[part 2 of 3: package /AR_SIGNALER_SWC]
AUTOSAR XML (schema 3.1.1)
package /AR_SIGNALER_SWC
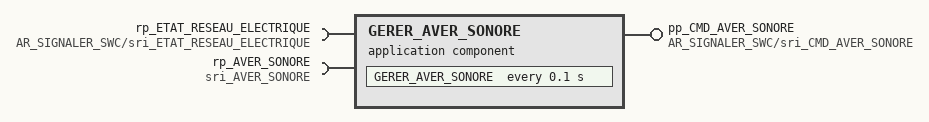
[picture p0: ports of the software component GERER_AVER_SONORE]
  application software component type GERER_AVER_SONORE
    require port rp_ETAT_RESEAU_ELECTRIQUE: unqueued-receiver-com-spec{data-element=sri_ETAT_RESEAU_ELECTRIQUE/ETAT_RESEAU_ELECTRIQUE, handle-invalid=KEEP, init-value=cst_UInt8_init/uint8_init, resync-time=0.0}, required-interface=AR_SIGNALER_SWC/sri_ETAT_RESEAU_ELECTRIQUE
    require port rp_AVER_SONORE: unqueued-receiver-com-spec{data-element=AVER_SONORE, handle-invalid=KEEP, init-value=cst_Boolean_init/boolean_init, resync-time=0.0}, required-interface=sri_AVER_SONORE
    provide port pp_CMD_AVER_SONORE: unqueued-sender-com-spec{data-element=sri_CMD_AVER_SONORE/CMD_AVER_SONORE, init-value=cst_Boolean_init/boolean_init}, provided-interface=AR_SIGNALER_SWC/sri_CMD_AVER_SONORE
  composition type SIGNALER_S1
    require port rp_ETAT_RESEAU_ELECTRIQUE: unqueued-receiver-com-spec{data-element=sri_ETAT_RESEAU_ELECTRIQUE/ETAT_RESEAU_ELECTRIQUE, handle-invalid=KEEP, init-value=cst_UInt8_init/uint8_init, resync-time=0.0}, required-interface=AR_SIGNALER_SWC/sri_ETAT_RESEAU_ELECTRIQUE
    require port rp_AVER_SONORE: unqueued-receiver-com-spec{data-element=AVER_SONORE, handle-invalid=KEEP, init-value=cst_Boolean_init/boolean_init, resync-time=0.0}, required-interface=sri_AVER_SONORE
    provide port pp_CMD_AVER_SONORE: unqueued-sender-com-spec{data-element=sri_CMD_AVER_SONORE/CMD_AVER_SONORE, init-value=cst_Boolean_init/boolean_init}, provided-interface=AR_SIGNALER_SWC/sri_CMD_AVER_SONORE
    6 x require port:
      rp_TYPE_DE_BOITE: unqueued-receiver-com-spec{data-element=TYPE_DE_BOITE, handle-invalid=KEEP, init-value=cst_UInt8_init/uint8_init, resync-time=0.0}, required-interface=sri_TYPE_DE_BOITE
      rp_SECU_FEUX_STOP_PAR_CTC_FREIN2: unqueued-receiver-com-spec{data-element=SECU_FEUX_STOP_PAR_CTC_FREIN2, handle-invalid=KEEP, init-value=cst_Boolean_init/boolean_init, resync-time=0.0}, required-interface=sri_SECU_FEUX_STOP_PAR_CTC_FREIN2
      rp_ETAT_PRINCIP_SEV: unqueued-receiver-com-spec{data-element=sri_ETAT_PRINCIP_SEV/ETAT_PRINCIP_SEV, handle-invalid=KEEP, init-value=cst_UInt8_init/uint8_init, resync-time=0.0}, required-interface=AR_SIGNALER_SWC/sri_ETAT_PRINCIP_SEV
      rp_APPUI_PEDALE_FREIN: unqueued-receiver-com-spec{data-element=APPUI_PEDALE_FREIN, handle-invalid=KEEP, init-value=cst_Boolean_init/boolean_init, resync-time=0.0}, required-interface=sri_APPUI_PEDALE_FREIN
      rp_CONTACT_FREIN2: unqueued-receiver-com-spec{data-element=CONTACT_FREIN2, handle-invalid=KEEP, init-value=cst_Boolean_init/boolean_init, resync-time=0.0}, required-interface=sri_CONTACT_FREIN2
      rp_CDE_APC: unqueued-receiver-com-spec{data-element=sri_CDE_APC/CDE_APC, handle-invalid=KEEP, init-value=cst_Boolean_init/boolean_init, resync-time=0.0}, required-interface=AR_SIGNALER_SWC/sri_CDE_APC
    provide port pp_CMD_FEUX_STOP: unqueued-sender-com-spec{data-element=CMD_FEUX_STOP, init-value=cst_Boolean_init/boolean_init}, provided-interface=sri_CMD_FEUX_STOP
    require port rp_ETAT_MA: unqueued-receiver-com-spec{data-element=ETAT_MA, handle-invalid=KEEP, init-value=cst_Boolean_init/boolean_init, resync-time=0.0}, required-interface=sri_ETAT_MA
    provide port pp_CMD_FEUX_MAR: unqueued-sender-com-spec{data-element=CMD_FEUX_MAR, init-value=cst_Boolean_init/boolean_init}, provided-interface=sri_CMD_FEUX_MAR
    component GERER_AVER_SONORE: type=GERER_AVER_SONORE
    component GERER_FX_STOP: type=GERER_FX_STOP
    component GERER_FX_MA: type=GERER_FX_MA
    delegate GERER_AVER_SONORE.rp_ETAT_RESEAU_ELECTRIQUE <-> outer port SIGNALER_S1/rp_ETAT_RESEAU_ELECTRIQUE
    delegate GERER_AVER_SONORE.rp_AVER_SONORE <-> outer port SIGNALER_S1/rp_AVER_SONORE
    delegate GERER_AVER_SONORE.pp_CMD_AVER_SONORE <-> outer port SIGNALER_S1/pp_CMD_AVER_SONORE
    delegate GERER_FX_STOP.rp_ETAT_PRINCIP_SEV <-> outer port SIGNALER_S1/rp_ETAT_PRINCIP_SEV
    delegate GERER_FX_STOP.rp_ETAT_RESEAU_ELECTRIQUE <-> outer port SIGNALER_S1/rp_ETAT_RESEAU_ELECTRIQUE
    delegate GERER_FX_STOP.rp_APPUI_PEDALE_FREIN <-> outer port SIGNALER_S1/rp_APPUI_PEDALE_FREIN
    delegate GERER_FX_STOP.rp_SECU_FEUX_STOP_PAR_CTC_FREIN2 <-> outer port SIGNALER_S1/rp_SECU_FEUX_STOP_PAR_CTC_FREIN2
    delegate GERER_FX_STOP.rp_CONTACT_FREIN2 <-> outer port SIGNALER_S1/rp_CONTACT_FREIN2
    delegate GERER_FX_STOP.rp_CDE_APC <-> outer port SIGNALER_S1/rp_CDE_APC
    delegate GERER_FX_STOP.pp_CMD_FEUX_STOP <-> outer port SIGNALER_S1/pp_CMD_FEUX_STOP
    delegate GERER_FX_MA.rp_ETAT_PRINCIP_SEV <-> outer port SIGNALER_S1/rp_ETAT_PRINCIP_SEV
    delegate GERER_FX_MA.rp_ETAT_RESEAU_ELECTRIQUE <-> outer port SIGNALER_S1/rp_ETAT_RESEAU_ELECTRIQUE
    delegate GERER_FX_MA.rp_TYPE_DE_BOITE <-> outer port SIGNALER_S1/rp_TYPE_DE_BOITE
    delegate GERER_FX_MA.rp_ETAT_MA <-> outer port SIGNALER_S1/rp_ETAT_MA
    delegate GERER_FX_MA.pp_CMD_FEUX_MAR <-> outer port SIGNALER_S1/pp_CMD_FEUX_MAR
  composition type SIGNALER
    4 x require port:
      rp_ETAT_PRINCIP_SEV: unqueued-receiver-com-spec{data-element=sri_ETAT_PRINCIP_SEV/ETAT_PRINCIP_SEV, handle-invalid=KEEP, init-value=cst_UInt8_init/uint8_init, resync-time=0.0}, required-interface=AR_SIGNALER_SWC/sri_ETAT_PRINCIP_SEV
      rp_ETAT_RESEAU_ELECTRIQUE: unqueued-receiver-com-spec{data-element=sri_ETAT_RESEAU_ELECTRIQUE/ETAT_RESEAU_ELECTRIQUE, handle-invalid=KEEP, init-value=cst_UInt8_init/uint8_init, resync-time=0.0}, required-interface=AR_SIGNALER_SWC/sri_ETAT_RESEAU_ELECTRIQUE
      rp_CDE_APC: unqueued-receiver-com-spec{data-element=sri_CDE_APC/CDE_APC, handle-invalid=KEEP, init-value=cst_Boolean_init/boolean_init, resync-time=0.0}, required-interface=AR_SIGNALER_SWC/sri_CDE_APC
      rp_AVER_SONORE: unqueued-receiver-com-spec{data-element=AVER_SONORE, handle-invalid=KEEP, init-value=cst_Boolean_init/boolean_init, resync-time=0.0}, required-interface=sri_AVER_SONORE
    provide port pp_CMD_AVER_SONORE: unqueued-sender-com-spec{data-element=sri_CMD_AVER_SONORE/CMD_AVER_SONORE, init-value=cst_Boolean_init/boolean_init}, provided-interface=AR_SIGNALER_SWC/sri_CMD_AVER_SONORE
    4 x require port:
      rp_DMD_LOCAL_TELECMD: unqueued-receiver-com-spec{data-element=sri_DMD_LOCAL_TELECMD/DMD_LOCAL_TELECMD, handle-invalid=KEEP, init-value=cst_Boolean_init/boolean_init, resync-time=0.0}, required-interface=AR_SIGNALER_SWC/sri_DMD_LOCAL_TELECMD
      rp_ETAT_CPO_COND: unqueued-receiver-com-spec{data-element=sri_ETAT_CPO_COND/ETAT_CPO_COND, handle-invalid=KEEP, init-value=cst_Boolean_init/boolean_init, resync-time=0.0}, required-interface=AR_SIGNALER_SWC/sri_ETAT_CPO_COND
      rp_ETAT_CONDA: unqueued-receiver-com-spec{data-element=sri_ETAT_CONDA/ETAT_CONDA, handle-invalid=KEEP, init-value=cst_UInt8_init/uint8_init, resync-time=0.0}, required-interface=AR_SIGNALER_SWC/sri_ETAT_CONDA
      rp_TYPE_CONDA: unqueued-receiver-com-spec{data-element=sri_TYPE_CONDA/TYPE_CONDA, handle-invalid=KEEP, init-value=cst_UInt8_init/uint8_init, resync-time=0.0}, required-interface=AR_SIGNALER_SWC/sri_TYPE_CONDA
    provide port pp_ETAT_FEUX_DETRESSE: unqueued-sender-com-spec{data-element=sri_ETAT_FEUX_DETRESSE/ETAT_FEUX_DETRESSE, init-value=cst_Boolean_init/boolean_init}, provided-interface=AR_SIGNALER_SWC/sri_ETAT_FEUX_DETRESSE
    provide port pp_ETAT_FEUX_DIURNES: unqueued-sender-com-spec{data-element=sri_ETAT_FEUX_DIURNES/ETAT_FEUX_DIURNES, init-value=cst_Boolean_init/boolean_init}, provided-interface=AR_SIGNALER_SWC/sri_ETAT_FEUX_DIURNES
    provide port pp_ETAT_FEUX_POSITION: unqueued-sender-com-spec{data-element=sri_ETAT_FEUX_POSITION/ETAT_FEUX_POSITION, init-value=cst_Boolean_init/boolean_init}, provided-interface=AR_SIGNALER_SWC/sri_ETAT_FEUX_POSITION
    6 x require port:
      rp_APPUI_PEDALE_FREIN: unqueued-receiver-com-spec{data-element=APPUI_PEDALE_FREIN, handle-invalid=KEEP, init-value=cst_Boolean_init/boolean_init, resync-time=0.0}, required-interface=sri_APPUI_PEDALE_FREIN
      rp_DMD_FEUX_DETRESSE: unqueued-receiver-com-spec{data-element=DMD_FEUX_DETRESSE, handle-invalid=KEEP, init-value=cst_Boolean_init/boolean_init, resync-time=0.0}, required-interface=sri_DMD_FEUX_DETRESSE
      rp_DIAG_CLIGNO_AVD: unqueued-receiver-com-spec{data-element=DIAG_CLIGNO_AVD, handle-invalid=KEEP, init-value=cst_UInt8_init/uint8_init, resync-time=0.0}, required-interface=sri_DIAG_CLIGNO_AVD
      rp_DIAG_CLIGNO_ARD: unqueued-receiver-com-spec{data-element=DIAG_CLIGNO_ARD, handle-invalid=KEEP, init-value=cst_UInt8_init/uint8_init, resync-time=0.0}, required-interface=sri_DIAG_CLIGNO_ARD
      rp_DIAG_CLIGNO_AVG: unqueued-receiver-com-spec{data-element=DIAG_CLIGNO_AVG, handle-invalid=KEEP, init-value=cst_UInt8_init/uint8_init, resync-time=0.0}, required-interface=sri_DIAG_CLIGNO_AVG
      rp_DIAG_CLIGNO_ARG: unqueued-receiver-com-spec{data-element=DIAG_CLIGNO_ARG, handle-invalid=KEEP, init-value=cst_UInt8_init/uint8_init, resync-time=0.0}, required-interface=sri_DIAG_CLIGNO_ARG
    16 x provide port:
      pp_PILOTAGE_CLIGNO_AVG: unqueued-sender-com-spec{data-element=PILOTAGE_CLIGNO_AVG, init-value=cst_Boolean_init/boolean_init}, provided-interface=sri_PILOTAGE_CLIGNO_AVG
      pp_PILOTAGE_CLIGNO_AVD: unqueued-sender-com-spec{data-element=PILOTAGE_CLIGNO_AVD, init-value=cst_Boolean_init/boolean_init}, provided-interface=sri_PILOTAGE_CLIGNO_AVD
      pp_P_LED_SIGN_PUSH_FEU_DET: unqueued-sender-com-spec{data-element=P_LED_SIGN_PUSH_FEU_DET, init-value=cst_Boolean_init/boolean_init}, provided-interface=sri_P_LED_SIGN_PUSH_FEU_DET
      pp_CMD_CLIGNO_ARG: unqueued-sender-com-spec{data-element=CMD_CLIGNO_ARG, init-value=cst_Boolean_init/boolean_init}, provided-interface=sri_CMD_CLIGNO_ARG
      pp_CMD_CLIGNO_ARD: unqueued-sender-com-spec{data-element=CMD_CLIGNO_ARD, init-value=cst_Boolean_init/boolean_init}, provided-interface=sri_CMD_CLIGNO_ARD
      pp_ETAT_CLIGNOTANT_G: unqueued-sender-com-spec{data-element=sri_ETAT_CLIGNOTANT_G/ETAT_CLIGNOTANT_G, init-value=cst_Boolean_init/boolean_init}, provided-interface=AR_SIGNALER_SWC/sri_ETAT_CLIGNOTANT_G
      pp_ETAT_CLIGNOTANT_D: unqueued-sender-com-spec{data-element=sri_ETAT_CLIGNOTANT_D/ETAT_CLIGNOTANT_D, init-value=cst_Boolean_init/boolean_init}, provided-interface=AR_SIGNALER_SWC/sri_ETAT_CLIGNOTANT_D
      pp_P_SON_SIGN_FX_CLIGNO_CLIC: unqueued-sender-com-spec{data-element=sri_P_SON_SIGN_FX_CLIGNO_CLIC/P_SON_SIGN_FX_CLIGNO_CLIC, init-value=cst_Boolean_init/boolean_init}, provided-interface=AR_SIGNALER_SWC/sri_P_SON_SIGN_FX_CLIGNO_CLIC
      pp_P_SON_SIGN_FX_CLIGNO_CLAC: unqueued-sender-com-spec{data-element=sri_P_SON_SIGN_FX_CLIGNO_CLAC/P_SON_SIGN_FX_CLIGNO_CLAC, init-value=cst_Boolean_init/boolean_init}, provided-interface=AR_SIGNALER_SWC/sri_P_SON_SIGN_FX_CLIGNO_CLAC
      pp_P_SON_SIGN_FX_CLIGNO_CLIC_R: unqueued-sender-com-spec{data-element=sri_P_SON_SIGN_FX_CLIGNO_CLIC_R/P_SON_SIGN_FX_CLIGNO_CLIC_R, init-value=cst_Boolean_init/boolean_init}, provided-interface=AR_SIGNALER_SWC/sri_P_SON_SIGN_FX_CLIGNO_CLIC_R
      pp_P_SON_SIGN_FX_CLIGNO_CLAC_R: unqueued-sender-com-spec{data-element=sri_P_SON_SIGN_FX_CLIGNO_CLAC_R/P_SON_SIGN_FX_CLIGNO_CLAC_R, init-value=cst_Boolean_init/boolean_init}, provided-interface=AR_SIGNALER_SWC/sri_P_SON_SIGN_FX_CLIGNO_CLAC_R
      pp_P_SON_SIGN_FX_CLIGNO_CLIC_REL: unqueued-sender-com-spec{data-element=sri_P_SON_SIGN_FX_CLIGNO_CLIC_REL/P_SON_SIGN_FX_CLIGNO_CLIC_REL, init-value=cst_Boolean_init/boolean_init}, provided-interface=AR_SIGNALER_SWC/sri_P_SON_SIGN_FX_CLIGNO_CLIC_REL
      pp_P_SON_SIGN_FX_CLIGNO_CLAC_REL: unqueued-sender-com-spec{data-element=sri_P_SON_SIGN_FX_CLIGNO_CLAC_REL/P_SON_SIGN_FX_CLIGNO_CLAC_REL, init-value=cst_Boolean_init/boolean_init}, provided-interface=AR_SIGNALER_SWC/sri_P_SON_SIGN_FX_CLIGNO_CLAC_REL
      pp_P_SON_SIGN_FX_CLIGNO_CLIC_R_REL: unqueued-sender-com-spec{data-element=sri_P_SON_SIGN_FX_CLIGNO_CLIC_R_REL/P_SON_SIGN_FX_CLIGNO_CLIC_R_REL, init-value=cst_Boolean_init/boolean_init}, provided-interface=AR_SIGNALER_SWC/sri_P_SON_SIGN_FX_CLIGNO_CLIC_R_REL
      pp_P_SON_SIGN_FX_CLIGNO_CLAC_R_REL: unqueued-sender-com-spec{data-element=sri_P_SON_SIGN_FX_CLIGNO_CLAC_R_REL/P_SON_SIGN_FX_CLIGNO_CLAC_R_REL, init-value=cst_Boolean_init/boolean_init}, provided-interface=AR_SIGNALER_SWC/sri_P_SON_SIGN_FX_CLIGNO_CLAC_R_REL
      pp_P_SON_SIGN_OUBLI_FEUX: unqueued-sender-com-spec{data-element=sri_P_SON_SIGN_OUBLI_FEUX/P_SON_SIGN_OUBLI_FEUX, init-value=cst_Boolean_init/boolean_init}, provided-interface=AR_SIGNALER_SWC/sri_P_SON_SIGN_OUBLI_FEUX
    require port rp_DMD_ALLUMAGE_FEUX_POSITION: unqueued-receiver-com-spec{data-element=DMD_ALLUMAGE_FEUX_POSITION, handle-invalid=KEEP, init-value=cst_Boolean_init/boolean_init, resync-time=0.0}, required-interface=sri_DMD_ALLUMAGE_FEUX_POSITION
    provide port pp_PILOTAGE_FEU_DIURNE_DEDIE_D: unqueued-sender-com-spec{data-element=PILOTAGE_FEU_DIURNE_DEDIE_D, init-value=cst_Boolean_init/boolean_init}, provided-interface=sri_PILOTAGE_FEU_DIURNE_DEDIE_D
    provide port pp_PILOTAGE_FEU_DIURNE_DEDIE_G: unqueued-sender-com-spec{data-element=PILOTAGE_FEU_DIURNE_DEDIE_G, init-value=cst_Boolean_init/boolean_init}, provided-interface=sri_PILOTAGE_FEU_DIURNE_DEDIE_G
    provide port pp_P_TEM_SIGN_FX_DIURNES: unqueued-sender-com-spec{data-element=P_TEM_SIGN_FX_DIURNES, init-value=cst_Boolean_init/boolean_init}, provided-interface=sri_P_TEM_SIGN_FX_DIURNES
    4 x require port:
      rp_VITESSE_LONGITUDINALE: unqueued-receiver-com-spec{data-element=sri_VITESSE_LONGITUDINALE/VITESSE_LONGITUDINALE, handle-invalid=KEEP, init-value=cst_UInt16_init/uint16_init, resync-time=0.0}, required-interface=AR_SIGNALER_SWC/sri_VITESSE_LONGITUDINALE
      rp_ETAT_ANTIBR_AV: unqueued-receiver-com-spec{data-element=ETAT_ANTIBR_AV, handle-invalid=KEEP, init-value=cst_Boolean_init/boolean_init, resync-time=0.0}, required-interface=sri_ETAT_ANTIBR_AV
      rp_DMD_FEUX_CROISEMENT_AAF: unqueued-receiver-com-spec{data-element=DMD_FEUX_CROISEMENT_AAF, handle-invalid=KEEP, init-value=cst_Boolean_init/boolean_init, resync-time=0.0}, required-interface=sri_DMD_FEUX_CROISEMENT_AAF
      rp_TYPE_REVEIL_BAGUE_ECLAIRAGE: unqueued-receiver-com-spec{data-element=TYPE_REVEIL_BAGUE_ECLAIRAGE, handle-invalid=KEEP, init-value=cst_Boolean_init/boolean_init, resync-time=0.0}, required-interface=sri_TYPE_REVEIL_BAGUE_ECLAIRAGE
    7 x provide port:
      pp_PILOTAGE_FEUX_POSITION_AVD: unqueued-sender-com-spec{data-element=PILOTAGE_FEUX_POSITION_AVD, init-value=cst_Boolean_init/boolean_init}, provided-interface=sri_PILOTAGE_FEUX_POSITION_AVD
      pp_PILOTAGE_FEUX_POSITION_AVG: unqueued-sender-com-spec{data-element=PILOTAGE_FEUX_POSITION_AVG, init-value=cst_Boolean_init/boolean_init}, provided-interface=sri_PILOTAGE_FEUX_POSITION_AVG
      pp_CMD_FEUX_POSITION_AR: unqueued-sender-com-spec{data-element=CMD_FEUX_POSITION_AR, init-value=cst_UInt8_init/uint8_init}, provided-interface=sri_CMD_FEUX_POSITION_AR
      pp_P_TEM_SIGN_FX_POS: unqueued-sender-com-spec{data-element=P_TEM_SIGN_FX_POS, init-value=cst_Boolean_init/boolean_init}, provided-interface=sri_P_TEM_SIGN_FX_POS
      pp_DMD_ALLUMAGE_FEUX_CROISEMENT: unqueued-sender-com-spec{data-element=DMD_ALLUMAGE_FEUX_CROISEMENT, init-value=cst_Boolean_init/boolean_init}, provided-interface=sri_DMD_ALLUMAGE_FEUX_CROISEMENT
      pp_P_TEM_SIGN_FX_CLIGNO_G: unqueued-sender-com-spec{data-element=P_TEM_SIGN_FX_CLIGNO_G, init-value=cst_Boolean_init/boolean_init}, provided-interface=sri_P_TEM_SIGN_FX_CLIGNO_G
      pp_P_TEM_SIGN_FX_CLIGNO_D: unqueued-sender-com-spec{data-element=P_TEM_SIGN_FX_CLIGNO_D, init-value=cst_Boolean_init/boolean_init}, provided-interface=sri_P_TEM_SIGN_FX_CLIGNO_D
    require port rp_ETAT_COMMODO_ECLAIRAGE_4POS: unqueued-receiver-com-spec{data-element=ETAT_COMMODO_ECLAIRAGE_4POS, handle-invalid=KEEP, init-value=cst_UInt8_init/uint8_init, resync-time=0.0}, required-interface=sri_ETAT_COMMODO_ECLAIRAGE_4POS
    provide port pp_ETAT_CMD_ECLAIRAGE: unqueued-sender-com-spec{data-element=ETAT_CMD_ECLAIRAGE, init-value=cst_UInt8_init/uint8_init}, provided-interface=sri_ETAT_CMD_ECLAIRAGE
    provide port pp_ETAT_FEUX_DIRECTION: unqueued-sender-com-spec{data-element=ETAT_FEUX_DIRECTION, init-value=cst_UInt8_init/uint8_init}, provided-interface=sri_ETAT_FEUX_DIRECTION
    require port rp_CONTACT_FREIN2: unqueued-receiver-com-spec{data-element=CONTACT_FREIN2, handle-invalid=KEEP, init-value=cst_Boolean_init/boolean_init, resync-time=0.0}, required-interface=sri_CONTACT_FREIN2
    provide port pp_CMD_FEUX_STOP: unqueued-sender-com-spec{data-element=CMD_FEUX_STOP, init-value=cst_Boolean_init/boolean_init}, provided-interface=sri_CMD_FEUX_STOP
    require port rp_ETAT_DMD_ANTIBROUILLARD: unqueued-receiver-com-spec{data-element=ETAT_DMD_ANTIBROUILLARD, handle-invalid=KEEP, init-value=cst_UInt8_init/uint8_init, resync-time=0.0}, required-interface=sri_ETAT_DMD_ANTIBROUILLARD
    provide port pp_DMD_ANTIBROUILLARD: unqueued-sender-com-spec{data-element=DMD_ANTIBROUILLARD, init-value=cst_UInt8_init/uint8_init}, provided-interface=sri_DMD_ANTIBROUILLARD
    require port rp_ETAT_MA: unqueued-receiver-com-spec{data-element=ETAT_MA, handle-invalid=KEEP, init-value=cst_Boolean_init/boolean_init, resync-time=0.0}, required-interface=sri_ETAT_MA
    provide port pp_CMD_FEUX_MAR: unqueued-sender-com-spec{data-element=CMD_FEUX_MAR, init-value=cst_Boolean_init/boolean_init}, provided-interface=sri_CMD_FEUX_MAR
    provide port pp_ETAT_JOUR_NUIT: unqueued-sender-com-spec{data-element=ETAT_JOUR_NUIT, init-value=cst_Boolean_init/boolean_init}, provided-interface=sri_ETAT_JOUR_NUIT
    9 x require port:
      rp_ETAT_CONDA_OUV_AR: unqueued-receiver-com-spec{data-element=ETAT_CONDA_OUV_AR, handle-invalid=KEEP, init-value=cst_Boolean_init/boolean_init, resync-time=0.0}, required-interface=sri_ETAT_CONDA_OUV_AR
      rp_CHOC_FEUX_DET: unqueued-receiver-com-spec{data-element=CHOC_FEUX_DET, handle-invalid=KEEP, init-value=cst_Boolean_init/boolean_init, resync-time=0.0}, required-interface=sri_CHOC_FEUX_DET
      rp_INFO_CHOC_PIETON: unqueued-receiver-com-spec{data-element=INFO_CHOC_PIETON, handle-invalid=KEEP, init-value=cst_Boolean_init/boolean_init, resync-time=0.0}, required-interface=sri_INFO_CHOC_PIETON
      rp_VOLONTE_CONDUCTEUR: unqueued-receiver-com-spec{data-element=VOLONTE_CONDUCTEUR, handle-invalid=KEEP, init-value=cst_UInt8_init/uint8_init, resync-time=0.0}, required-interface=sri_VOLONTE_CONDUCTEUR
      rp_DMD_WARNING_FORTE_DECEL: unqueued-receiver-com-spec{data-element=DMD_WARNING_FORTE_DECEL, handle-invalid=KEEP, init-value=cst_Boolean_init/boolean_init, resync-time=0.0}, required-interface=sri_DMD_WARNING_FORTE_DECEL
      rp_ETAT_COMMODO_CLIGNO: unqueued-receiver-com-spec{data-element=ETAT_COMMODO_CLIGNO, handle-invalid=KEEP, init-value=cst_UInt8_init/uint8_init, resync-time=0.0}, required-interface=sri_ETAT_COMMODO_CLIGNO
      rp_FNCT_SFU_UC_FREIN: unqueued-receiver-com-spec{data-element=sri_FNCT_SFU_UC_FREIN/FNCT_SFU_UC_FREIN, handle-invalid=KEEP, init-value=cst_Boolean_init/boolean_init, resync-time=0.0}, required-interface=sri_FNCT_SFU_UC_FREIN
      rp_ETAT_FEUX_CROISEMENT: unqueued-receiver-com-spec{data-element=ETAT_FEUX_CROISEMENT, handle-invalid=KEEP, init-value=cst_Boolean_init/boolean_init, resync-time=0.0}, required-interface=sri_ETAT_FEUX_CROISEMENT
      rp_ETAT_FEUX_ROUTE: unqueued-receiver-com-spec{data-element=ETAT_FEUX_ROUTE, handle-invalid=KEEP, init-value=cst_Boolean_init/boolean_init, resync-time=0.0}, required-interface=sri_ETAT_FEUX_ROUTE
    provide port pp_CMD_ANTIBR_AR: unqueued-sender-com-spec{data-element=CMD_ANTIBR_AR, init-value=cst_Boolean_init/boolean_init}, provided-interface=sri_CMD_ANTIBR_AR
    provide port pp_ETAT_ANTIBR_AR: unqueued-sender-com-spec{data-element=ETAT_ANTIBR_AR, init-value=cst_Boolean_init/boolean_init}, provided-interface=sri_ETAT_ANTIBR_AR
    provide port pp_P_TEM_SIGN_FX_ABAR: unqueued-sender-com-spec{data-element=P_TEM_SIGN_FX_ABAR, init-value=cst_Boolean_init/boolean_init}, provided-interface=sri_P_TEM_SIGN_FX_ABAR
    component MDL_SIGNALER: type=MDL_SIGNALER
    delegate MDL_SIGNALER.rp_ETAT_RESEAU_ELECTRIQUE <-> outer port SIGNALER/rp_ETAT_RESEAU_ELECTRIQUE
    delegate MDL_SIGNALER.rp_AVER_SONORE <-> outer port SIGNALER/rp_AVER_SONORE
    delegate MDL_SIGNALER.pp_CMD_AVER_SONORE <-> outer port SIGNALER/pp_CMD_AVER_SONORE
    delegate MDL_SIGNALER.rp_ETAT_PRINCIP_SEV <-> outer port SIGNALER/rp_ETAT_PRINCIP_SEV
    delegate MDL_SIGNALER.rp_DMD_ALLUMAGE_FEUX_POSITION <-> outer port SIGNALER/rp_DMD_ALLUMAGE_FEUX_POSITION
    delegate MDL_SIGNALER.pp_PILOTAGE_FEU_DIURNE_DEDIE_D <-> outer port SIGNALER/pp_PILOTAGE_FEU_DIURNE_DEDIE_D
    delegate MDL_SIGNALER.pp_PILOTAGE_FEU_DIURNE_DEDIE_G <-> outer port SIGNALER/pp_PILOTAGE_FEU_DIURNE_DEDIE_G
    delegate MDL_SIGNALER.pp_ETAT_FEUX_DIURNES <-> outer port SIGNALER/pp_ETAT_FEUX_DIURNES
    delegate MDL_SIGNALER.pp_P_TEM_SIGN_FX_DIURNES <-> outer port SIGNALER/pp_P_TEM_SIGN_FX_DIURNES
    delegate MDL_SIGNALER.rp_VITESSE_LONGITUDINALE <-> outer port SIGNALER/rp_VITESSE_LONGITUDINALE
    delegate MDL_SIGNALER.rp_ETAT_ANTIBR_AV <-> outer port SIGNALER/rp_ETAT_ANTIBR_AV
    delegate MDL_SIGNALER.rp_DMD_FEUX_CROISEMENT_AAF <-> outer port SIGNALER/rp_DMD_FEUX_CROISEMENT_AAF
    delegate MDL_SIGNALER.rp_ETAT_CPO_COND <-> outer port SIGNALER/rp_ETAT_CPO_COND
    delegate MDL_SIGNALER.rp_TYPE_REVEIL_BAGUE_ECLAIRAGE <-> outer port SIGNALER/rp_TYPE_REVEIL_BAGUE_ECLAIRAGE
    delegate MDL_SIGNALER.pp_PILOTAGE_FEUX_POSITION_AVD <-> outer port SIGNALER/pp_PILOTAGE_FEUX_POSITION_AVD
    delegate MDL_SIGNALER.pp_PILOTAGE_FEUX_POSITION_AVG <-> outer port SIGNALER/pp_PILOTAGE_FEUX_POSITION_AVG
    delegate MDL_SIGNALER.pp_CMD_FEUX_POSITION_AR <-> outer port SIGNALER/pp_CMD_FEUX_POSITION_AR
    delegate MDL_SIGNALER.pp_ETAT_FEUX_POSITION <-> outer port SIGNALER/pp_ETAT_FEUX_POSITION
    delegate MDL_SIGNALER.pp_P_TEM_SIGN_FX_POS <-> outer port SIGNALER/pp_P_TEM_SIGN_FX_POS
    delegate MDL_SIGNALER.pp_DMD_ALLUMAGE_FEUX_CROISEMENT <-> outer port SIGNALER/pp_DMD_ALLUMAGE_FEUX_CROISEMENT
    delegate MDL_SIGNALER.pp_P_SON_SIGN_OUBLI_FEUX <-> outer port SIGNALER/pp_P_SON_SIGN_OUBLI_FEUX
    delegate MDL_SIGNALER.pp_P_TEM_SIGN_FX_CLIGNO_G <-> outer port SIGNALER/pp_P_TEM_SIGN_FX_CLIGNO_G
    delegate MDL_SIGNALER.pp_P_TEM_SIGN_FX_CLIGNO_D <-> outer port SIGNALER/pp_P_TEM_SIGN_FX_CLIGNO_D
    delegate MDL_SIGNALER.pp_P_SON_SIGN_FX_CLIGNO_CLIC <-> outer port SIGNALER/pp_P_SON_SIGN_FX_CLIGNO_CLIC
    delegate MDL_SIGNALER.pp_P_SON_SIGN_FX_CLIGNO_CLAC <-> outer port SIGNALER/pp_P_SON_SIGN_FX_CLIGNO_CLAC
    delegate MDL_SIGNALER.pp_P_SON_SIGN_FX_CLIGNO_CLIC_R <-> outer port SIGNALER/pp_P_SON_SIGN_FX_CLIGNO_CLIC_R
    delegate MDL_SIGNALER.pp_P_SON_SIGN_FX_CLIGNO_CLAC_R <-> outer port SIGNALER/pp_P_SON_SIGN_FX_CLIGNO_CLAC_R
    delegate MDL_SIGNALER.pp_PILOTAGE_CLIGNO_AVG <-> outer port SIGNALER/pp_PILOTAGE_CLIGNO_AVG
    delegate MDL_SIGNALER.pp_PILOTAGE_CLIGNO_AVD <-> outer port SIGNALER/pp_PILOTAGE_CLIGNO_AVD
    delegate MDL_SIGNALER.pp_P_SON_SIGN_FX_CLIGNO_CLIC_REL <-> outer port SIGNALER/pp_P_SON_SIGN_FX_CLIGNO_CLIC_REL
    delegate MDL_SIGNALER.pp_P_SON_SIGN_FX_CLIGNO_CLAC_REL <-> outer port SIGNALER/pp_P_SON_SIGN_FX_CLIGNO_CLAC_REL
    delegate MDL_SIGNALER.pp_P_SON_SIGN_FX_CLIGNO_CLIC_R_REL <-> outer port SIGNALER/pp_P_SON_SIGN_FX_CLIGNO_CLIC_R_REL
    delegate MDL_SIGNALER.pp_P_SON_SIGN_FX_CLIGNO_CLAC_R_REL <-> outer port SIGNALER/pp_P_SON_SIGN_FX_CLIGNO_CLAC_R_REL
    delegate MDL_SIGNALER.pp_CMD_CLIGNO_ARG <-> outer port SIGNALER/pp_CMD_CLIGNO_ARG
    delegate MDL_SIGNALER.pp_CMD_CLIGNO_ARD <-> outer port SIGNALER/pp_CMD_CLIGNO_ARD
    delegate MDL_SIGNALER.rp_DIAG_CLIGNO_AVD <-> outer port SIGNALER/rp_DIAG_CLIGNO_AVD
    delegate MDL_SIGNALER.rp_DIAG_CLIGNO_ARD <-> outer port SIGNALER/rp_DIAG_CLIGNO_ARD
    delegate MDL_SIGNALER.rp_DIAG_CLIGNO_AVG <-> outer port SIGNALER/rp_DIAG_CLIGNO_AVG
    delegate MDL_SIGNALER.rp_DIAG_CLIGNO_ARG <-> outer port SIGNALER/rp_DIAG_CLIGNO_ARG
    delegate MDL_SIGNALER.rp_ETAT_COMMODO_ECLAIRAGE_4POS <-> outer port SIGNALER/rp_ETAT_COMMODO_ECLAIRAGE_4POS
    delegate MDL_SIGNALER.pp_ETAT_CMD_ECLAIRAGE <-> outer port SIGNALER/pp_ETAT_CMD_ECLAIRAGE
    delegate MDL_SIGNALER.pp_ETAT_FEUX_DIRECTION <-> outer port SIGNALER/pp_ETAT_FEUX_DIRECTION
    delegate MDL_SIGNALER.pp_ETAT_FEUX_DETRESSE <-> outer port SIGNALER/pp_ETAT_FEUX_DETRESSE
    delegate MDL_SIGNALER.pp_ETAT_CLIGNOTANT_G <-> outer port SIGNALER/pp_ETAT_CLIGNOTANT_G
    delegate MDL_SIGNALER.pp_ETAT_CLIGNOTANT_D <-> outer port SIGNALER/pp_ETAT_CLIGNOTANT_D
    delegate MDL_SIGNALER.pp_P_LED_SIGN_PUSH_FEU_DET <-> outer port SIGNALER/pp_P_LED_SIGN_PUSH_FEU_DET
    delegate MDL_SIGNALER.rp_APPUI_PEDALE_FREIN <-> outer port SIGNALER/rp_APPUI_PEDALE_FREIN
    delegate MDL_SIGNALER.rp_CONTACT_FREIN2 <-> outer port SIGNALER/rp_CONTACT_FREIN2
    delegate MDL_SIGNALER.rp_CDE_APC <-> outer port SIGNALER/rp_CDE_APC
    delegate MDL_SIGNALER.pp_CMD_FEUX_STOP <-> outer port SIGNALER/pp_CMD_FEUX_STOP
    delegate MDL_SIGNALER.rp_ETAT_DMD_ANTIBROUILLARD <-> outer port SIGNALER/rp_ETAT_DMD_ANTIBROUILLARD
    delegate MDL_SIGNALER.pp_DMD_ANTIBROUILLARD <-> outer port SIGNALER/pp_DMD_ANTIBROUILLARD
    delegate MDL_SIGNALER.rp_ETAT_MA <-> outer port SIGNALER/rp_ETAT_MA
    delegate MDL_SIGNALER.pp_CMD_FEUX_MAR <-> outer port SIGNALER/pp_CMD_FEUX_MAR
    delegate MDL_SIGNALER.pp_ETAT_JOUR_NUIT <-> outer port SIGNALER/pp_ETAT_JOUR_NUIT
    delegate MDL_SIGNALER.rp_DMD_FEUX_DETRESSE <-> outer port SIGNALER/rp_DMD_FEUX_DETRESSE
    delegate MDL_SIGNALER.rp_ETAT_CONDA_OUV_AR <-> outer port SIGNALER/rp_ETAT_CONDA_OUV_AR
    delegate MDL_SIGNALER.rp_CHOC_FEUX_DET <-> outer port SIGNALER/rp_CHOC_FEUX_DET
    delegate MDL_SIGNALER.rp_INFO_CHOC_PIETON <-> outer port SIGNALER/rp_INFO_CHOC_PIETON
    delegate MDL_SIGNALER.rp_VOLONTE_CONDUCTEUR <-> outer port SIGNALER/rp_VOLONTE_CONDUCTEUR
    delegate MDL_SIGNALER.rp_DMD_WARNING_FORTE_DECEL <-> outer port SIGNALER/rp_DMD_WARNING_FORTE_DECEL
    delegate MDL_SIGNALER.rp_DMD_LOCAL_TELECMD <-> outer port SIGNALER/rp_DMD_LOCAL_TELECMD
    delegate MDL_SIGNALER.rp_ETAT_COMMODO_CLIGNO <-> outer port SIGNALER/rp_ETAT_COMMODO_CLIGNO
    delegate MDL_SIGNALER.rp_ETAT_CONDA <-> outer port SIGNALER/rp_ETAT_CONDA
    delegate MDL_SIGNALER.rp_TYPE_CONDA <-> outer port SIGNALER/rp_TYPE_CONDA
    delegate MDL_SIGNALER.rp_FNCT_SFU_UC_FREIN <-> outer port SIGNALER/rp_FNCT_SFU_UC_FREIN
    delegate MDL_SIGNALER.rp_ETAT_FEUX_CROISEMENT <-> outer port SIGNALER/rp_ETAT_FEUX_CROISEMENT
    delegate MDL_SIGNALER.rp_ETAT_FEUX_ROUTE <-> outer port SIGNALER/rp_ETAT_FEUX_ROUTE
    delegate MDL_SIGNALER.pp_CMD_ANTIBR_AR <-> outer port SIGNALER/pp_CMD_ANTIBR_AR
    delegate MDL_SIGNALER.pp_ETAT_ANTIBR_AR <-> outer port SIGNALER/pp_ETAT_ANTIBR_AR
    delegate MDL_SIGNALER.pp_P_TEM_SIGN_FX_ABAR <-> outer port SIGNALER/pp_P_TEM_SIGN_FX_ABAR
  composition type MDL_SIGNALER
    require port rp_ETAT_RESEAU_ELECTRIQUE: unqueued-receiver-com-spec{data-element=sri_ETAT_RESEAU_ELECTRIQUE/ETAT_RESEAU_ELECTRIQUE, handle-invalid=KEEP, init-value=cst_UInt8_init/uint8_init, resync-time=0.0}, required-interface=AR_SIGNALER_SWC/sri_ETAT_RESEAU_ELECTRIQUE
    require port rp_AVER_SONORE: unqueued-receiver-com-spec{data-element=AVER_SONORE, handle-invalid=KEEP, init-value=cst_Boolean_init/boolean_init, resync-time=0.0}, required-interface=sri_AVER_SONORE
    provide port pp_CMD_AVER_SONORE: unqueued-sender-com-spec{data-element=sri_CMD_AVER_SONORE/CMD_AVER_SONORE, init-value=cst_Boolean_init/boolean_init}, provided-interface=AR_SIGNALER_SWC/sri_CMD_AVER_SONORE
    require port rp_ETAT_PRINCIP_SEV: unqueued-receiver-com-spec{data-element=sri_ETAT_PRINCIP_SEV/ETAT_PRINCIP_SEV, handle-invalid=KEEP, init-value=cst_UInt8_init/uint8_init, resync-time=0.0}, required-interface=AR_SIGNALER_SWC/sri_ETAT_PRINCIP_SEV
    require port rp_DMD_ALLUMAGE_FEUX_POSITION: unqueued-receiver-com-spec{data-element=DMD_ALLUMAGE_FEUX_POSITION, handle-invalid=KEEP, init-value=cst_Boolean_init/boolean_init, resync-time=0.0}, required-interface=sri_DMD_ALLUMAGE_FEUX_POSITION
    4 x provide port:
      pp_PILOTAGE_FEU_DIURNE_DEDIE_D: unqueued-sender-com-spec{data-element=PILOTAGE_FEU_DIURNE_DEDIE_D, init-value=cst_Boolean_init/boolean_init}, provided-interface=sri_PILOTAGE_FEU_DIURNE_DEDIE_D
      pp_PILOTAGE_FEU_DIURNE_DEDIE_G: unqueued-sender-com-spec{data-element=PILOTAGE_FEU_DIURNE_DEDIE_G, init-value=cst_Boolean_init/boolean_init}, provided-interface=sri_PILOTAGE_FEU_DIURNE_DEDIE_G
      pp_ETAT_FEUX_DIURNES: unqueued-sender-com-spec{data-element=sri_ETAT_FEUX_DIURNES/ETAT_FEUX_DIURNES, init-value=cst_Boolean_init/boolean_init}, provided-interface=AR_SIGNALER_SWC/sri_ETAT_FEUX_DIURNES
      pp_P_TEM_SIGN_FX_DIURNES: unqueued-sender-com-spec{data-element=P_TEM_SIGN_FX_DIURNES, init-value=cst_Boolean_init/boolean_init}, provided-interface=sri_P_TEM_SIGN_FX_DIURNES
    5 x require port:
      rp_VITESSE_LONGITUDINALE: unqueued-receiver-com-spec{data-element=sri_VITESSE_LONGITUDINALE/VITESSE_LONGITUDINALE, handle-invalid=KEEP, init-value=cst_UInt16_init/uint16_init, resync-time=0.0}, required-interface=AR_SIGNALER_SWC/sri_VITESSE_LONGITUDINALE
      rp_ETAT_ANTIBR_AV: unqueued-receiver-com-spec{data-element=ETAT_ANTIBR_AV, handle-invalid=KEEP, init-value=cst_Boolean_init/boolean_init, resync-time=0.0}, required-interface=sri_ETAT_ANTIBR_AV
      rp_DMD_FEUX_CROISEMENT_AAF: unqueued-receiver-com-spec{data-element=DMD_FEUX_CROISEMENT_AAF, handle-invalid=KEEP, init-value=cst_Boolean_init/boolean_init, resync-time=0.0}, required-interface=sri_DMD_FEUX_CROISEMENT_AAF
      rp_ETAT_CPO_COND: unqueued-receiver-com-spec{data-element=sri_ETAT_CPO_COND/ETAT_CPO_COND, handle-invalid=KEEP, init-value=cst_Boolean_init/boolean_init, resync-time=0.0}, required-interface=AR_SIGNALER_SWC/sri_ETAT_CPO_COND
      rp_TYPE_REVEIL_BAGUE_ECLAIRAGE: unqueued-receiver-com-spec{data-element=TYPE_REVEIL_BAGUE_ECLAIRAGE, handle-invalid=KEEP, init-value=cst_Boolean_init/boolean_init, resync-time=0.0}, required-interface=sri_TYPE_REVEIL_BAGUE_ECLAIRAGE
    21 x provide port:
      pp_PILOTAGE_FEUX_POSITION_AVD: unqueued-sender-com-spec{data-element=PILOTAGE_FEUX_POSITION_AVD, init-value=cst_Boolean_init/boolean_init}, provided-interface=sri_PILOTAGE_FEUX_POSITION_AVD
      pp_PILOTAGE_FEUX_POSITION_AVG: unqueued-sender-com-spec{data-element=PILOTAGE_FEUX_POSITION_AVG, init-value=cst_Boolean_init/boolean_init}, provided-interface=sri_PILOTAGE_FEUX_POSITION_AVG
      pp_CMD_FEUX_POSITION_AR: unqueued-sender-com-spec{data-element=CMD_FEUX_POSITION_AR, init-value=cst_UInt8_init/uint8_init}, provided-interface=sri_CMD_FEUX_POSITION_AR
      pp_ETAT_FEUX_POSITION: unqueued-sender-com-spec{data-element=sri_ETAT_FEUX_POSITION/ETAT_FEUX_POSITION, init-value=cst_Boolean_init/boolean_init}, provided-interface=AR_SIGNALER_SWC/sri_ETAT_FEUX_POSITION
      pp_P_TEM_SIGN_FX_POS: unqueued-sender-com-spec{data-element=P_TEM_SIGN_FX_POS, init-value=cst_Boolean_init/boolean_init}, provided-interface=sri_P_TEM_SIGN_FX_POS
      pp_DMD_ALLUMAGE_FEUX_CROISEMENT: unqueued-sender-com-spec{data-element=DMD_ALLUMAGE_FEUX_CROISEMENT, init-value=cst_Boolean_init/boolean_init}, provided-interface=sri_DMD_ALLUMAGE_FEUX_CROISEMENT
      pp_P_SON_SIGN_OUBLI_FEUX: unqueued-sender-com-spec{data-element=sri_P_SON_SIGN_OUBLI_FEUX/P_SON_SIGN_OUBLI_FEUX, init-value=cst_Boolean_init/boolean_init}, provided-interface=AR_SIGNALER_SWC/sri_P_SON_SIGN_OUBLI_FEUX
      pp_P_TEM_SIGN_FX_CLIGNO_G: unqueued-sender-com-spec{data-element=P_TEM_SIGN_FX_CLIGNO_G, init-value=cst_Boolean_init/boolean_init}, provided-interface=sri_P_TEM_SIGN_FX_CLIGNO_G
      pp_P_TEM_SIGN_FX_CLIGNO_D: unqueued-sender-com-spec{data-element=P_TEM_SIGN_FX_CLIGNO_D, init-value=cst_Boolean_init/boolean_init}, provided-interface=sri_P_TEM_SIGN_FX_CLIGNO_D
      pp_P_SON_SIGN_FX_CLIGNO_CLIC: unqueued-sender-com-spec{data-element=sri_P_SON_SIGN_FX_CLIGNO_CLIC/P_SON_SIGN_FX_CLIGNO_CLIC, init-value=cst_Boolean_init/boolean_init}, provided-interface=AR_SIGNALER_SWC/sri_P_SON_SIGN_FX_CLIGNO_CLIC
      pp_P_SON_SIGN_FX_CLIGNO_CLAC: unqueued-sender-com-spec{data-element=sri_P_SON_SIGN_FX_CLIGNO_CLAC/P_SON_SIGN_FX_CLIGNO_CLAC, init-value=cst_Boolean_init/boolean_init}, provided-interface=AR_SIGNALER_SWC/sri_P_SON_SIGN_FX_CLIGNO_CLAC
      pp_P_SON_SIGN_FX_CLIGNO_CLIC_R: unqueued-sender-com-spec{data-element=sri_P_SON_SIGN_FX_CLIGNO_CLIC_R/P_SON_SIGN_FX_CLIGNO_CLIC_R, init-value=cst_Boolean_init/boolean_init}, provided-interface=AR_SIGNALER_SWC/sri_P_SON_SIGN_FX_CLIGNO_CLIC_R
      pp_P_SON_SIGN_FX_CLIGNO_CLAC_R: unqueued-sender-com-spec{data-element=sri_P_SON_SIGN_FX_CLIGNO_CLAC_R/P_SON_SIGN_FX_CLIGNO_CLAC_R, init-value=cst_Boolean_init/boolean_init}, provided-interface=AR_SIGNALER_SWC/sri_P_SON_SIGN_FX_CLIGNO_CLAC_R
      pp_PILOTAGE_CLIGNO_AVG: unqueued-sender-com-spec{data-element=PILOTAGE_CLIGNO_AVG, init-value=cst_Boolean_init/boolean_init}, provided-interface=sri_PILOTAGE_CLIGNO_AVG
      pp_PILOTAGE_CLIGNO_AVD: unqueued-sender-com-spec{data-element=PILOTAGE_CLIGNO_AVD, init-value=cst_Boolean_init/boolean_init}, provided-interface=sri_PILOTAGE_CLIGNO_AVD
      pp_P_SON_SIGN_FX_CLIGNO_CLIC_REL: unqueued-sender-com-spec{data-element=sri_P_SON_SIGN_FX_CLIGNO_CLIC_REL/P_SON_SIGN_FX_CLIGNO_CLIC_REL, init-value=cst_Boolean_init/boolean_init}, provided-interface=AR_SIGNALER_SWC/sri_P_SON_SIGN_FX_CLIGNO_CLIC_REL
      pp_P_SON_SIGN_FX_CLIGNO_CLAC_REL: unqueued-sender-com-spec{data-element=sri_P_SON_SIGN_FX_CLIGNO_CLAC_REL/P_SON_SIGN_FX_CLIGNO_CLAC_REL, init-value=cst_Boolean_init/boolean_init}, provided-interface=AR_SIGNALER_SWC/sri_P_SON_SIGN_FX_CLIGNO_CLAC_REL
      pp_P_SON_SIGN_FX_CLIGNO_CLIC_R_REL: unqueued-sender-com-spec{data-element=sri_P_SON_SIGN_FX_CLIGNO_CLIC_R_REL/P_SON_SIGN_FX_CLIGNO_CLIC_R_REL, init-value=cst_Boolean_init/boolean_init}, provided-interface=AR_SIGNALER_SWC/sri_P_SON_SIGN_FX_CLIGNO_CLIC_R_REL
      pp_P_SON_SIGN_FX_CLIGNO_CLAC_R_REL: unqueued-sender-com-spec{data-element=sri_P_SON_SIGN_FX_CLIGNO_CLAC_R_REL/P_SON_SIGN_FX_CLIGNO_CLAC_R_REL, init-value=cst_Boolean_init/boolean_init}, provided-interface=AR_SIGNALER_SWC/sri_P_SON_SIGN_FX_CLIGNO_CLAC_R_REL
      pp_CMD_CLIGNO_ARG: unqueued-sender-com-spec{data-element=CMD_CLIGNO_ARG, init-value=cst_Boolean_init/boolean_init}, provided-interface=sri_CMD_CLIGNO_ARG
      pp_CMD_CLIGNO_ARD: unqueued-sender-com-spec{data-element=CMD_CLIGNO_ARD, init-value=cst_Boolean_init/boolean_init}, provided-interface=sri_CMD_CLIGNO_ARD
    5 x require port:
      rp_DIAG_CLIGNO_AVD: unqueued-receiver-com-spec{data-element=DIAG_CLIGNO_AVD, handle-invalid=KEEP, init-value=cst_UInt8_init/uint8_init, resync-time=0.0}, required-interface=sri_DIAG_CLIGNO_AVD
      rp_DIAG_CLIGNO_ARD: unqueued-receiver-com-spec{data-element=DIAG_CLIGNO_ARD, handle-invalid=KEEP, init-value=cst_UInt8_init/uint8_init, resync-time=0.0}, required-interface=sri_DIAG_CLIGNO_ARD
      rp_DIAG_CLIGNO_AVG: unqueued-receiver-com-spec{data-element=DIAG_CLIGNO_AVG, handle-invalid=KEEP, init-value=cst_UInt8_init/uint8_init, resync-time=0.0}, required-interface=sri_DIAG_CLIGNO_AVG
      rp_DIAG_CLIGNO_ARG: unqueued-receiver-com-spec{data-element=DIAG_CLIGNO_ARG, handle-invalid=KEEP, init-value=cst_UInt8_init/uint8_init, resync-time=0.0}, required-interface=sri_DIAG_CLIGNO_ARG
      rp_ETAT_COMMODO_ECLAIRAGE_4POS: unqueued-receiver-com-spec{data-element=ETAT_COMMODO_ECLAIRAGE_4POS, handle-invalid=KEEP, init-value=cst_UInt8_init/uint8_init, resync-time=0.0}, required-interface=sri_ETAT_COMMODO_ECLAIRAGE_4POS
    6 x provide port:
      pp_ETAT_CMD_ECLAIRAGE: unqueued-sender-com-spec{data-element=ETAT_CMD_ECLAIRAGE, init-value=cst_UInt8_init/uint8_init}, provided-interface=sri_ETAT_CMD_ECLAIRAGE
      pp_ETAT_FEUX_DIRECTION: unqueued-sender-com-spec{data-element=ETAT_FEUX_DIRECTION, init-value=cst_UInt8_init/uint8_init}, provided-interface=sri_ETAT_FEUX_DIRECTION
      pp_ETAT_FEUX_DETRESSE: unqueued-sender-com-spec{data-element=sri_ETAT_FEUX_DETRESSE/ETAT_FEUX_DETRESSE, init-value=cst_Boolean_init/boolean_init}, provided-interface=AR_SIGNALER_SWC/sri_ETAT_FEUX_DETRESSE
      pp_ETAT_CLIGNOTANT_G: unqueued-sender-com-spec{data-element=sri_ETAT_CLIGNOTANT_G/ETAT_CLIGNOTANT_G, init-value=cst_Boolean_init/boolean_init}, provided-interface=AR_SIGNALER_SWC/sri_ETAT_CLIGNOTANT_G
      pp_ETAT_CLIGNOTANT_D: unqueued-sender-com-spec{data-element=sri_ETAT_CLIGNOTANT_D/ETAT_CLIGNOTANT_D, init-value=cst_Boolean_init/boolean_init}, provided-interface=AR_SIGNALER_SWC/sri_ETAT_CLIGNOTANT_D
      pp_P_LED_SIGN_PUSH_FEU_DET: unqueued-sender-com-spec{data-element=P_LED_SIGN_PUSH_FEU_DET, init-value=cst_Boolean_init/boolean_init}, provided-interface=sri_P_LED_SIGN_PUSH_FEU_DET
    require port rp_APPUI_PEDALE_FREIN: unqueued-receiver-com-spec{data-element=APPUI_PEDALE_FREIN, handle-invalid=KEEP, init-value=cst_Boolean_init/boolean_init, resync-time=0.0}, required-interface=sri_APPUI_PEDALE_FREIN
    require port rp_CONTACT_FREIN2: unqueued-receiver-com-spec{data-element=CONTACT_FREIN2, handle-invalid=KEEP, init-value=cst_Boolean_init/boolean_init, resync-time=0.0}, required-interface=sri_CONTACT_FREIN2
    require port rp_CDE_APC: unqueued-receiver-com-spec{data-element=sri_CDE_APC/CDE_APC, handle-invalid=KEEP, init-value=cst_Boolean_init/boolean_init, resync-time=0.0}, required-interface=AR_SIGNALER_SWC/sri_CDE_APC
    provide port pp_CMD_FEUX_STOP: unqueued-sender-com-spec{data-element=CMD_FEUX_STOP, init-value=cst_Boolean_init/boolean_init}, provided-interface=sri_CMD_FEUX_STOP
    require port rp_ETAT_DMD_ANTIBROUILLARD: unqueued-receiver-com-spec{data-element=ETAT_DMD_ANTIBROUILLARD, handle-invalid=KEEP, init-value=cst_UInt8_init/uint8_init, resync-time=0.0}, required-interface=sri_ETAT_DMD_ANTIBROUILLARD
    provide port pp_DMD_ANTIBROUILLARD: unqueued-sender-com-spec{data-element=DMD_ANTIBROUILLARD, init-value=cst_UInt8_init/uint8_init}, provided-interface=sri_DMD_ANTIBROUILLARD
    require port rp_ETAT_MA: unqueued-receiver-com-spec{data-element=ETAT_MA, handle-invalid=KEEP, init-value=cst_Boolean_init/boolean_init, resync-time=0.0}, required-interface=sri_ETAT_MA
    provide port pp_CMD_FEUX_MAR: unqueued-sender-com-spec{data-element=CMD_FEUX_MAR, init-value=cst_Boolean_init/boolean_init}, provided-interface=sri_CMD_FEUX_MAR
    provide port pp_ETAT_JOUR_NUIT: unqueued-sender-com-spec{data-element=ETAT_JOUR_NUIT, init-value=cst_Boolean_init/boolean_init}, provided-interface=sri_ETAT_JOUR_NUIT
    13 x require port:
      rp_DMD_FEUX_DETRESSE: unqueued-receiver-com-spec{data-element=DMD_FEUX_DETRESSE, handle-invalid=KEEP, init-value=cst_Boolean_init/boolean_init, resync-time=0.0}, required-interface=sri_DMD_FEUX_DETRESSE
      rp_ETAT_CONDA_OUV_AR: unqueued-receiver-com-spec{data-element=ETAT_CONDA_OUV_AR, handle-invalid=KEEP, init-value=cst_Boolean_init/boolean_init, resync-time=0.0}, required-interface=sri_ETAT_CONDA_OUV_AR
      rp_CHOC_FEUX_DET: unqueued-receiver-com-spec{data-element=CHOC_FEUX_DET, handle-invalid=KEEP, init-value=cst_Boolean_init/boolean_init, resync-time=0.0}, required-interface=sri_CHOC_FEUX_DET
      rp_INFO_CHOC_PIETON: unqueued-receiver-com-spec{data-element=INFO_CHOC_PIETON, handle-invalid=KEEP, init-value=cst_Boolean_init/boolean_init, resync-time=0.0}, required-interface=sri_INFO_CHOC_PIETON
      rp_VOLONTE_CONDUCTEUR: unqueued-receiver-com-spec{data-element=VOLONTE_CONDUCTEUR, handle-invalid=KEEP, init-value=cst_UInt8_init/uint8_init, resync-time=0.0}, required-interface=sri_VOLONTE_CONDUCTEUR
      rp_DMD_WARNING_FORTE_DECEL: unqueued-receiver-com-spec{data-element=DMD_WARNING_FORTE_DECEL, handle-invalid=KEEP, init-value=cst_Boolean_init/boolean_init, resync-time=0.0}, required-interface=sri_DMD_WARNING_FORTE_DECEL
      rp_DMD_LOCAL_TELECMD: unqueued-receiver-com-spec{data-element=sri_DMD_LOCAL_TELECMD/DMD_LOCAL_TELECMD, handle-invalid=KEEP, init-value=cst_Boolean_init/boolean_init, resync-time=0.0}, required-interface=AR_SIGNALER_SWC/sri_DMD_LOCAL_TELECMD
      rp_ETAT_COMMODO_CLIGNO: unqueued-receiver-com-spec{data-element=ETAT_COMMODO_CLIGNO, handle-invalid=KEEP, init-value=cst_UInt8_init/uint8_init, resync-time=0.0}, required-interface=sri_ETAT_COMMODO_CLIGNO
      rp_ETAT_CONDA: unqueued-receiver-com-spec{data-element=sri_ETAT_CONDA/ETAT_CONDA, handle-invalid=KEEP, init-value=cst_UInt8_init/uint8_init, resync-time=0.0}, required-interface=AR_SIGNALER_SWC/sri_ETAT_CONDA
      rp_TYPE_CONDA: unqueued-receiver-com-spec{data-element=sri_TYPE_CONDA/TYPE_CONDA, handle-invalid=KEEP, init-value=cst_UInt8_init/uint8_init, resync-time=0.0}, required-interface=AR_SIGNALER_SWC/sri_TYPE_CONDA
      rp_FNCT_SFU_UC_FREIN: unqueued-receiver-com-spec{data-element=sri_FNCT_SFU_UC_FREIN/FNCT_SFU_UC_FREIN, handle-invalid=KEEP, init-value=cst_Boolean_init/boolean_init, resync-time=0.0}, required-interface=sri_FNCT_SFU_UC_FREIN
      rp_ETAT_FEUX_CROISEMENT: unqueued-receiver-com-spec{data-element=ETAT_FEUX_CROISEMENT, handle-invalid=KEEP, init-value=cst_Boolean_init/boolean_init, resync-time=0.0}, required-interface=sri_ETAT_FEUX_CROISEMENT
      rp_ETAT_FEUX_ROUTE: unqueued-receiver-com-spec{data-element=ETAT_FEUX_ROUTE, handle-invalid=KEEP, init-value=cst_Boolean_init/boolean_init, resync-time=0.0}, required-interface=sri_ETAT_FEUX_ROUTE
    provide port pp_CMD_ANTIBR_AR: unqueued-sender-com-spec{data-element=CMD_ANTIBR_AR, init-value=cst_Boolean_init/boolean_init}, provided-interface=sri_CMD_ANTIBR_AR
    provide port pp_ETAT_ANTIBR_AR: unqueued-sender-com-spec{data-element=ETAT_ANTIBR_AR, init-value=cst_Boolean_init/boolean_init}, provided-interface=sri_ETAT_ANTIBR_AR
    provide port pp_P_TEM_SIGN_FX_ABAR: unqueued-sender-com-spec{data-element=P_TEM_SIGN_FX_ABAR, init-value=cst_Boolean_init/boolean_init}, provided-interface=sri_P_TEM_SIGN_FX_ABAR
    6 x component:
      SIGNALER_S1: type=SIGNALER_S1
      SIGNALER_S0: type=SIGNALER_S0
      SIGNALER_S2: type=SIGNALER_S2
      SIGNALER_PARAM: type=SIGNALER_PARAM
      ECL_EXT_S0: type=ECL_EXT_S0
      ECL_EXT_S1: type=ECL_EXT_S1
    delegate SIGNALER_S1.rp_ETAT_RESEAU_ELECTRIQUE <-> outer port MDL_SIGNALER/rp_ETAT_RESEAU_ELECTRIQUE
    delegate SIGNALER_S1.rp_AVER_SONORE <-> outer port MDL_SIGNALER/rp_AVER_SONORE
    delegate SIGNALER_S1.pp_CMD_AVER_SONORE <-> outer port MDL_SIGNALER/pp_CMD_AVER_SONORE
    connect SIGNALER_PARAM.pp_TYPE_DE_BOITE -> SIGNALER_S1.rp_TYPE_DE_BOITE
    connect SIGNALER_PARAM.pp_SECU_FEUX_STOP_PAR_CTC_FREIN2 -> SIGNALER_S1.rp_SECU_FEUX_STOP_PAR_CTC_FREIN2
    delegate SIGNALER_S0.rp_ETAT_PRINCIP_SEV <-> outer port MDL_SIGNALER/rp_ETAT_PRINCIP_SEV
    delegate SIGNALER_S0.rp_ETAT_RESEAU_ELECTRIQUE <-> outer port MDL_SIGNALER/rp_ETAT_RESEAU_ELECTRIQUE
    delegate SIGNALER_S0.rp_DMD_ALLUMAGE_FEUX_POSITION <-> outer port MDL_SIGNALER/rp_DMD_ALLUMAGE_FEUX_POSITION
    delegate SIGNALER_S0.pp_PILOTAGE_FEU_DIURNE_DEDIE_D <-> outer port MDL_SIGNALER/pp_PILOTAGE_FEU_DIURNE_DEDIE_D
    delegate SIGNALER_S0.pp_PILOTAGE_FEU_DIURNE_DEDIE_G <-> outer port MDL_SIGNALER/pp_PILOTAGE_FEU_DIURNE_DEDIE_G
    delegate SIGNALER_S0.pp_ETAT_FEUX_DIURNES <-> outer port MDL_SIGNALER/pp_ETAT_FEUX_DIURNES
    delegate SIGNALER_S0.pp_P_TEM_SIGN_FX_DIURNES <-> outer port MDL_SIGNALER/pp_P_TEM_SIGN_FX_DIURNES
    delegate SIGNALER_S0.rp_VITESSE_LONGITUDINALE <-> outer port MDL_SIGNALER/rp_VITESSE_LONGITUDINALE
    delegate SIGNALER_S0.rp_ETAT_ANTIBR_AV <-> outer port MDL_SIGNALER/rp_ETAT_ANTIBR_AV
    delegate SIGNALER_S0.rp_DMD_FEUX_CROISEMENT_AAF <-> outer port MDL_SIGNALER/rp_DMD_FEUX_CROISEMENT_AAF
    delegate SIGNALER_S0.rp_ETAT_CPO_COND <-> outer port MDL_SIGNALER/rp_ETAT_CPO_COND
    delegate SIGNALER_S0.rp_TYPE_REVEIL_BAGUE_ECLAIRAGE <-> outer port MDL_SIGNALER/rp_TYPE_REVEIL_BAGUE_ECLAIRAGE
    delegate SIGNALER_S0.pp_PILOTAGE_FEUX_POSITION_AVD <-> outer port MDL_SIGNALER/pp_PILOTAGE_FEUX_POSITION_AVD
    delegate SIGNALER_S0.pp_PILOTAGE_FEUX_POSITION_AVG <-> outer port MDL_SIGNALER/pp_PILOTAGE_FEUX_POSITION_AVG
    delegate SIGNALER_S0.pp_CMD_FEUX_POSITION_AR <-> outer port MDL_SIGNALER/pp_CMD_FEUX_POSITION_AR
    delegate SIGNALER_S0.pp_ETAT_FEUX_POSITION <-> outer port MDL_SIGNALER/pp_ETAT_FEUX_POSITION
    delegate SIGNALER_S0.pp_P_TEM_SIGN_FX_POS <-> outer port MDL_SIGNALER/pp_P_TEM_SIGN_FX_POS
    delegate SIGNALER_S0.pp_DMD_ALLUMAGE_FEUX_CROISEMENT <-> outer port MDL_SIGNALER/pp_DMD_ALLUMAGE_FEUX_CROISEMENT
    delegate SIGNALER_S0.pp_P_SON_SIGN_OUBLI_FEUX <-> outer port MDL_SIGNALER/pp_P_SON_SIGN_OUBLI_FEUX
    delegate SIGNALER_S2.pp_P_TEM_SIGN_FX_CLIGNO_G <-> outer port MDL_SIGNALER/pp_P_TEM_SIGN_FX_CLIGNO_G
    delegate SIGNALER_S2.pp_P_TEM_SIGN_FX_CLIGNO_D <-> outer port MDL_SIGNALER/pp_P_TEM_SIGN_FX_CLIGNO_D
    delegate SIGNALER_S2.pp_P_SON_SIGN_FX_CLIGNO_CLIC <-> outer port MDL_SIGNALER/pp_P_SON_SIGN_FX_CLIGNO_CLIC
    delegate SIGNALER_S2.pp_P_SON_SIGN_FX_CLIGNO_CLAC <-> outer port MDL_SIGNALER/pp_P_SON_SIGN_FX_CLIGNO_CLAC
    delegate SIGNALER_S2.pp_P_SON_SIGN_FX_CLIGNO_CLIC_R <-> outer port MDL_SIGNALER/pp_P_SON_SIGN_FX_CLIGNO_CLIC_R
    delegate SIGNALER_S2.pp_P_SON_SIGN_FX_CLIGNO_CLAC_R <-> outer port MDL_SIGNALER/pp_P_SON_SIGN_FX_CLIGNO_CLAC_R
    delegate SIGNALER_S2.pp_PILOTAGE_CLIGNO_AVG <-> outer port MDL_SIGNALER/pp_PILOTAGE_CLIGNO_AVG
    delegate SIGNALER_S2.pp_PILOTAGE_CLIGNO_AVD <-> outer port MDL_SIGNALER/pp_PILOTAGE_CLIGNO_AVD
    delegate SIGNALER_S2.pp_P_SON_SIGN_FX_CLIGNO_CLIC_REL <-> outer port MDL_SIGNALER/pp_P_SON_SIGN_FX_CLIGNO_CLIC_REL
    delegate SIGNALER_S2.pp_P_SON_SIGN_FX_CLIGNO_CLAC_REL <-> outer port MDL_SIGNALER/pp_P_SON_SIGN_FX_CLIGNO_CLAC_REL
    delegate SIGNALER_S2.pp_P_SON_SIGN_FX_CLIGNO_CLIC_R_REL <-> outer port MDL_SIGNALER/pp_P_SON_SIGN_FX_CLIGNO_CLIC_R_REL
    delegate SIGNALER_S2.pp_P_SON_SIGN_FX_CLIGNO_CLAC_R_REL <-> outer port MDL_SIGNALER/pp_P_SON_SIGN_FX_CLIGNO_CLAC_R_REL
    delegate SIGNALER_S2.pp_CMD_CLIGNO_ARG <-> outer port MDL_SIGNALER/pp_CMD_CLIGNO_ARG
    delegate SIGNALER_S2.pp_CMD_CLIGNO_ARD <-> outer port MDL_SIGNALER/pp_CMD_CLIGNO_ARD
    delegate SIGNALER_S2.rp_DIAG_CLIGNO_AVD <-> outer port MDL_SIGNALER/rp_DIAG_CLIGNO_AVD
    delegate SIGNALER_S2.rp_DIAG_CLIGNO_ARD <-> outer port MDL_SIGNALER/rp_DIAG_CLIGNO_ARD
    delegate SIGNALER_S2.rp_DIAG_CLIGNO_AVG <-> outer port MDL_SIGNALER/rp_DIAG_CLIGNO_AVG
    delegate SIGNALER_S2.rp_DIAG_CLIGNO_ARG <-> outer port MDL_SIGNALER/rp_DIAG_CLIGNO_ARG
    delegate ECL_EXT_S0.rp_ETAT_PRINCIP_SEV <-> outer port MDL_SIGNALER/rp_ETAT_PRINCIP_SEV
    delegate ECL_EXT_S0.rp_ETAT_RESEAU_ELECTRIQUE <-> outer port MDL_SIGNALER/rp_ETAT_RESEAU_ELECTRIQUE
    delegate ECL_EXT_S0.rp_ETAT_COMMODO_ECLAIRAGE_4POS <-> outer port MDL_SIGNALER/rp_ETAT_COMMODO_ECLAIRAGE_4POS
    delegate ECL_EXT_S0.pp_ETAT_CMD_ECLAIRAGE <-> outer port MDL_SIGNALER/pp_ETAT_CMD_ECLAIRAGE
    delegate SIGNALER_S2.rp_ETAT_PRINCIP_SEV <-> outer port MDL_SIGNALER/rp_ETAT_PRINCIP_SEV
    delegate SIGNALER_S2.rp_ETAT_RESEAU_ELECTRIQUE <-> outer port MDL_SIGNALER/rp_ETAT_RESEAU_ELECTRIQUE
    delegate SIGNALER_S2.pp_ETAT_FEUX_DIRECTION <-> outer port MDL_SIGNALER/pp_ETAT_FEUX_DIRECTION
    delegate SIGNALER_S2.pp_ETAT_FEUX_DETRESSE <-> outer port MDL_SIGNALER/pp_ETAT_FEUX_DETRESSE
    delegate SIGNALER_S2.pp_ETAT_CLIGNOTANT_G <-> outer port MDL_SIGNALER/pp_ETAT_CLIGNOTANT_G
    delegate SIGNALER_S2.pp_ETAT_CLIGNOTANT_D <-> outer port MDL_SIGNALER/pp_ETAT_CLIGNOTANT_D
    delegate SIGNALER_S2.pp_P_LED_SIGN_PUSH_FEU_DET <-> outer port MDL_SIGNALER/pp_P_LED_SIGN_PUSH_FEU_DET
    delegate SIGNALER_S1.rp_ETAT_PRINCIP_SEV <-> outer port MDL_SIGNALER/rp_ETAT_PRINCIP_SEV
    delegate SIGNALER_S1.rp_APPUI_PEDALE_FREIN <-> outer port MDL_SIGNALER/rp_APPUI_PEDALE_FREIN
    delegate SIGNALER_S1.rp_CONTACT_FREIN2 <-> outer port MDL_SIGNALER/rp_CONTACT_FREIN2
    delegate SIGNALER_S1.rp_CDE_APC <-> outer port MDL_SIGNALER/rp_CDE_APC
    delegate SIGNALER_S1.pp_CMD_FEUX_STOP <-> outer port MDL_SIGNALER/pp_CMD_FEUX_STOP
    delegate ECL_EXT_S1.rp_ETAT_DMD_ANTIBROUILLARD <-> outer port MDL_SIGNALER/rp_ETAT_DMD_ANTIBROUILLARD
    delegate ECL_EXT_S1.pp_DMD_ANTIBROUILLARD <-> outer port MDL_SIGNALER/pp_DMD_ANTIBROUILLARD
    delegate SIGNALER_S1.rp_ETAT_MA <-> outer port MDL_SIGNALER/rp_ETAT_MA
    delegate SIGNALER_S1.pp_CMD_FEUX_MAR <-> outer port MDL_SIGNALER/pp_CMD_FEUX_MAR
    delegate SIGNALER_S0.pp_ETAT_JOUR_NUIT <-> outer port MDL_SIGNALER/pp_ETAT_JOUR_NUIT
    delegate SIGNALER_S2.rp_DMD_FEUX_DETRESSE <-> outer port MDL_SIGNALER/rp_DMD_FEUX_DETRESSE
    delegate SIGNALER_S2.rp_ETAT_CONDA_OUV_AR <-> outer port MDL_SIGNALER/rp_ETAT_CONDA_OUV_AR
    delegate SIGNALER_S2.rp_CHOC_FEUX_DET <-> outer port MDL_SIGNALER/rp_CHOC_FEUX_DET
    delegate SIGNALER_S2.rp_INFO_CHOC_PIETON <-> outer port MDL_SIGNALER/rp_INFO_CHOC_PIETON
    delegate SIGNALER_S2.rp_VOLONTE_CONDUCTEUR <-> outer port MDL_SIGNALER/rp_VOLONTE_CONDUCTEUR
    delegate SIGNALER_S2.rp_DMD_WARNING_FORTE_DECEL <-> outer port MDL_SIGNALER/rp_DMD_WARNING_FORTE_DECEL
    delegate SIGNALER_S2.rp_VITESSE_LONGITUDINALE <-> outer port MDL_SIGNALER/rp_VITESSE_LONGITUDINALE
    delegate SIGNALER_S2.rp_DMD_LOCAL_TELECMD <-> outer port MDL_SIGNALER/rp_DMD_LOCAL_TELECMD
    delegate SIGNALER_S2.rp_ETAT_COMMODO_CLIGNO <-> outer port MDL_SIGNALER/rp_ETAT_COMMODO_CLIGNO
    delegate SIGNALER_S2.rp_ETAT_CONDA <-> outer port MDL_SIGNALER/rp_ETAT_CONDA
    delegate SIGNALER_S2.rp_TYPE_CONDA <-> outer port MDL_SIGNALER/rp_TYPE_CONDA
    delegate SIGNALER_S2.rp_FONCTION_SFU_DANS_UCFREIN <-> outer port MDL_SIGNALER/rp_FNCT_SFU_UC_FREIN
    delegate SIGNALER_S0.rp_ETAT_FEUX_CROISEMENT <-> outer port MDL_SIGNALER/rp_ETAT_FEUX_CROISEMENT
    delegate SIGNALER_S0.rp_ETAT_FEUX_ROUTE <-> outer port MDL_SIGNALER/rp_ETAT_FEUX_ROUTE
    delegate SIGNALER_S0.pp_CMD_ANTIBR_AR <-> outer port MDL_SIGNALER/pp_CMD_ANTIBR_AR
    delegate SIGNALER_S0.pp_ETAT_ANTIBR_AR <-> outer port MDL_SIGNALER/pp_ETAT_ANTIBR_AR
    delegate SIGNALER_S0.pp_P_TEM_SIGN_FX_ABAR <-> outer port MDL_SIGNALER/pp_P_TEM_SIGN_FX_ABAR
    connect SIGNALER_PARAM.pp_DMDM_SIGN_ECL_FEUX_DIURNES -> SIGNALER_S0.rp_DMDM_SIGN_ECL_FEUX_DIURNES
    connect SIGNALER_PARAM.pp_DMD_ACT_FX_POS -> SIGNALER_S0.rp_DMD_ACT_FX_POS
    connect SIGNALER_PARAM.pp_OPTION_ALL_FEUX_POS_AVEC_DIURNE -> SIGNALER_S0.rp_OPTION_ALL_FEUX_POS_AVEC_DIURNE
    connect SIGNALER_PARAM.pp_ETAT_ACTIVATION_FMH -> SIGNALER_S0.rp_ETAT_ACTIVATION_FMH
    connect SIGNALER_PARAM.pp_ETAT_ACTIVATION_PLUIE -> SIGNALER_S0.rp_ETAT_ACTIVATION_PLUIE
    connect SIGNALER_PARAM.pp_ETAT_ACTIVATION_ALL_LOCAL -> SIGNALER_S0.rp_ETAT_ACTIVATION_ALL_LOCAL
    connect SIGNALER_PARAM.pp_ETAT_ACTIVATION_ALL_DECONDA -> SIGNALER_S0.rp_ETAT_ACTIVATION_ALL_DECONDA
    connect SIGNALER_PARAM.pp_PRESENCE_ANTIBR_AR -> SIGNALER_S0.rp_PRESENCE_ANTIBR_AR
    connect ECL_EXT_S0.pp_ETAT_CMD_ECLAIRAGE -> SIGNALER_S0.rp_ETAT_CMD_ECLAIRAGE
    connect ECL_EXT_S1.pp_DMD_ANTIBROUILLARD -> SIGNALER_S0.rp_DMD_ANTIBROUILLARD
    connect SIGNALER_PARAM.pp_OPTION_CLIGNO_IMPULS -> SIGNALER_S2.rp_OPTION_CLIGNO_IMPULS
    connect SIGNALER_PARAM.pp_OPTION_POLICE -> SIGNALER_S2.rp_OPTION_POLICE
    connect SIGNALER_PARAM.pp_OPTION_ALL_WARNING_CHOC -> SIGNALER_S2.rp_OPTION_ALL_WARNING_CHOC
    connect SIGNALER_PARAM.pp_OPTION_ALL_WARNING_FORTE_DECEL -> SIGNALER_S2.rp_OPTION_ALL_WARNING_FORTE_DECEL
    connect SIGNALER_PARAM.pp_MODE_CONFIG_VHL -> SIGNALER_S2.rp_MODE_CONFIG_VHL
  internal behavior ib_GERER_AVER_SONORE: component=GERER_AVER_SONORE
    timing event evt_GERER_AVER_SONORE: start-on-event=GERER_AVER_SONORE, period=0.1
    runnable GERER_AVER_SONORE
      data read access dra_ETAT_RESEAU_ELECTRIQUE: data-element=rp_ETAT_RESEAU_ELECTRIQUE.ETAT_RESEAU_ELECTRIQUE
      data read access dra_AVER_SONORE: data-element=rp_AVER_SONORE.AVER_SONORE
      data write access dwa_CMD_AVER_SONORE: data-element=pp_CMD_AVER_SONORE.CMD_AVER_SONORE
  sender receiver interface sri_ETAT_RESEAU_ELECTRIQUE
    data ETAT_RESEAU_ELECTRIQUE: type=AR_SIGNALER_SWC/UInt8
  constant specification cst_UInt8_init
    value:
      integer literal uint8_init: type=AR_SIGNALER_SWC/UInt8, value=0
  sender receiver interface sri_AVER_SONORE
    data AVER_SONORE: type=AR_SIGNALER_SWC/Boolean
  constant specification cst_Boolean_init
    value:
      boolean literal boolean_init: type=AR_SIGNALER_SWC/Boolean, value=false
  sender receiver interface sri_CMD_AVER_SONORE
    data CMD_AVER_SONORE: type=AR_SIGNALER_SWC/Boolean
  swc implementation implem_GERER_AVER_SONORE: programming-language=C, behavior=ib_GERER_AVER_SONORE
    code-descriptors:
      code implem_GERER_AVER_SONORE: type=SRC
        xfile GERER_AVER_SONORE.c: url=Src_C/GERER_AVER_SONORE.c
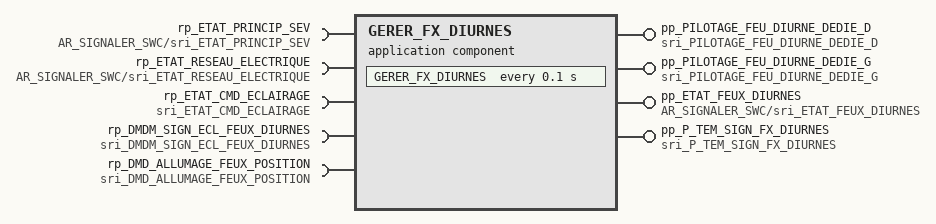
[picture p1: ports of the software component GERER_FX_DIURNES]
  application software component type GERER_FX_DIURNES
    5 x require port:
      rp_ETAT_PRINCIP_SEV: unqueued-receiver-com-spec{data-element=sri_ETAT_PRINCIP_SEV/ETAT_PRINCIP_SEV, handle-invalid=KEEP, init-value=cst_UInt8_init/uint8_init, resync-time=0.0}, required-interface=AR_SIGNALER_SWC/sri_ETAT_PRINCIP_SEV
      rp_ETAT_RESEAU_ELECTRIQUE: unqueued-receiver-com-spec{data-element=sri_ETAT_RESEAU_ELECTRIQUE/ETAT_RESEAU_ELECTRIQUE, handle-invalid=KEEP, init-value=cst_UInt8_init/uint8_init, resync-time=0.0}, required-interface=AR_SIGNALER_SWC/sri_ETAT_RESEAU_ELECTRIQUE
      rp_ETAT_CMD_ECLAIRAGE: unqueued-receiver-com-spec{data-element=ETAT_CMD_ECLAIRAGE, handle-invalid=KEEP, init-value=cst_UInt8_init/uint8_init, resync-time=0.0}, required-interface=sri_ETAT_CMD_ECLAIRAGE
      rp_DMDM_SIGN_ECL_FEUX_DIURNES: unqueued-receiver-com-spec{data-element=DMDM_SIGN_ECL_FEUX_DIURNES, handle-invalid=KEEP, init-value=cst_Boolean_init/boolean_init, resync-time=0.0}, required-interface=sri_DMDM_SIGN_ECL_FEUX_DIURNES
      rp_DMD_ALLUMAGE_FEUX_POSITION: unqueued-receiver-com-spec{data-element=DMD_ALLUMAGE_FEUX_POSITION, handle-invalid=KEEP, init-value=cst_Boolean_init/boolean_init, resync-time=0.0}, required-interface=sri_DMD_ALLUMAGE_FEUX_POSITION
    4 x provide port:
      pp_PILOTAGE_FEU_DIURNE_DEDIE_D: unqueued-sender-com-spec{data-element=PILOTAGE_FEU_DIURNE_DEDIE_D, init-value=cst_Boolean_init/boolean_init}, provided-interface=sri_PILOTAGE_FEU_DIURNE_DEDIE_D
      pp_PILOTAGE_FEU_DIURNE_DEDIE_G: unqueued-sender-com-spec{data-element=PILOTAGE_FEU_DIURNE_DEDIE_G, init-value=cst_Boolean_init/boolean_init}, provided-interface=sri_PILOTAGE_FEU_DIURNE_DEDIE_G
      pp_ETAT_FEUX_DIURNES: unqueued-sender-com-spec{data-element=sri_ETAT_FEUX_DIURNES/ETAT_FEUX_DIURNES, init-value=cst_Boolean_init/boolean_init}, provided-interface=AR_SIGNALER_SWC/sri_ETAT_FEUX_DIURNES
      pp_P_TEM_SIGN_FX_DIURNES: unqueued-sender-com-spec{data-element=P_TEM_SIGN_FX_DIURNES, init-value=cst_Boolean_init/boolean_init}, provided-interface=sri_P_TEM_SIGN_FX_DIURNES
  composition type SIGNALER_S0
    5 x require port:
      rp_ETAT_PRINCIP_SEV: unqueued-receiver-com-spec{data-element=sri_ETAT_PRINCIP_SEV/ETAT_PRINCIP_SEV, handle-invalid=KEEP, init-value=cst_UInt8_init/uint8_init, resync-time=0.0}, required-interface=AR_SIGNALER_SWC/sri_ETAT_PRINCIP_SEV
      rp_ETAT_RESEAU_ELECTRIQUE: unqueued-receiver-com-spec{data-element=sri_ETAT_RESEAU_ELECTRIQUE/ETAT_RESEAU_ELECTRIQUE, handle-invalid=KEEP, init-value=cst_UInt8_init/uint8_init, resync-time=0.0}, required-interface=AR_SIGNALER_SWC/sri_ETAT_RESEAU_ELECTRIQUE
      rp_ETAT_CMD_ECLAIRAGE: unqueued-receiver-com-spec{data-element=ETAT_CMD_ECLAIRAGE, handle-invalid=KEEP, init-value=cst_UInt8_init/uint8_init, resync-time=0.0}, required-interface=sri_ETAT_CMD_ECLAIRAGE
      rp_DMDM_SIGN_ECL_FEUX_DIURNES: unqueued-receiver-com-spec{data-element=DMDM_SIGN_ECL_FEUX_DIURNES, handle-invalid=KEEP, init-value=cst_Boolean_init/boolean_init, resync-time=0.0}, required-interface=sri_DMDM_SIGN_ECL_FEUX_DIURNES
      rp_DMD_ALLUMAGE_FEUX_POSITION: unqueued-receiver-com-spec{data-element=DMD_ALLUMAGE_FEUX_POSITION, handle-invalid=KEEP, init-value=cst_Boolean_init/boolean_init, resync-time=0.0}, required-interface=sri_DMD_ALLUMAGE_FEUX_POSITION
    4 x provide port:
      pp_PILOTAGE_FEU_DIURNE_DEDIE_D: unqueued-sender-com-spec{data-element=PILOTAGE_FEU_DIURNE_DEDIE_D, init-value=cst_Boolean_init/boolean_init}, provided-interface=sri_PILOTAGE_FEU_DIURNE_DEDIE_D
      pp_PILOTAGE_FEU_DIURNE_DEDIE_G: unqueued-sender-com-spec{data-element=PILOTAGE_FEU_DIURNE_DEDIE_G, init-value=cst_Boolean_init/boolean_init}, provided-interface=sri_PILOTAGE_FEU_DIURNE_DEDIE_G
      pp_ETAT_FEUX_DIURNES: unqueued-sender-com-spec{data-element=sri_ETAT_FEUX_DIURNES/ETAT_FEUX_DIURNES, init-value=cst_Boolean_init/boolean_init}, provided-interface=AR_SIGNALER_SWC/sri_ETAT_FEUX_DIURNES
      pp_P_TEM_SIGN_FX_DIURNES: unqueued-sender-com-spec{data-element=P_TEM_SIGN_FX_DIURNES, init-value=cst_Boolean_init/boolean_init}, provided-interface=sri_P_TEM_SIGN_FX_DIURNES
    7 x require port:
      rp_ETAT_ANTIBR_AV: unqueued-receiver-com-spec{data-element=ETAT_ANTIBR_AV, handle-invalid=KEEP, init-value=cst_Boolean_init/boolean_init, resync-time=0.0}, required-interface=sri_ETAT_ANTIBR_AV
      rp_DMD_FEUX_CROISEMENT_AAF: unqueued-receiver-com-spec{data-element=DMD_FEUX_CROISEMENT_AAF, handle-invalid=KEEP, init-value=cst_Boolean_init/boolean_init, resync-time=0.0}, required-interface=sri_DMD_FEUX_CROISEMENT_AAF
      rp_DMD_ACT_FX_POS: unqueued-receiver-com-spec{data-element=DMD_ACT_FX_POS, handle-invalid=KEEP, init-value=cst_Boolean_init/boolean_init, resync-time=0.0}, required-interface=sri_DMD_ACT_FX_POS
      rp_OPTION_ALL_FEUX_POS_AVEC_DIURNE: unqueued-receiver-com-spec{data-element=OPTION_ALL_FEUX_POS_AVEC_DIURNE, handle-invalid=KEEP, init-value=cst_Boolean_init/boolean_init, resync-time=0.0}, required-interface=sri_OPTION_ALL_FEUX_POS_AVEC_DIURNE
      rp_VITESSE_LONGITUDINALE: unqueued-receiver-com-spec{data-element=sri_VITESSE_LONGITUDINALE/VITESSE_LONGITUDINALE, handle-invalid=KEEP, init-value=cst_UInt16_init/uint16_init, resync-time=0.0}, required-interface=AR_SIGNALER_SWC/sri_VITESSE_LONGITUDINALE
      rp_TYPE_REVEIL_BAGUE_ECLAIRAGE: unqueued-receiver-com-spec{data-element=TYPE_REVEIL_BAGUE_ECLAIRAGE, handle-invalid=KEEP, init-value=cst_Boolean_init/boolean_init, resync-time=0.0}, required-interface=sri_TYPE_REVEIL_BAGUE_ECLAIRAGE
      rp_ETAT_CPO_COND: unqueued-receiver-com-spec{data-element=sri_ETAT_CPO_COND/ETAT_CPO_COND, handle-invalid=KEEP, init-value=cst_Boolean_init/boolean_init, resync-time=0.0}, required-interface=AR_SIGNALER_SWC/sri_ETAT_CPO_COND
    7 x provide port:
      pp_PILOTAGE_FEUX_POSITION_AVD: unqueued-sender-com-spec{data-element=PILOTAGE_FEUX_POSITION_AVD, init-value=cst_Boolean_init/boolean_init}, provided-interface=sri_PILOTAGE_FEUX_POSITION_AVD
      pp_PILOTAGE_FEUX_POSITION_AVG: unqueued-sender-com-spec{data-element=PILOTAGE_FEUX_POSITION_AVG, init-value=cst_Boolean_init/boolean_init}, provided-interface=sri_PILOTAGE_FEUX_POSITION_AVG
      pp_CMD_FEUX_POSITION_AR: unqueued-sender-com-spec{data-element=CMD_FEUX_POSITION_AR, init-value=cst_UInt8_init/uint8_init}, provided-interface=sri_CMD_FEUX_POSITION_AR
      pp_ETAT_FEUX_POSITION: unqueued-sender-com-spec{data-element=sri_ETAT_FEUX_POSITION/ETAT_FEUX_POSITION, init-value=cst_Boolean_init/boolean_init}, provided-interface=AR_SIGNALER_SWC/sri_ETAT_FEUX_POSITION
      pp_P_TEM_SIGN_FX_POS: unqueued-sender-com-spec{data-element=P_TEM_SIGN_FX_POS, init-value=cst_Boolean_init/boolean_init}, provided-interface=sri_P_TEM_SIGN_FX_POS
      pp_DMD_ALLUMAGE_FEUX_CROISEMENT: unqueued-sender-com-spec{data-element=DMD_ALLUMAGE_FEUX_CROISEMENT, init-value=cst_Boolean_init/boolean_init}, provided-interface=sri_DMD_ALLUMAGE_FEUX_CROISEMENT
      pp_P_SON_SIGN_OUBLI_FEUX: unqueued-sender-com-spec{data-element=sri_P_SON_SIGN_OUBLI_FEUX/P_SON_SIGN_OUBLI_FEUX, init-value=cst_Boolean_init/boolean_init}, provided-interface=AR_SIGNALER_SWC/sri_P_SON_SIGN_OUBLI_FEUX
    4 x require port:
      rp_ETAT_ACTIVATION_FMH: unqueued-receiver-com-spec{data-element=ETAT_ACTIVATION_FMH, handle-invalid=KEEP, init-value=cst_Boolean_init/boolean_init, resync-time=0.0}, required-interface=sri_ETAT_ACTIVATION_FMH
      rp_ETAT_ACTIVATION_PLUIE: unqueued-receiver-com-spec{data-element=ETAT_ACTIVATION_PLUIE, handle-invalid=KEEP, init-value=cst_Boolean_init/boolean_init, resync-time=0.0}, required-interface=sri_ETAT_ACTIVATION_PLUIE
      rp_ETAT_ACTIVATION_ALL_LOCAL: unqueued-receiver-com-spec{data-element=ETAT_ACTIVATION_ALL_LOCAL, handle-invalid=KEEP, init-value=cst_Boolean_init/boolean_init, resync-time=0.0}, required-interface=sri_ETAT_ACTIVATION_ALL_LOCAL
      rp_ETAT_ACTIVATION_ALL_DECONDA: unqueued-receiver-com-spec{data-element=ETAT_ACTIVATION_ALL_DECONDA, handle-invalid=KEEP, init-value=cst_Boolean_init/boolean_init, resync-time=0.0}, required-interface=sri_ETAT_ACTIVATION_ALL_DECONDA
    provide port pp_ETAT_JOUR_NUIT: unqueued-sender-com-spec{data-element=ETAT_JOUR_NUIT, init-value=cst_Boolean_init/boolean_init}, provided-interface=sri_ETAT_JOUR_NUIT
    4 x require port:
      rp_DMD_ANTIBROUILLARD: unqueued-receiver-com-spec{data-element=DMD_ANTIBROUILLARD, handle-invalid=KEEP, init-value=cst_UInt8_init/uint8_init, resync-time=0.0}, required-interface=sri_DMD_ANTIBROUILLARD
      rp_ETAT_FEUX_CROISEMENT: unqueued-receiver-com-spec{data-element=ETAT_FEUX_CROISEMENT, handle-invalid=KEEP, init-value=cst_Boolean_init/boolean_init, resync-time=0.0}, required-interface=sri_ETAT_FEUX_CROISEMENT
      rp_ETAT_FEUX_ROUTE: unqueued-receiver-com-spec{data-element=ETAT_FEUX_ROUTE, handle-invalid=KEEP, init-value=cst_Boolean_init/boolean_init, resync-time=0.0}, required-interface=sri_ETAT_FEUX_ROUTE
      rp_PRESENCE_ANTIBR_AR: unqueued-receiver-com-spec{data-element=PRESENCE_ANTIBR_AR, handle-invalid=KEEP, init-value=cst_Boolean_init/boolean_init, resync-time=0.0}, required-interface=sri_PRESENCE_ANTIBR_AR
    provide port pp_CMD_ANTIBR_AR: unqueued-sender-com-spec{data-element=CMD_ANTIBR_AR, init-value=cst_Boolean_init/boolean_init}, provided-interface=sri_CMD_ANTIBR_AR
    provide port pp_ETAT_ANTIBR_AR: unqueued-sender-com-spec{data-element=ETAT_ANTIBR_AR, init-value=cst_Boolean_init/boolean_init}, provided-interface=sri_ETAT_ANTIBR_AR
    provide port pp_P_TEM_SIGN_FX_ABAR: unqueued-sender-com-spec{data-element=P_TEM_SIGN_FX_ABAR, init-value=cst_Boolean_init/boolean_init}, provided-interface=sri_P_TEM_SIGN_FX_ABAR
    4 x component:
      GERER_FX_DIURNES: type=GERER_FX_DIURNES
      GERER_FX_POS: type=GERER_FX_POS
      GERER_ETAT_JOUR_NUIT: type=GERER_ETAT_JOUR_NUIT
      GERER_FX_ABAR: type=GERER_FX_ABAR
    connect GERER_FX_DIURNES.pp_ETAT_FEUX_DIURNES -> GERER_FX_POS.rp_ETAT_FEUX_DIURNES
    connect GERER_FX_DIURNES.pp_ETAT_FEUX_DIURNES -> GERER_ETAT_JOUR_NUIT.rp_ETAT_FEUX_DIURNES
    connect GERER_FX_DIURNES.pp_ETAT_FEUX_DIURNES -> GERER_FX_ABAR.rp_ETAT_FEUX_DIURNES
    connect GERER_FX_POS.pp_ETAT_FEUX_POSITION -> GERER_ETAT_JOUR_NUIT.rp_ETAT_FEUX_POSITION
    connect GERER_FX_POS.pp_ETAT_FEUX_POSITION -> GERER_FX_ABAR.rp_ETAT_FEUX_POSITION
    connect GERER_FX_ABAR.pp_ETAT_ANTIBR_AR -> GERER_FX_POS.rp_ETAT_ANTIBR_AR_PREC
    delegate GERER_FX_DIURNES.rp_ETAT_PRINCIP_SEV <-> outer port SIGNALER_S0/rp_ETAT_PRINCIP_SEV
    delegate GERER_FX_DIURNES.rp_ETAT_RESEAU_ELECTRIQUE <-> outer port SIGNALER_S0/rp_ETAT_RESEAU_ELECTRIQUE
    delegate GERER_FX_DIURNES.rp_ETAT_CMD_ECLAIRAGE <-> outer port SIGNALER_S0/rp_ETAT_CMD_ECLAIRAGE
    delegate GERER_FX_DIURNES.rp_DMDM_SIGN_ECL_FEUX_DIURNES <-> outer port SIGNALER_S0/rp_DMDM_SIGN_ECL_FEUX_DIURNES
    delegate GERER_FX_DIURNES.rp_DMD_ALLUMAGE_FEUX_POSITION <-> outer port SIGNALER_S0/rp_DMD_ALLUMAGE_FEUX_POSITION
    delegate GERER_FX_DIURNES.pp_PILOTAGE_FEU_DIURNE_DEDIE_D <-> outer port SIGNALER_S0/pp_PILOTAGE_FEU_DIURNE_DEDIE_D
    delegate GERER_FX_DIURNES.pp_PILOTAGE_FEU_DIURNE_DEDIE_G <-> outer port SIGNALER_S0/pp_PILOTAGE_FEU_DIURNE_DEDIE_G
    delegate GERER_FX_DIURNES.pp_ETAT_FEUX_DIURNES <-> outer port SIGNALER_S0/pp_ETAT_FEUX_DIURNES
    delegate GERER_FX_DIURNES.pp_P_TEM_SIGN_FX_DIURNES <-> outer port SIGNALER_S0/pp_P_TEM_SIGN_FX_DIURNES
    delegate GERER_FX_POS.rp_ETAT_PRINCIP_SEV <-> outer port SIGNALER_S0/rp_ETAT_PRINCIP_SEV
    delegate GERER_FX_POS.rp_ETAT_RESEAU_ELECTRIQUE <-> outer port SIGNALER_S0/rp_ETAT_RESEAU_ELECTRIQUE
    delegate GERER_FX_POS.rp_ETAT_CMD_ECLAIRAGE <-> outer port SIGNALER_S0/rp_ETAT_CMD_ECLAIRAGE
    delegate GERER_FX_POS.rp_DMD_ALLUMAGE_FEUX_POSITION <-> outer port SIGNALER_S0/rp_DMD_ALLUMAGE_FEUX_POSITION
    delegate GERER_FX_POS.rp_ETAT_ANTIBR_AV <-> outer port SIGNALER_S0/rp_ETAT_ANTIBR_AV
    delegate GERER_FX_POS.rp_DMD_FEUX_CROISEMENT_AAF <-> outer port SIGNALER_S0/rp_DMD_FEUX_CROISEMENT_AAF
    delegate GERER_FX_POS.rp_DMD_ACT_FX_POS <-> outer port SIGNALER_S0/rp_DMD_ACT_FX_POS
    delegate GERER_FX_POS.rp_OPTION_ALL_FEUX_POS_AVEC_DIURNE <-> outer port SIGNALER_S0/rp_OPTION_ALL_FEUX_POS_AVEC_DIURNE
    delegate GERER_FX_POS.rp_VITESSE_LONGITUDINALE <-> outer port SIGNALER_S0/rp_VITESSE_LONGITUDINALE
    delegate GERER_FX_POS.rp_TYPE_REVEIL_BAGUE_ECLAIRAGE <-> outer port SIGNALER_S0/rp_TYPE_REVEIL_BAGUE_ECLAIRAGE
    delegate GERER_FX_POS.rp_ETAT_CPO_COND <-> outer port SIGNALER_S0/rp_ETAT_CPO_COND
    delegate GERER_FX_POS.pp_PILOTAGE_FEUX_POSITION_AVD <-> outer port SIGNALER_S0/pp_PILOTAGE_FEUX_POSITION_AVD
    delegate GERER_FX_POS.pp_PILOTAGE_FEUX_POSITION_AVG <-> outer port SIGNALER_S0/pp_PILOTAGE_FEUX_POSITION_AVG
    delegate GERER_FX_POS.pp_CMD_FEUX_POSITION_AR <-> outer port SIGNALER_S0/pp_CMD_FEUX_POSITION_AR
    delegate GERER_FX_POS.pp_ETAT_FEUX_POSITION <-> outer port SIGNALER_S0/pp_ETAT_FEUX_POSITION
    delegate GERER_FX_POS.pp_P_TEM_SIGN_FX_POS <-> outer port SIGNALER_S0/pp_P_TEM_SIGN_FX_POS
    delegate GERER_FX_POS.pp_DMD_ALLUMAGE_FEUX_CROISEMENT <-> outer port SIGNALER_S0/pp_DMD_ALLUMAGE_FEUX_CROISEMENT
    delegate GERER_FX_POS.pp_P_SON_SIGN_OUBLI_FEUX <-> outer port SIGNALER_S0/pp_P_SON_SIGN_OUBLI_FEUX
    delegate GERER_ETAT_JOUR_NUIT.rp_ETAT_ACTIVATION_FMH <-> outer port SIGNALER_S0/rp_ETAT_ACTIVATION_FMH
    delegate GERER_ETAT_JOUR_NUIT.rp_ETAT_ACTIVATION_PLUIE <-> outer port SIGNALER_S0/rp_ETAT_ACTIVATION_PLUIE
    delegate GERER_ETAT_JOUR_NUIT.rp_ETAT_ACTIVATION_ALL_LOCAL <-> outer port SIGNALER_S0/rp_ETAT_ACTIVATION_ALL_LOCAL
    delegate GERER_ETAT_JOUR_NUIT.rp_ETAT_ACTIVATION_ALL_DECONDA <-> outer port SIGNALER_S0/rp_ETAT_ACTIVATION_ALL_DECONDA
    delegate GERER_ETAT_JOUR_NUIT.pp_ETAT_JOUR_NUIT <-> outer port SIGNALER_S0/pp_ETAT_JOUR_NUIT
    delegate GERER_FX_ABAR.rp_ETAT_PRINCIP_SEV <-> outer port SIGNALER_S0/rp_ETAT_PRINCIP_SEV
    delegate GERER_FX_ABAR.rp_ETAT_RESEAU_ELECTRIQUE <-> outer port SIGNALER_S0/rp_ETAT_RESEAU_ELECTRIQUE
    delegate GERER_FX_ABAR.rp_DMD_ANTIBROUILLARD <-> outer port SIGNALER_S0/rp_DMD_ANTIBROUILLARD
    delegate GERER_FX_ABAR.rp_ETAT_ANTIBR_AV <-> outer port SIGNALER_S0/rp_ETAT_ANTIBR_AV
    delegate GERER_FX_ABAR.rp_ETAT_FEUX_CROISEMENT <-> outer port SIGNALER_S0/rp_ETAT_FEUX_CROISEMENT
    delegate GERER_FX_ABAR.rp_ETAT_FEUX_ROUTE <-> outer port SIGNALER_S0/rp_ETAT_FEUX_ROUTE
    delegate GERER_FX_ABAR.rp_PRESENCE_ANTIBR_AR <-> outer port SIGNALER_S0/rp_PRESENCE_ANTIBR_AR
    delegate GERER_FX_ABAR.pp_CMD_ANTIBR_AR <-> outer port SIGNALER_S0/pp_CMD_ANTIBR_AR
    delegate GERER_FX_ABAR.pp_ETAT_ANTIBR_AR <-> outer port SIGNALER_S0/pp_ETAT_ANTIBR_AR
    delegate GERER_FX_ABAR.pp_P_TEM_SIGN_FX_ABAR <-> outer port SIGNALER_S0/pp_P_TEM_SIGN_FX_ABAR
  internal behavior ib_GERER_FX_DIURNES: component=GERER_FX_DIURNES
    timing event evt_GERER_FX_DIURNES: start-on-event=GERER_FX_DIURNES, period=0.1
    runnable GERER_FX_DIURNES
      5 x data read access:
        dra_ETAT_PRINCIP_SEV: data-element=rp_ETAT_PRINCIP_SEV.ETAT_PRINCIP_SEV
        dra_ETAT_RESEAU_ELECTRIQUE: data-element=rp_ETAT_RESEAU_ELECTRIQUE.ETAT_RESEAU_ELECTRIQUE
        dra_ETAT_CMD_ECLAIRAGE: data-element=rp_ETAT_CMD_ECLAIRAGE.ETAT_CMD_ECLAIRAGE
        dra_DMDM_SIGN_ECL_FEUX_DIURNES: data-element=rp_DMDM_SIGN_ECL_FEUX_DIURNES.DMDM_SIGN_ECL_FEUX_DIURNES
        dra_DMD_ALLUMAGE_FEUX_POSITION: data-element=rp_DMD_ALLUMAGE_FEUX_POSITION.DMD_ALLUMAGE_FEUX_POSITION
      4 x data write access:
        dwa_PILOTAGE_FEU_DIURNE_DEDIE_D: data-element=pp_PILOTAGE_FEU_DIURNE_DEDIE_D.PILOTAGE_FEU_DIURNE_DEDIE_D
        dwa_PILOTAGE_FEU_DIURNE_DEDIE_G: data-element=pp_PILOTAGE_FEU_DIURNE_DEDIE_G.PILOTAGE_FEU_DIURNE_DEDIE_G
        dwa_ETAT_FEUX_DIURNES: data-element=pp_ETAT_FEUX_DIURNES.ETAT_FEUX_DIURNES
        dwa_P_TEM_SIGN_FX_DIURNES: data-element=pp_P_TEM_SIGN_FX_DIURNES.P_TEM_SIGN_FX_DIURNES
  8 x sender receiver interface:
    sri_ETAT_PRINCIP_SEV
      data ETAT_PRINCIP_SEV: type=AR_SIGNALER_SWC/UInt8
    sri_ETAT_CMD_ECLAIRAGE
      data ETAT_CMD_ECLAIRAGE: type=AR_SIGNALER_SWC/UInt8
    sri_DMDM_SIGN_ECL_FEUX_DIURNES
      data DMDM_SIGN_ECL_FEUX_DIURNES: type=AR_SIGNALER_SWC/Boolean
    sri_DMD_ALLUMAGE_FEUX_POSITION
      data DMD_ALLUMAGE_FEUX_POSITION: type=AR_SIGNALER_SWC/Boolean
    sri_PILOTAGE_FEU_DIURNE_DEDIE_D
      data PILOTAGE_FEU_DIURNE_DEDIE_D: type=AR_SIGNALER_SWC/Boolean
    sri_PILOTAGE_FEU_DIURNE_DEDIE_G
      data PILOTAGE_FEU_DIURNE_DEDIE_G: type=AR_SIGNALER_SWC/Boolean
    sri_ETAT_FEUX_DIURNES
      data ETAT_FEUX_DIURNES: type=AR_SIGNALER_SWC/Boolean
    sri_P_TEM_SIGN_FX_DIURNES
      data P_TEM_SIGN_FX_DIURNES: type=AR_SIGNALER_SWC/Boolean
  swc implementation implem_GERER_FX_DIURNES: programming-language=C, behavior=ib_GERER_FX_DIURNES
    code-descriptors:
      code implem_GERER_FX_DIURNES: type=SRC
        xfile GERER_FX_DIURNES.c: url=Src_C/GERER_FX_DIURNES.c
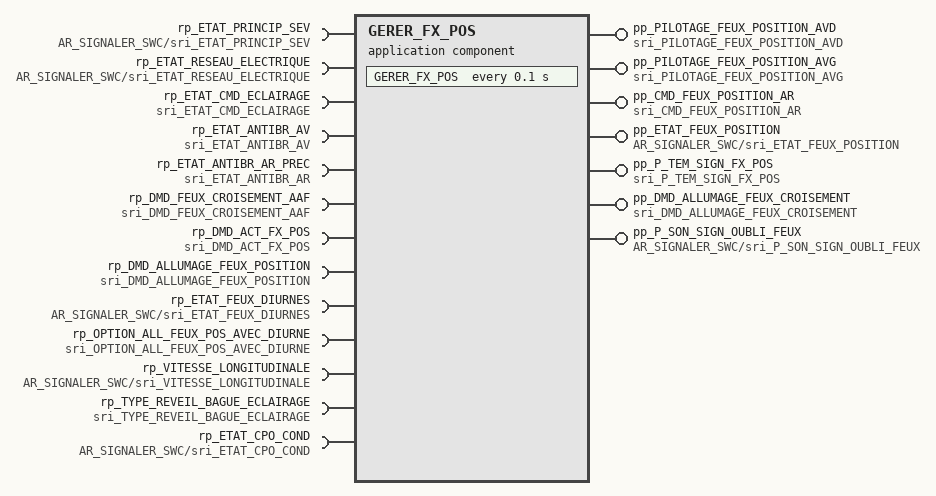
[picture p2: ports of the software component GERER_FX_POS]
  application software component type GERER_FX_POS
    13 x require port:
      rp_ETAT_PRINCIP_SEV: unqueued-receiver-com-spec{data-element=sri_ETAT_PRINCIP_SEV/ETAT_PRINCIP_SEV, handle-invalid=KEEP, init-value=cst_UInt8_init/uint8_init, resync-time=0.0}, required-interface=AR_SIGNALER_SWC/sri_ETAT_PRINCIP_SEV
      rp_ETAT_RESEAU_ELECTRIQUE: unqueued-receiver-com-spec{data-element=sri_ETAT_RESEAU_ELECTRIQUE/ETAT_RESEAU_ELECTRIQUE, handle-invalid=KEEP, init-value=cst_UInt8_init/uint8_init, resync-time=0.0}, required-interface=AR_SIGNALER_SWC/sri_ETAT_RESEAU_ELECTRIQUE
      rp_ETAT_CMD_ECLAIRAGE: unqueued-receiver-com-spec{data-element=ETAT_CMD_ECLAIRAGE, handle-invalid=KEEP, init-value=cst_UInt8_init/uint8_init, resync-time=0.0}, required-interface=sri_ETAT_CMD_ECLAIRAGE
      rp_ETAT_ANTIBR_AV: unqueued-receiver-com-spec{data-element=ETAT_ANTIBR_AV, handle-invalid=KEEP, init-value=cst_Boolean_init/boolean_init, resync-time=0.0}, required-interface=sri_ETAT_ANTIBR_AV
      rp_ETAT_ANTIBR_AR_PREC: unqueued-receiver-com-spec{data-element=ETAT_ANTIBR_AR, handle-invalid=KEEP, init-value=cst_Boolean_init/boolean_init, resync-time=0.0}, required-interface=sri_ETAT_ANTIBR_AR
      rp_DMD_FEUX_CROISEMENT_AAF: unqueued-receiver-com-spec{data-element=DMD_FEUX_CROISEMENT_AAF, handle-invalid=KEEP, init-value=cst_Boolean_init/boolean_init, resync-time=0.0}, required-interface=sri_DMD_FEUX_CROISEMENT_AAF
      rp_DMD_ACT_FX_POS: unqueued-receiver-com-spec{data-element=DMD_ACT_FX_POS, handle-invalid=KEEP, init-value=cst_Boolean_init/boolean_init, resync-time=0.0}, required-interface=sri_DMD_ACT_FX_POS
      rp_DMD_ALLUMAGE_FEUX_POSITION: unqueued-receiver-com-spec{data-element=DMD_ALLUMAGE_FEUX_POSITION, handle-invalid=KEEP, init-value=cst_Boolean_init/boolean_init, resync-time=0.0}, required-interface=sri_DMD_ALLUMAGE_FEUX_POSITION
      rp_ETAT_FEUX_DIURNES: unqueued-receiver-com-spec{data-element=sri_ETAT_FEUX_DIURNES/ETAT_FEUX_DIURNES, handle-invalid=KEEP, init-value=cst_Boolean_init/boolean_init, resync-time=0.0}, required-interface=AR_SIGNALER_SWC/sri_ETAT_FEUX_DIURNES
      rp_OPTION_ALL_FEUX_POS_AVEC_DIURNE: unqueued-receiver-com-spec{data-element=OPTION_ALL_FEUX_POS_AVEC_DIURNE, handle-invalid=KEEP, init-value=cst_Boolean_init/boolean_init, resync-time=0.0}, required-interface=sri_OPTION_ALL_FEUX_POS_AVEC_DIURNE
      rp_VITESSE_LONGITUDINALE: unqueued-receiver-com-spec{data-element=sri_VITESSE_LONGITUDINALE/VITESSE_LONGITUDINALE, handle-invalid=KEEP, init-value=cst_UInt16_init/uint16_init, resync-time=0.0}, required-interface=AR_SIGNALER_SWC/sri_VITESSE_LONGITUDINALE
      rp_TYPE_REVEIL_BAGUE_ECLAIRAGE: unqueued-receiver-com-spec{data-element=TYPE_REVEIL_BAGUE_ECLAIRAGE, handle-invalid=KEEP, init-value=cst_Boolean_init/boolean_init, resync-time=0.0}, required-interface=sri_TYPE_REVEIL_BAGUE_ECLAIRAGE
      rp_ETAT_CPO_COND: unqueued-receiver-com-spec{data-element=sri_ETAT_CPO_COND/ETAT_CPO_COND, handle-invalid=KEEP, init-value=cst_Boolean_init/boolean_init, resync-time=0.0}, required-interface=AR_SIGNALER_SWC/sri_ETAT_CPO_COND
    7 x provide port:
      pp_PILOTAGE_FEUX_POSITION_AVD: unqueued-sender-com-spec{data-element=PILOTAGE_FEUX_POSITION_AVD, init-value=cst_Boolean_init/boolean_init}, provided-interface=sri_PILOTAGE_FEUX_POSITION_AVD
      pp_PILOTAGE_FEUX_POSITION_AVG: unqueued-sender-com-spec{data-element=PILOTAGE_FEUX_POSITION_AVG, init-value=cst_Boolean_init/boolean_init}, provided-interface=sri_PILOTAGE_FEUX_POSITION_AVG
      pp_CMD_FEUX_POSITION_AR: unqueued-sender-com-spec{data-element=CMD_FEUX_POSITION_AR, init-value=cst_UInt8_init/uint8_init}, provided-interface=sri_CMD_FEUX_POSITION_AR
      pp_ETAT_FEUX_POSITION: unqueued-sender-com-spec{data-element=sri_ETAT_FEUX_POSITION/ETAT_FEUX_POSITION, init-value=cst_Boolean_init/boolean_init}, provided-interface=AR_SIGNALER_SWC/sri_ETAT_FEUX_POSITION
      pp_P_TEM_SIGN_FX_POS: unqueued-sender-com-spec{data-element=P_TEM_SIGN_FX_POS, init-value=cst_Boolean_init/boolean_init}, provided-interface=sri_P_TEM_SIGN_FX_POS
      pp_DMD_ALLUMAGE_FEUX_CROISEMENT: unqueued-sender-com-spec{data-element=DMD_ALLUMAGE_FEUX_CROISEMENT, init-value=cst_Boolean_init/boolean_init}, provided-interface=sri_DMD_ALLUMAGE_FEUX_CROISEMENT
      pp_P_SON_SIGN_OUBLI_FEUX: unqueued-sender-com-spec{data-element=sri_P_SON_SIGN_OUBLI_FEUX/P_SON_SIGN_OUBLI_FEUX, init-value=cst_Boolean_init/boolean_init}, provided-interface=AR_SIGNALER_SWC/sri_P_SON_SIGN_OUBLI_FEUX
  internal behavior ib_GERER_FX_POS: component=GERER_FX_POS
    timing event evt_GERER_FX_POS: start-on-event=GERER_FX_POS, period=0.1
    runnable GERER_FX_POS
      13 x data read access:
        dra_ETAT_PRINCIP_SEV: data-element=rp_ETAT_PRINCIP_SEV.ETAT_PRINCIP_SEV
        dra_ETAT_RESEAU_ELECTRIQUE: data-element=rp_ETAT_RESEAU_ELECTRIQUE.ETAT_RESEAU_ELECTRIQUE
        dra_ETAT_CMD_ECLAIRAGE: data-element=rp_ETAT_CMD_ECLAIRAGE.ETAT_CMD_ECLAIRAGE
        dra_ETAT_ANTIBR_AV: data-element=rp_ETAT_ANTIBR_AV.ETAT_ANTIBR_AV
        dra_ETAT_ANTIBR_AR: data-element=rp_ETAT_ANTIBR_AR_PREC.ETAT_ANTIBR_AR
        dra_DMD_FEUX_CROISEMENT_AAF: data-element=rp_DMD_FEUX_CROISEMENT_AAF.DMD_FEUX_CROISEMENT_AAF
        dra_DMD_ACT_FX_POS: data-element=rp_DMD_ACT_FX_POS.DMD_ACT_FX_POS
        dra_DMD_ALLUMAGE_FEUX_POSITION: data-element=rp_DMD_ALLUMAGE_FEUX_POSITION.DMD_ALLUMAGE_FEUX_POSITION
        dra_ETAT_FEUX_DIURNES: data-element=rp_ETAT_FEUX_DIURNES.ETAT_FEUX_DIURNES
        dra_OPTION_ALL_FEUX_POS_AVEC_DI: data-element=rp_OPTION_ALL_FEUX_POS_AVEC_DIURNE.OPTION_ALL_FEUX_POS_AVEC_DIURNE
        dra_VITESSE_LONGITUDINALE: data-element=rp_VITESSE_LONGITUDINALE.VITESSE_LONGITUDINALE
        dra_TYPE_REVEIL_BAGUE_ECLAIRAGE: data-element=rp_TYPE_REVEIL_BAGUE_ECLAIRAGE.TYPE_REVEIL_BAGUE_ECLAIRAGE
        dra_ETAT_CPO_COND: data-element=rp_ETAT_CPO_COND.ETAT_CPO_COND
      7 x data write access:
        dwa_PILOTAGE_FEUX_POSITION_AVD: data-element=pp_PILOTAGE_FEUX_POSITION_AVD.PILOTAGE_FEUX_POSITION_AVD
        dwa_PILOTAGE_FEUX_POSITION_AVG: data-element=pp_PILOTAGE_FEUX_POSITION_AVG.PILOTAGE_FEUX_POSITION_AVG
        dwa_CMD_FEUX_POSITION_AR: data-element=pp_CMD_FEUX_POSITION_AR.CMD_FEUX_POSITION_AR
        dwa_ETAT_FEUX_POSITION: data-element=pp_ETAT_FEUX_POSITION.ETAT_FEUX_POSITION
        dwa_P_TEM_SIGN_FX_POS: data-element=pp_P_TEM_SIGN_FX_POS.P_TEM_SIGN_FX_POS
        dwa_Q: data-element=pp_DMD_ALLUMAGE_FEUX_CROISEMENT.DMD_ALLUMAGE_FEUX_CROISEMENT
        dwa_P_SON_SIGN_OUBLI_FEUX: data-element=pp_P_SON_SIGN_OUBLI_FEUX.P_SON_SIGN_OUBLI_FEUX
  6 x sender receiver interface:
    sri_ETAT_ANTIBR_AV
      data ETAT_ANTIBR_AV: type=AR_SIGNALER_SWC/Boolean
    sri_ETAT_ANTIBR_AR
      data ETAT_ANTIBR_AR: type=AR_SIGNALER_SWC/Boolean
    sri_DMD_FEUX_CROISEMENT_AAF
      data DMD_FEUX_CROISEMENT_AAF: type=AR_SIGNALER_SWC/Boolean
    sri_DMD_ACT_FX_POS
      data DMD_ACT_FX_POS: type=AR_SIGNALER_SWC/Boolean
    sri_OPTION_ALL_FEUX_POS_AVEC_DIURNE
      data OPTION_ALL_FEUX_POS_AVEC_DIURNE: type=AR_SIGNALER_SWC/Boolean
    sri_VITESSE_LONGITUDINALE
      data VITESSE_LONGITUDINALE: type=AR_SIGNALER_SWC/UInt16
  constant specification cst_UInt16_init
    value:
      integer literal uint16_init: type=AR_SIGNALER_SWC/UInt16, value=0
  9 x sender receiver interface:
    sri_TYPE_REVEIL_BAGUE_ECLAIRAGE
      data TYPE_REVEIL_BAGUE_ECLAIRAGE: type=AR_SIGNALER_SWC/Boolean
    sri_ETAT_CPO_COND
      data ETAT_CPO_COND: type=AR_SIGNALER_SWC/Boolean
    sri_PILOTAGE_FEUX_POSITION_AVD
      data PILOTAGE_FEUX_POSITION_AVD: type=AR_SIGNALER_SWC/Boolean
    sri_PILOTAGE_FEUX_POSITION_AVG
      data PILOTAGE_FEUX_POSITION_AVG: type=AR_SIGNALER_SWC/Boolean
    sri_CMD_FEUX_POSITION_AR
      data CMD_FEUX_POSITION_AR: type=AR_SIGNALER_SWC/UInt8
    sri_ETAT_FEUX_POSITION
      data ETAT_FEUX_POSITION: type=AR_SIGNALER_SWC/Boolean
    sri_P_TEM_SIGN_FX_POS
      data P_TEM_SIGN_FX_POS: type=AR_SIGNALER_SWC/Boolean
    sri_DMD_ALLUMAGE_FEUX_CROISEMENT
      data DMD_ALLUMAGE_FEUX_CROISEMENT: type=AR_SIGNALER_SWC/Boolean
    sri_P_SON_SIGN_OUBLI_FEUX
      data P_SON_SIGN_OUBLI_FEUX: type=AR_SIGNALER_SWC/Boolean
  swc implementation implem_GERER_FX_POS: programming-language=C, behavior=ib_GERER_FX_POS
    code-descriptors:
      code implem_GERER_FX_POS: type=SRC
        xfile GERER_FX_POS.c: url=Src_C/GERER_FX_POS.c
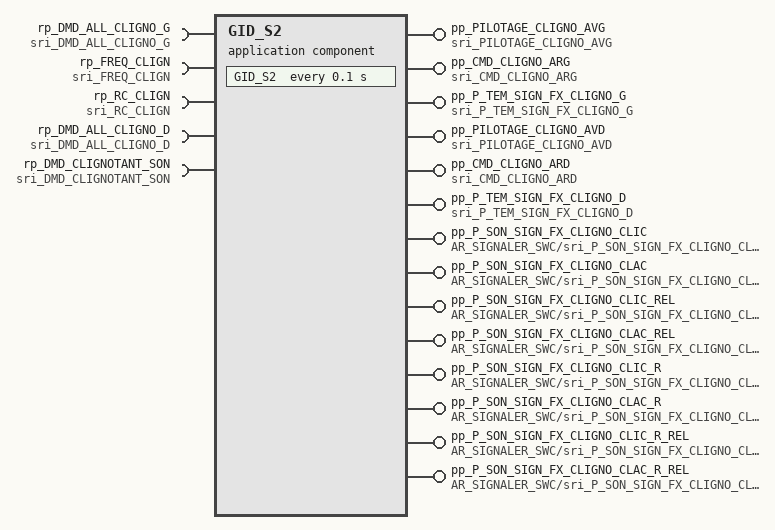
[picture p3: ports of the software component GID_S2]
  application software component type GID_S2
    5 x require port:
      rp_DMD_ALL_CLIGNO_G: unqueued-receiver-com-spec{data-element=DMD_ALL_CLIGNO_G, handle-invalid=KEEP, init-value=cst_Boolean_init/boolean_init, resync-time=0.0}, required-interface=sri_DMD_ALL_CLIGNO_G
      rp_FREQ_CLIGN: unqueued-receiver-com-spec{data-element=FREQ_CLIGN, handle-invalid=KEEP, init-value=cst_UInt16_init/uint16_init, resync-time=0.0}, required-interface=sri_FREQ_CLIGN
      rp_RC_CLIGN: unqueued-receiver-com-spec{data-element=RC_CLIGN, handle-invalid=KEEP, init-value=cst_UInt16_init/uint16_init, resync-time=0.0}, required-interface=sri_RC_CLIGN
      rp_DMD_ALL_CLIGNO_D: unqueued-receiver-com-spec{data-element=DMD_ALL_CLIGNO_D, handle-invalid=KEEP, init-value=cst_Boolean_init/boolean_init, resync-time=0.0}, required-interface=sri_DMD_ALL_CLIGNO_D
      rp_DMD_CLIGNOTANT_SON: unqueued-receiver-com-spec{data-element=DMD_CLIGNOTANT_SON, handle-invalid=KEEP, init-value=cst_Boolean_init/boolean_init, resync-time=0.0}, required-interface=sri_DMD_CLIGNOTANT_SON
    14 x provide port:
      pp_PILOTAGE_CLIGNO_AVG: unqueued-sender-com-spec{data-element=PILOTAGE_CLIGNO_AVG, init-value=cst_Boolean_init/boolean_init}, provided-interface=sri_PILOTAGE_CLIGNO_AVG
      pp_CMD_CLIGNO_ARG: unqueued-sender-com-spec{data-element=CMD_CLIGNO_ARG, init-value=cst_Boolean_init/boolean_init}, provided-interface=sri_CMD_CLIGNO_ARG
      pp_P_TEM_SIGN_FX_CLIGNO_G: unqueued-sender-com-spec{data-element=P_TEM_SIGN_FX_CLIGNO_G, init-value=cst_Boolean_init/boolean_init}, provided-interface=sri_P_TEM_SIGN_FX_CLIGNO_G
      pp_PILOTAGE_CLIGNO_AVD: unqueued-sender-com-spec{data-element=PILOTAGE_CLIGNO_AVD, init-value=cst_Boolean_init/boolean_init}, provided-interface=sri_PILOTAGE_CLIGNO_AVD
      pp_CMD_CLIGNO_ARD: unqueued-sender-com-spec{data-element=CMD_CLIGNO_ARD, init-value=cst_Boolean_init/boolean_init}, provided-interface=sri_CMD_CLIGNO_ARD
      pp_P_TEM_SIGN_FX_CLIGNO_D: unqueued-sender-com-spec{data-element=P_TEM_SIGN_FX_CLIGNO_D, init-value=cst_Boolean_init/boolean_init}, provided-interface=sri_P_TEM_SIGN_FX_CLIGNO_D
      pp_P_SON_SIGN_FX_CLIGNO_CLIC: unqueued-sender-com-spec{data-element=sri_P_SON_SIGN_FX_CLIGNO_CLIC/P_SON_SIGN_FX_CLIGNO_CLIC, init-value=cst_Boolean_init/boolean_init}, provided-interface=AR_SIGNALER_SWC/sri_P_SON_SIGN_FX_CLIGNO_CLIC
      pp_P_SON_SIGN_FX_CLIGNO_CLAC: unqueued-sender-com-spec{data-element=sri_P_SON_SIGN_FX_CLIGNO_CLAC/P_SON_SIGN_FX_CLIGNO_CLAC, init-value=cst_Boolean_init/boolean_init}, provided-interface=AR_SIGNALER_SWC/sri_P_SON_SIGN_FX_CLIGNO_CLAC
      pp_P_SON_SIGN_FX_CLIGNO_CLIC_REL: unqueued-sender-com-spec{data-element=sri_P_SON_SIGN_FX_CLIGNO_CLIC_REL/P_SON_SIGN_FX_CLIGNO_CLIC_REL, init-value=cst_Boolean_init/boolean_init}, provided-interface=AR_SIGNALER_SWC/sri_P_SON_SIGN_FX_CLIGNO_CLIC_REL
      pp_P_SON_SIGN_FX_CLIGNO_CLAC_REL: unqueued-sender-com-spec{data-element=sri_P_SON_SIGN_FX_CLIGNO_CLAC_REL/P_SON_SIGN_FX_CLIGNO_CLAC_REL, init-value=cst_Boolean_init/boolean_init}, provided-interface=AR_SIGNALER_SWC/sri_P_SON_SIGN_FX_CLIGNO_CLAC_REL
      pp_P_SON_SIGN_FX_CLIGNO_CLIC_R: unqueued-sender-com-spec{data-element=sri_P_SON_SIGN_FX_CLIGNO_CLIC_R/P_SON_SIGN_FX_CLIGNO_CLIC_R, init-value=cst_Boolean_init/boolean_init}, provided-interface=AR_SIGNALER_SWC/sri_P_SON_SIGN_FX_CLIGNO_CLIC_R
      pp_P_SON_SIGN_FX_CLIGNO_CLAC_R: unqueued-sender-com-spec{data-element=sri_P_SON_SIGN_FX_CLIGNO_CLAC_R/P_SON_SIGN_FX_CLIGNO_CLAC_R, init-value=cst_Boolean_init/boolean_init}, provided-interface=AR_SIGNALER_SWC/sri_P_SON_SIGN_FX_CLIGNO_CLAC_R
      pp_P_SON_SIGN_FX_CLIGNO_CLIC_R_REL: unqueued-sender-com-spec{data-element=sri_P_SON_SIGN_FX_CLIGNO_CLIC_R_REL/P_SON_SIGN_FX_CLIGNO_CLIC_R_REL, init-value=cst_Boolean_init/boolean_init}, provided-interface=AR_SIGNALER_SWC/sri_P_SON_SIGN_FX_CLIGNO_CLIC_R_REL
      pp_P_SON_SIGN_FX_CLIGNO_CLAC_R_REL: unqueued-sender-com-spec{data-element=sri_P_SON_SIGN_FX_CLIGNO_CLAC_R_REL/P_SON_SIGN_FX_CLIGNO_CLAC_R_REL, init-value=cst_Boolean_init/boolean_init}, provided-interface=AR_SIGNALER_SWC/sri_P_SON_SIGN_FX_CLIGNO_CLAC_R_REL
  composition type GID
    14 x provide port:
      pp_P_TEM_SIGN_FX_CLIGNO_G: unqueued-sender-com-spec{data-element=P_TEM_SIGN_FX_CLIGNO_G, init-value=cst_Boolean_init/boolean_init}, provided-interface=sri_P_TEM_SIGN_FX_CLIGNO_G
      pp_P_TEM_SIGN_FX_CLIGNO_D: unqueued-sender-com-spec{data-element=P_TEM_SIGN_FX_CLIGNO_D, init-value=cst_Boolean_init/boolean_init}, provided-interface=sri_P_TEM_SIGN_FX_CLIGNO_D
      pp_P_SON_SIGN_FX_CLIGNO_CLIC: unqueued-sender-com-spec{data-element=sri_P_SON_SIGN_FX_CLIGNO_CLIC/P_SON_SIGN_FX_CLIGNO_CLIC, init-value=cst_Boolean_init/boolean_init}, provided-interface=AR_SIGNALER_SWC/sri_P_SON_SIGN_FX_CLIGNO_CLIC
      pp_P_SON_SIGN_FX_CLIGNO_CLAC: unqueued-sender-com-spec{data-element=sri_P_SON_SIGN_FX_CLIGNO_CLAC/P_SON_SIGN_FX_CLIGNO_CLAC, init-value=cst_Boolean_init/boolean_init}, provided-interface=AR_SIGNALER_SWC/sri_P_SON_SIGN_FX_CLIGNO_CLAC
      pp_P_SON_SIGN_FX_CLIGNO_CLIC_R: unqueued-sender-com-spec{data-element=sri_P_SON_SIGN_FX_CLIGNO_CLIC_R/P_SON_SIGN_FX_CLIGNO_CLIC_R, init-value=cst_Boolean_init/boolean_init}, provided-interface=AR_SIGNALER_SWC/sri_P_SON_SIGN_FX_CLIGNO_CLIC_R
      pp_P_SON_SIGN_FX_CLIGNO_CLAC_R: unqueued-sender-com-spec{data-element=sri_P_SON_SIGN_FX_CLIGNO_CLAC_R/P_SON_SIGN_FX_CLIGNO_CLAC_R, init-value=cst_Boolean_init/boolean_init}, provided-interface=AR_SIGNALER_SWC/sri_P_SON_SIGN_FX_CLIGNO_CLAC_R
      pp_PILOTAGE_CLIGNO_AVG: unqueued-sender-com-spec{data-element=PILOTAGE_CLIGNO_AVG, init-value=cst_Boolean_init/boolean_init}, provided-interface=sri_PILOTAGE_CLIGNO_AVG
      pp_PILOTAGE_CLIGNO_AVD: unqueued-sender-com-spec{data-element=PILOTAGE_CLIGNO_AVD, init-value=cst_Boolean_init/boolean_init}, provided-interface=sri_PILOTAGE_CLIGNO_AVD
      pp_P_SON_SIGN_FX_CLIGNO_CLIC_REL: unqueued-sender-com-spec{data-element=sri_P_SON_SIGN_FX_CLIGNO_CLIC_REL/P_SON_SIGN_FX_CLIGNO_CLIC_REL, init-value=cst_Boolean_init/boolean_init}, provided-interface=AR_SIGNALER_SWC/sri_P_SON_SIGN_FX_CLIGNO_CLIC_REL
      pp_P_SON_SIGN_FX_CLIGNO_CLAC_REL: unqueued-sender-com-spec{data-element=sri_P_SON_SIGN_FX_CLIGNO_CLAC_REL/P_SON_SIGN_FX_CLIGNO_CLAC_REL, init-value=cst_Boolean_init/boolean_init}, provided-interface=AR_SIGNALER_SWC/sri_P_SON_SIGN_FX_CLIGNO_CLAC_REL
      pp_P_SON_SIGN_FX_CLIGNO_CLIC_R_REL: unqueued-sender-com-spec{data-element=sri_P_SON_SIGN_FX_CLIGNO_CLIC_R_REL/P_SON_SIGN_FX_CLIGNO_CLIC_R_REL, init-value=cst_Boolean_init/boolean_init}, provided-interface=AR_SIGNALER_SWC/sri_P_SON_SIGN_FX_CLIGNO_CLIC_R_REL
      pp_P_SON_SIGN_FX_CLIGNO_CLAC_R_REL: unqueued-sender-com-spec{data-element=sri_P_SON_SIGN_FX_CLIGNO_CLAC_R_REL/P_SON_SIGN_FX_CLIGNO_CLAC_R_REL, init-value=cst_Boolean_init/boolean_init}, provided-interface=AR_SIGNALER_SWC/sri_P_SON_SIGN_FX_CLIGNO_CLAC_R_REL
      pp_CMD_CLIGNO_ARG: unqueued-sender-com-spec{data-element=CMD_CLIGNO_ARG, init-value=cst_Boolean_init/boolean_init}, provided-interface=sri_CMD_CLIGNO_ARG
      pp_CMD_CLIGNO_ARD: unqueued-sender-com-spec{data-element=CMD_CLIGNO_ARD, init-value=cst_Boolean_init/boolean_init}, provided-interface=sri_CMD_CLIGNO_ARD
    require port rp_OPTION_CLIGNO_IMPULS: unqueued-receiver-com-spec{data-element=OPTION_CLIGNO_IMPULS, handle-invalid=KEEP, init-value=cst_Boolean_init/boolean_init, resync-time=0.0}, required-interface=sri_OPTION_CLIGNO_IMPULS
    require port rp_ETAT_PRINCIP_SEV: unqueued-receiver-com-spec{data-element=sri_ETAT_PRINCIP_SEV/ETAT_PRINCIP_SEV, handle-invalid=KEEP, init-value=cst_UInt8_init/uint8_init, resync-time=0.0}, required-interface=AR_SIGNALER_SWC/sri_ETAT_PRINCIP_SEV
    require port rp_ETAT_RESEAU_ELECTRIQUE: unqueued-receiver-com-spec{data-element=sri_ETAT_RESEAU_ELECTRIQUE/ETAT_RESEAU_ELECTRIQUE, handle-invalid=KEEP, init-value=cst_UInt8_init/uint8_init, resync-time=0.0}, required-interface=AR_SIGNALER_SWC/sri_ETAT_RESEAU_ELECTRIQUE
    5 x provide port:
      pp_ETAT_FEUX_DIRECTION: unqueued-sender-com-spec{data-element=ETAT_FEUX_DIRECTION, init-value=cst_UInt8_init/uint8_init}, provided-interface=sri_ETAT_FEUX_DIRECTION
      pp_ETAT_FEUX_DETRESSE: unqueued-sender-com-spec{data-element=sri_ETAT_FEUX_DETRESSE/ETAT_FEUX_DETRESSE, init-value=cst_Boolean_init/boolean_init}, provided-interface=AR_SIGNALER_SWC/sri_ETAT_FEUX_DETRESSE
      pp_ETAT_CLIGNOTANT_G: unqueued-sender-com-spec{data-element=sri_ETAT_CLIGNOTANT_G/ETAT_CLIGNOTANT_G, init-value=cst_Boolean_init/boolean_init}, provided-interface=AR_SIGNALER_SWC/sri_ETAT_CLIGNOTANT_G
      pp_ETAT_CLIGNOTANT_D: unqueued-sender-com-spec{data-element=sri_ETAT_CLIGNOTANT_D/ETAT_CLIGNOTANT_D, init-value=cst_Boolean_init/boolean_init}, provided-interface=AR_SIGNALER_SWC/sri_ETAT_CLIGNOTANT_D
      pp_P_LED_SIGN_PUSH_FEU_DET: unqueued-sender-com-spec{data-element=P_LED_SIGN_PUSH_FEU_DET, init-value=cst_Boolean_init/boolean_init}, provided-interface=sri_P_LED_SIGN_PUSH_FEU_DET
    18 x require port:
      rp_DMD_FEUX_DETRESSE: unqueued-receiver-com-spec{data-element=DMD_FEUX_DETRESSE, handle-invalid=KEEP, init-value=cst_Boolean_init/boolean_init, resync-time=0.0}, required-interface=sri_DMD_FEUX_DETRESSE
      rp_DEFAUT_CLIGNO_D: unqueued-receiver-com-spec{data-element=DEFAUT_CLIGNO_D, handle-invalid=KEEP, init-value=cst_Boolean_init/boolean_init, resync-time=0.0}, required-interface=sri_DEFAUT_CLIGNO_D
      rp_DEFAUT_CLIGNO_G: unqueued-receiver-com-spec{data-element=DEFAUT_CLIGNO_G, handle-invalid=KEEP, init-value=cst_Boolean_init/boolean_init, resync-time=0.0}, required-interface=sri_DEFAUT_CLIGNO_G
      rp_OPTION_POLICE: unqueued-receiver-com-spec{data-element=OPTION_POLICE, handle-invalid=KEEP, init-value=cst_Boolean_init/boolean_init, resync-time=0.0}, required-interface=sri_OPTION_POLICE
      rp_OPTION_ALL_WARNING_CHOC: unqueued-receiver-com-spec{data-element=OPTION_ALL_WARNING_CHOC, handle-invalid=KEEP, init-value=cst_Boolean_init/boolean_init, resync-time=0.0}, required-interface=sri_OPTION_ALL_WARNING_CHOC
      rp_ETAT_CONDA_OUV_AR: unqueued-receiver-com-spec{data-element=ETAT_CONDA_OUV_AR, handle-invalid=KEEP, init-value=cst_Boolean_init/boolean_init, resync-time=0.0}, required-interface=sri_ETAT_CONDA_OUV_AR
      rp_CHOC_FEUX_DET: unqueued-receiver-com-spec{data-element=CHOC_FEUX_DET, handle-invalid=KEEP, init-value=cst_Boolean_init/boolean_init, resync-time=0.0}, required-interface=sri_CHOC_FEUX_DET
      rp_INFO_CHOC_PIETON: unqueued-receiver-com-spec{data-element=INFO_CHOC_PIETON, handle-invalid=KEEP, init-value=cst_Boolean_init/boolean_init, resync-time=0.0}, required-interface=sri_INFO_CHOC_PIETON
      rp_VOLONTE_CONDUCTEUR: unqueued-receiver-com-spec{data-element=VOLONTE_CONDUCTEUR, handle-invalid=KEEP, init-value=cst_UInt8_init/uint8_init, resync-time=0.0}, required-interface=sri_VOLONTE_CONDUCTEUR
      rp_DMD_WARNING_FORTE_DECEL: unqueued-receiver-com-spec{data-element=DMD_WARNING_FORTE_DECEL, handle-invalid=KEEP, init-value=cst_Boolean_init/boolean_init, resync-time=0.0}, required-interface=sri_DMD_WARNING_FORTE_DECEL
      rp_OPTION_ALL_WARNING_FORTE_DECEL: unqueued-receiver-com-spec{data-element=OPTION_ALL_WARNING_FORTE_DECEL, handle-invalid=KEEP, init-value=cst_Boolean_init/boolean_init, resync-time=0.0}, required-interface=sri_OPTION_ALL_WARNING_FORTE_DECEL
      rp_FONCTION_SFU_DANS_UCFREIN: unqueued-receiver-com-spec{data-element=sri_FONCTION_SFU_DANS_UCFREIN/FNCT_SFU_UC_FREIN, handle-invalid=KEEP, init-value=cst_Boolean_init/boolean_init, resync-time=0.0}, required-interface=sri_FONCTION_SFU_DANS_UCFREIN
      rp_VITESSE_LONGITUDINALE: unqueued-receiver-com-spec{data-element=sri_VITESSE_LONGITUDINALE/VITESSE_LONGITUDINALE, handle-invalid=KEEP, init-value=cst_UInt16_init/uint16_init, resync-time=0.0}, required-interface=AR_SIGNALER_SWC/sri_VITESSE_LONGITUDINALE
      rp_DMD_LOCAL_TELECMD: unqueued-receiver-com-spec{data-element=sri_DMD_LOCAL_TELECMD/DMD_LOCAL_TELECMD, handle-invalid=KEEP, init-value=cst_Boolean_init/boolean_init, resync-time=0.0}, required-interface=AR_SIGNALER_SWC/sri_DMD_LOCAL_TELECMD
      rp_ETAT_CONDA: unqueued-receiver-com-spec{data-element=sri_ETAT_CONDA/ETAT_CONDA, handle-invalid=KEEP, init-value=cst_UInt8_init/uint8_init, resync-time=0.0}, required-interface=AR_SIGNALER_SWC/sri_ETAT_CONDA
      rp_TYPE_CONDA: unqueued-receiver-com-spec{data-element=sri_TYPE_CONDA/TYPE_CONDA, handle-invalid=KEEP, init-value=cst_UInt8_init/uint8_init, resync-time=0.0}, required-interface=AR_SIGNALER_SWC/sri_TYPE_CONDA
      rp_ETAT_COMMODO_CLIGNO: unqueued-receiver-com-spec{data-element=ETAT_COMMODO_CLIGNO, handle-invalid=KEEP, init-value=cst_UInt8_init/uint8_init, resync-time=0.0}, required-interface=sri_ETAT_COMMODO_CLIGNO
      rp_MODE_CONFIG_VHL: unqueued-receiver-com-spec{data-element=MODE_CONFIG_VHL, handle-invalid=KEEP, init-value=cst_UInt8_init/uint8_init, resync-time=0.0}, required-interface=sri_MODE_CONFIG_VHL
    component GID_S2: type=GID_S2
    component GID_S1: type=GID_S1
    component GID_S0: type=GID_S0
    connect GID_S1.pp_DMD_ALL_CLIGNO_G -> GID_S2.rp_DMD_ALL_CLIGNO_G
    connect GID_S1.pp_DMD_ALL_CLIGNO_D -> GID_S2.rp_DMD_ALL_CLIGNO_D
    connect GID_S1.pp_DMD_CLIGNOTANT_SON -> GID_S2.rp_DMD_CLIGNOTANT_SON
    connect GID_S2.pp_PILOTAGE_CLIGNO_AVG -> GID_S1.rp_PILOTAGE_CLIGNO_AVG_PREC
    connect GID_S2.pp_PILOTAGE_CLIGNO_AVD -> GID_S1.rp_PILOTAGE_CLIGNO_AVD_PREC
    connect GID_S0.pp_FREQ_CLIGN -> GID_S2.rp_FREQ_CLIGN
    connect GID_S0.pp_RC_CLIGN -> GID_S2.rp_RC_CLIGN
    connect GID_S0.pp_DMD_FEUX_DETRESSE_STABLE -> GID_S1.rp_DMD_FEUX_DETRESSE_STABLE
    connect GID_S0.pp_DMD_SON_VALIDE -> GID_S1.rp_DMD_SON_VALIDE
    connect GID_S0.pp_ECC_PAS_DE_CMD_mdf -> GID_S1.rp_ECC_PAS_DE_CMD_mdf
    connect GID_S0.pp_ECC_CLIGNO_G_mdf -> GID_S1.rp_ECC_CLIGNO_G_mdf
    connect GID_S0.pp_ECC_CLIGNO_D_mdf -> GID_S1.rp_ECC_CLIGNO_D_mdf
    connect GID_S1.pp_ETAT_FEUX_DIRECTION -> GID_S0.rp_ETAT_FEUX_DIRECTION_PREC
    delegate GID_S2.pp_P_TEM_SIGN_FX_CLIGNO_G <-> outer port GID/pp_P_TEM_SIGN_FX_CLIGNO_G
    delegate GID_S2.pp_P_TEM_SIGN_FX_CLIGNO_D <-> outer port GID/pp_P_TEM_SIGN_FX_CLIGNO_D
    delegate GID_S2.pp_P_SON_SIGN_FX_CLIGNO_CLIC <-> outer port GID/pp_P_SON_SIGN_FX_CLIGNO_CLIC
    delegate GID_S2.pp_P_SON_SIGN_FX_CLIGNO_CLAC <-> outer port GID/pp_P_SON_SIGN_FX_CLIGNO_CLAC
    delegate GID_S2.pp_P_SON_SIGN_FX_CLIGNO_CLIC_R <-> outer port GID/pp_P_SON_SIGN_FX_CLIGNO_CLIC_R
    delegate GID_S2.pp_P_SON_SIGN_FX_CLIGNO_CLAC_R <-> outer port GID/pp_P_SON_SIGN_FX_CLIGNO_CLAC_R
    delegate GID_S2.pp_PILOTAGE_CLIGNO_AVG <-> outer port GID/pp_PILOTAGE_CLIGNO_AVG
    delegate GID_S2.pp_PILOTAGE_CLIGNO_AVD <-> outer port GID/pp_PILOTAGE_CLIGNO_AVD
    delegate GID_S2.pp_P_SON_SIGN_FX_CLIGNO_CLIC_REL <-> outer port GID/pp_P_SON_SIGN_FX_CLIGNO_CLIC_REL
    delegate GID_S2.pp_P_SON_SIGN_FX_CLIGNO_CLAC_REL <-> outer port GID/pp_P_SON_SIGN_FX_CLIGNO_CLAC_REL
    delegate GID_S2.pp_P_SON_SIGN_FX_CLIGNO_CLIC_R_REL <-> outer port GID/pp_P_SON_SIGN_FX_CLIGNO_CLIC_R_REL
    delegate GID_S2.pp_P_SON_SIGN_FX_CLIGNO_CLAC_R_REL <-> outer port GID/pp_P_SON_SIGN_FX_CLIGNO_CLAC_R_REL
    delegate GID_S2.pp_CMD_CLIGNO_ARG <-> outer port GID/pp_CMD_CLIGNO_ARG
    delegate GID_S2.pp_CMD_CLIGNO_ARD <-> outer port GID/pp_CMD_CLIGNO_ARD
    delegate GID_S1.rp_OPTION_CLIGNO_IMPULS <-> outer port GID/rp_OPTION_CLIGNO_IMPULS
    delegate GID_S1.rp_ETAT_PRINCIP_SEV <-> outer port GID/rp_ETAT_PRINCIP_SEV
    delegate GID_S1.rp_ETAT_RESEAU_ELECTRIQUE <-> outer port GID/rp_ETAT_RESEAU_ELECTRIQUE
    delegate GID_S1.pp_ETAT_FEUX_DIRECTION <-> outer port GID/pp_ETAT_FEUX_DIRECTION
    delegate GID_S1.pp_ETAT_FEUX_DETRESSE <-> outer port GID/pp_ETAT_FEUX_DETRESSE
    delegate GID_S1.pp_ETAT_CLIGNOTANT_G <-> outer port GID/pp_ETAT_CLIGNOTANT_G
    delegate GID_S1.pp_ETAT_CLIGNOTANT_D <-> outer port GID/pp_ETAT_CLIGNOTANT_D
    delegate GID_S1.pp_P_LED_SIGN_PUSH_FEU_DET <-> outer port GID/pp_P_LED_SIGN_PUSH_FEU_DET
    delegate GID_S0.rp_DMD_FEUX_DETRESSE <-> outer port GID/rp_DMD_FEUX_DETRESSE
    delegate GID_S0.rp_DEFAUT_CLIGNO_D <-> outer port GID/rp_DEFAUT_CLIGNO_D
    delegate GID_S0.rp_DEFAUT_CLIGNO_G <-> outer port GID/rp_DEFAUT_CLIGNO_G
    delegate GID_S0.rp_OPTION_POLICE <-> outer port GID/rp_OPTION_POLICE
    delegate GID_S0.rp_OPTION_ALL_WARNING_CHOC <-> outer port GID/rp_OPTION_ALL_WARNING_CHOC
    delegate GID_S0.rp_ETAT_CONDA_OUV_AR <-> outer port GID/rp_ETAT_CONDA_OUV_AR
    delegate GID_S0.rp_CHOC_FEUX_DET <-> outer port GID/rp_CHOC_FEUX_DET
    delegate GID_S0.rp_INFO_CHOC_PIETON <-> outer port GID/rp_INFO_CHOC_PIETON
    delegate GID_S0.rp_VOLONTE_CONDUCTEUR <-> outer port GID/rp_VOLONTE_CONDUCTEUR
    delegate GID_S0.rp_DMD_WARNING_FORTE_DECEL <-> outer port GID/rp_DMD_WARNING_FORTE_DECEL
    delegate GID_S0.rp_OPTION_ALL_WARNING_FORTE_DECEL <-> outer port GID/rp_OPTION_ALL_WARNING_FORTE_DECEL
    delegate GID_S0.rp_FONCTION_SFU_DANS_UCFREIN <-> outer port GID/rp_FONCTION_SFU_DANS_UCFREIN
    delegate GID_S0.rp_VITESSE_LONGITUDINALE <-> outer port GID/rp_VITESSE_LONGITUDINALE
    delegate GID_S0.rp_DMD_LOCAL_TELECMD <-> outer port GID/rp_DMD_LOCAL_TELECMD
    delegate GID_S0.rp_ETAT_CONDA <-> outer port GID/rp_ETAT_CONDA
    delegate GID_S0.rp_TYPE_CONDA <-> outer port GID/rp_TYPE_CONDA
    delegate GID_S0.rp_ETAT_PRINCIP_SEV <-> outer port GID/rp_ETAT_PRINCIP_SEV
    delegate GID_S0.rp_ETAT_COMMODO_CLIGNO <-> outer port GID/rp_ETAT_COMMODO_CLIGNO
    delegate GID_S0.rp_ETAT_RESEAU_ELECTRIQUE <-> outer port GID/rp_ETAT_RESEAU_ELECTRIQUE
    delegate GID_S0.rp_MODE_CONFIG_VHL <-> outer port GID/rp_MODE_CONFIG_VHL
  composition type SIGNALER_S2
    14 x provide port:
      pp_P_TEM_SIGN_FX_CLIGNO_G: unqueued-sender-com-spec{data-element=P_TEM_SIGN_FX_CLIGNO_G, init-value=cst_Boolean_init/boolean_init}, provided-interface=sri_P_TEM_SIGN_FX_CLIGNO_G
      pp_P_TEM_SIGN_FX_CLIGNO_D: unqueued-sender-com-spec{data-element=P_TEM_SIGN_FX_CLIGNO_D, init-value=cst_Boolean_init/boolean_init}, provided-interface=sri_P_TEM_SIGN_FX_CLIGNO_D
      pp_P_SON_SIGN_FX_CLIGNO_CLIC: unqueued-sender-com-spec{data-element=sri_P_SON_SIGN_FX_CLIGNO_CLIC/P_SON_SIGN_FX_CLIGNO_CLIC, init-value=cst_Boolean_init/boolean_init}, provided-interface=AR_SIGNALER_SWC/sri_P_SON_SIGN_FX_CLIGNO_CLIC
      pp_P_SON_SIGN_FX_CLIGNO_CLAC: unqueued-sender-com-spec{data-element=sri_P_SON_SIGN_FX_CLIGNO_CLAC/P_SON_SIGN_FX_CLIGNO_CLAC, init-value=cst_Boolean_init/boolean_init}, provided-interface=AR_SIGNALER_SWC/sri_P_SON_SIGN_FX_CLIGNO_CLAC
      pp_P_SON_SIGN_FX_CLIGNO_CLIC_R: unqueued-sender-com-spec{data-element=sri_P_SON_SIGN_FX_CLIGNO_CLIC_R/P_SON_SIGN_FX_CLIGNO_CLIC_R, init-value=cst_Boolean_init/boolean_init}, provided-interface=AR_SIGNALER_SWC/sri_P_SON_SIGN_FX_CLIGNO_CLIC_R
      pp_P_SON_SIGN_FX_CLIGNO_CLAC_R: unqueued-sender-com-spec{data-element=sri_P_SON_SIGN_FX_CLIGNO_CLAC_R/P_SON_SIGN_FX_CLIGNO_CLAC_R, init-value=cst_Boolean_init/boolean_init}, provided-interface=AR_SIGNALER_SWC/sri_P_SON_SIGN_FX_CLIGNO_CLAC_R
      pp_PILOTAGE_CLIGNO_AVG: unqueued-sender-com-spec{data-element=PILOTAGE_CLIGNO_AVG, init-value=cst_Boolean_init/boolean_init}, provided-interface=sri_PILOTAGE_CLIGNO_AVG
      pp_PILOTAGE_CLIGNO_AVD: unqueued-sender-com-spec{data-element=PILOTAGE_CLIGNO_AVD, init-value=cst_Boolean_init/boolean_init}, provided-interface=sri_PILOTAGE_CLIGNO_AVD
      pp_P_SON_SIGN_FX_CLIGNO_CLIC_REL: unqueued-sender-com-spec{data-element=sri_P_SON_SIGN_FX_CLIGNO_CLIC_REL/P_SON_SIGN_FX_CLIGNO_CLIC_REL, init-value=cst_Boolean_init/boolean_init}, provided-interface=AR_SIGNALER_SWC/sri_P_SON_SIGN_FX_CLIGNO_CLIC_REL
      pp_P_SON_SIGN_FX_CLIGNO_CLAC_REL: unqueued-sender-com-spec{data-element=sri_P_SON_SIGN_FX_CLIGNO_CLAC_REL/P_SON_SIGN_FX_CLIGNO_CLAC_REL, init-value=cst_Boolean_init/boolean_init}, provided-interface=AR_SIGNALER_SWC/sri_P_SON_SIGN_FX_CLIGNO_CLAC_REL
      pp_P_SON_SIGN_FX_CLIGNO_CLIC_R_REL: unqueued-sender-com-spec{data-element=sri_P_SON_SIGN_FX_CLIGNO_CLIC_R_REL/P_SON_SIGN_FX_CLIGNO_CLIC_R_REL, init-value=cst_Boolean_init/boolean_init}, provided-interface=AR_SIGNALER_SWC/sri_P_SON_SIGN_FX_CLIGNO_CLIC_R_REL
      pp_P_SON_SIGN_FX_CLIGNO_CLAC_R_REL: unqueued-sender-com-spec{data-element=sri_P_SON_SIGN_FX_CLIGNO_CLAC_R_REL/P_SON_SIGN_FX_CLIGNO_CLAC_R_REL, init-value=cst_Boolean_init/boolean_init}, provided-interface=AR_SIGNALER_SWC/sri_P_SON_SIGN_FX_CLIGNO_CLAC_R_REL
      pp_CMD_CLIGNO_ARG: unqueued-sender-com-spec{data-element=CMD_CLIGNO_ARG, init-value=cst_Boolean_init/boolean_init}, provided-interface=sri_CMD_CLIGNO_ARG
      pp_CMD_CLIGNO_ARD: unqueued-sender-com-spec{data-element=CMD_CLIGNO_ARD, init-value=cst_Boolean_init/boolean_init}, provided-interface=sri_CMD_CLIGNO_ARD
    7 x require port:
      rp_DIAG_CLIGNO_AVD: unqueued-receiver-com-spec{data-element=DIAG_CLIGNO_AVD, handle-invalid=KEEP, init-value=cst_UInt8_init/uint8_init, resync-time=0.0}, required-interface=sri_DIAG_CLIGNO_AVD
      rp_DIAG_CLIGNO_ARD: unqueued-receiver-com-spec{data-element=DIAG_CLIGNO_ARD, handle-invalid=KEEP, init-value=cst_UInt8_init/uint8_init, resync-time=0.0}, required-interface=sri_DIAG_CLIGNO_ARD
      rp_DIAG_CLIGNO_AVG: unqueued-receiver-com-spec{data-element=DIAG_CLIGNO_AVG, handle-invalid=KEEP, init-value=cst_UInt8_init/uint8_init, resync-time=0.0}, required-interface=sri_DIAG_CLIGNO_AVG
      rp_DIAG_CLIGNO_ARG: unqueued-receiver-com-spec{data-element=DIAG_CLIGNO_ARG, handle-invalid=KEEP, init-value=cst_UInt8_init/uint8_init, resync-time=0.0}, required-interface=sri_DIAG_CLIGNO_ARG
      rp_OPTION_CLIGNO_IMPULS: unqueued-receiver-com-spec{data-element=OPTION_CLIGNO_IMPULS, handle-invalid=KEEP, init-value=cst_Boolean_init/boolean_init, resync-time=0.0}, required-interface=sri_OPTION_CLIGNO_IMPULS
      rp_ETAT_PRINCIP_SEV: unqueued-receiver-com-spec{data-element=sri_ETAT_PRINCIP_SEV/ETAT_PRINCIP_SEV, handle-invalid=KEEP, init-value=cst_UInt8_init/uint8_init, resync-time=0.0}, required-interface=AR_SIGNALER_SWC/sri_ETAT_PRINCIP_SEV
      rp_ETAT_RESEAU_ELECTRIQUE: unqueued-receiver-com-spec{data-element=sri_ETAT_RESEAU_ELECTRIQUE/ETAT_RESEAU_ELECTRIQUE, handle-invalid=KEEP, init-value=cst_UInt8_init/uint8_init, resync-time=0.0}, required-interface=AR_SIGNALER_SWC/sri_ETAT_RESEAU_ELECTRIQUE
    5 x provide port:
      pp_ETAT_FEUX_DIRECTION: unqueued-sender-com-spec{data-element=ETAT_FEUX_DIRECTION, init-value=cst_UInt8_init/uint8_init}, provided-interface=sri_ETAT_FEUX_DIRECTION
      pp_ETAT_FEUX_DETRESSE: unqueued-sender-com-spec{data-element=sri_ETAT_FEUX_DETRESSE/ETAT_FEUX_DETRESSE, init-value=cst_Boolean_init/boolean_init}, provided-interface=AR_SIGNALER_SWC/sri_ETAT_FEUX_DETRESSE
      pp_ETAT_CLIGNOTANT_G: unqueued-sender-com-spec{data-element=sri_ETAT_CLIGNOTANT_G/ETAT_CLIGNOTANT_G, init-value=cst_Boolean_init/boolean_init}, provided-interface=AR_SIGNALER_SWC/sri_ETAT_CLIGNOTANT_G
      pp_ETAT_CLIGNOTANT_D: unqueued-sender-com-spec{data-element=sri_ETAT_CLIGNOTANT_D/ETAT_CLIGNOTANT_D, init-value=cst_Boolean_init/boolean_init}, provided-interface=AR_SIGNALER_SWC/sri_ETAT_CLIGNOTANT_D
      pp_P_LED_SIGN_PUSH_FEU_DET: unqueued-sender-com-spec{data-element=P_LED_SIGN_PUSH_FEU_DET, init-value=cst_Boolean_init/boolean_init}, provided-interface=sri_P_LED_SIGN_PUSH_FEU_DET
    16 x require port:
      rp_DMD_FEUX_DETRESSE: unqueued-receiver-com-spec{data-element=DMD_FEUX_DETRESSE, handle-invalid=KEEP, init-value=cst_Boolean_init/boolean_init, resync-time=0.0}, required-interface=sri_DMD_FEUX_DETRESSE
      rp_OPTION_POLICE: unqueued-receiver-com-spec{data-element=OPTION_POLICE, handle-invalid=KEEP, init-value=cst_Boolean_init/boolean_init, resync-time=0.0}, required-interface=sri_OPTION_POLICE
      rp_OPTION_ALL_WARNING_CHOC: unqueued-receiver-com-spec{data-element=OPTION_ALL_WARNING_CHOC, handle-invalid=KEEP, init-value=cst_Boolean_init/boolean_init, resync-time=0.0}, required-interface=sri_OPTION_ALL_WARNING_CHOC
      rp_ETAT_CONDA_OUV_AR: unqueued-receiver-com-spec{data-element=ETAT_CONDA_OUV_AR, handle-invalid=KEEP, init-value=cst_Boolean_init/boolean_init, resync-time=0.0}, required-interface=sri_ETAT_CONDA_OUV_AR
      rp_CHOC_FEUX_DET: unqueued-receiver-com-spec{data-element=CHOC_FEUX_DET, handle-invalid=KEEP, init-value=cst_Boolean_init/boolean_init, resync-time=0.0}, required-interface=sri_CHOC_FEUX_DET
      rp_INFO_CHOC_PIETON: unqueued-receiver-com-spec{data-element=INFO_CHOC_PIETON, handle-invalid=KEEP, init-value=cst_Boolean_init/boolean_init, resync-time=0.0}, required-interface=sri_INFO_CHOC_PIETON
      rp_VOLONTE_CONDUCTEUR: unqueued-receiver-com-spec{data-element=VOLONTE_CONDUCTEUR, handle-invalid=KEEP, init-value=cst_UInt8_init/uint8_init, resync-time=0.0}, required-interface=sri_VOLONTE_CONDUCTEUR
      rp_DMD_WARNING_FORTE_DECEL: unqueued-receiver-com-spec{data-element=DMD_WARNING_FORTE_DECEL, handle-invalid=KEEP, init-value=cst_Boolean_init/boolean_init, resync-time=0.0}, required-interface=sri_DMD_WARNING_FORTE_DECEL
      rp_OPTION_ALL_WARNING_FORTE_DECEL: unqueued-receiver-com-spec{data-element=OPTION_ALL_WARNING_FORTE_DECEL, handle-invalid=KEEP, init-value=cst_Boolean_init/boolean_init, resync-time=0.0}, required-interface=sri_OPTION_ALL_WARNING_FORTE_DECEL
      rp_FONCTION_SFU_DANS_UCFREIN: unqueued-receiver-com-spec{data-element=sri_FNCT_SFU_UC_FREIN/FNCT_SFU_UC_FREIN, handle-invalid=KEEP, init-value=cst_Boolean_init/boolean_init, resync-time=0.0}, required-interface=sri_FNCT_SFU_UC_FREIN
      rp_VITESSE_LONGITUDINALE: unqueued-receiver-com-spec{data-element=sri_VITESSE_LONGITUDINALE/VITESSE_LONGITUDINALE, handle-invalid=KEEP, init-value=cst_UInt16_init/uint16_init, resync-time=0.0}, required-interface=AR_SIGNALER_SWC/sri_VITESSE_LONGITUDINALE
      rp_DMD_LOCAL_TELECMD: unqueued-receiver-com-spec{data-element=sri_DMD_LOCAL_TELECMD/DMD_LOCAL_TELECMD, handle-invalid=KEEP, init-value=cst_Boolean_init/boolean_init, resync-time=0.0}, required-interface=AR_SIGNALER_SWC/sri_DMD_LOCAL_TELECMD
      rp_ETAT_CONDA: unqueued-receiver-com-spec{data-element=sri_ETAT_CONDA/ETAT_CONDA, handle-invalid=KEEP, init-value=cst_UInt8_init/uint8_init, resync-time=0.0}, required-interface=AR_SIGNALER_SWC/sri_ETAT_CONDA
      rp_TYPE_CONDA: unqueued-receiver-com-spec{data-element=sri_TYPE_CONDA/TYPE_CONDA, handle-invalid=KEEP, init-value=cst_UInt8_init/uint8_init, resync-time=0.0}, required-interface=AR_SIGNALER_SWC/sri_TYPE_CONDA
      rp_ETAT_COMMODO_CLIGNO: unqueued-receiver-com-spec{data-element=ETAT_COMMODO_CLIGNO, handle-invalid=KEEP, init-value=cst_UInt8_init/uint8_init, resync-time=0.0}, required-interface=sri_ETAT_COMMODO_CLIGNO
      rp_MODE_CONFIG_VHL: unqueued-receiver-com-spec{data-element=MODE_CONFIG_VHL, handle-invalid=KEEP, init-value=cst_UInt8_init/uint8_init, resync-time=0.0}, required-interface=sri_MODE_CONFIG_VHL
    component GID: type=GID
    component GESD: type=GESD
    delegate GID.pp_P_TEM_SIGN_FX_CLIGNO_G <-> outer port SIGNALER_S2/pp_P_TEM_SIGN_FX_CLIGNO_G
    delegate GID.pp_P_TEM_SIGN_FX_CLIGNO_D <-> outer port SIGNALER_S2/pp_P_TEM_SIGN_FX_CLIGNO_D
    delegate GID.pp_P_SON_SIGN_FX_CLIGNO_CLIC <-> outer port SIGNALER_S2/pp_P_SON_SIGN_FX_CLIGNO_CLIC
    delegate GID.pp_P_SON_SIGN_FX_CLIGNO_CLAC <-> outer port SIGNALER_S2/pp_P_SON_SIGN_FX_CLIGNO_CLAC
    delegate GID.pp_P_SON_SIGN_FX_CLIGNO_CLIC_R <-> outer port SIGNALER_S2/pp_P_SON_SIGN_FX_CLIGNO_CLIC_R
    delegate GID.pp_P_SON_SIGN_FX_CLIGNO_CLAC_R <-> outer port SIGNALER_S2/pp_P_SON_SIGN_FX_CLIGNO_CLAC_R
    delegate GID.pp_PILOTAGE_CLIGNO_AVG <-> outer port SIGNALER_S2/pp_PILOTAGE_CLIGNO_AVG
    delegate GID.pp_PILOTAGE_CLIGNO_AVD <-> outer port SIGNALER_S2/pp_PILOTAGE_CLIGNO_AVD
    delegate GID.pp_P_SON_SIGN_FX_CLIGNO_CLIC_REL <-> outer port SIGNALER_S2/pp_P_SON_SIGN_FX_CLIGNO_CLIC_REL
    delegate GID.pp_P_SON_SIGN_FX_CLIGNO_CLAC_REL <-> outer port SIGNALER_S2/pp_P_SON_SIGN_FX_CLIGNO_CLAC_REL
    delegate GID.pp_P_SON_SIGN_FX_CLIGNO_CLIC_R_REL <-> outer port SIGNALER_S2/pp_P_SON_SIGN_FX_CLIGNO_CLIC_R_REL
    delegate GID.pp_P_SON_SIGN_FX_CLIGNO_CLAC_R_REL <-> outer port SIGNALER_S2/pp_P_SON_SIGN_FX_CLIGNO_CLAC_R_REL
    delegate GID.pp_CMD_CLIGNO_ARG <-> outer port SIGNALER_S2/pp_CMD_CLIGNO_ARG
    delegate GID.pp_CMD_CLIGNO_ARD <-> outer port SIGNALER_S2/pp_CMD_CLIGNO_ARD
    delegate GESD.rp_DIAG_CLIGNO_AVD <-> outer port SIGNALER_S2/rp_DIAG_CLIGNO_AVD
    delegate GESD.rp_DIAG_CLIGNO_ARD <-> outer port SIGNALER_S2/rp_DIAG_CLIGNO_ARD
    delegate GESD.rp_DIAG_CLIGNO_AVG <-> outer port SIGNALER_S2/rp_DIAG_CLIGNO_AVG
    delegate GESD.rp_DIAG_CLIGNO_ARG <-> outer port SIGNALER_S2/rp_DIAG_CLIGNO_ARG
    delegate GID.rp_OPTION_CLIGNO_IMPULS <-> outer port SIGNALER_S2/rp_OPTION_CLIGNO_IMPULS
    delegate GID.rp_ETAT_PRINCIP_SEV <-> outer port SIGNALER_S2/rp_ETAT_PRINCIP_SEV
    delegate GID.rp_ETAT_RESEAU_ELECTRIQUE <-> outer port SIGNALER_S2/rp_ETAT_RESEAU_ELECTRIQUE
    delegate GID.pp_ETAT_FEUX_DIRECTION <-> outer port SIGNALER_S2/pp_ETAT_FEUX_DIRECTION
    delegate GID.pp_ETAT_FEUX_DETRESSE <-> outer port SIGNALER_S2/pp_ETAT_FEUX_DETRESSE
    delegate GID.pp_ETAT_CLIGNOTANT_G <-> outer port SIGNALER_S2/pp_ETAT_CLIGNOTANT_G
    delegate GID.pp_ETAT_CLIGNOTANT_D <-> outer port SIGNALER_S2/pp_ETAT_CLIGNOTANT_D
    delegate GID.pp_P_LED_SIGN_PUSH_FEU_DET <-> outer port SIGNALER_S2/pp_P_LED_SIGN_PUSH_FEU_DET
    delegate GID.rp_DMD_FEUX_DETRESSE <-> outer port SIGNALER_S2/rp_DMD_FEUX_DETRESSE
    delegate GID.rp_OPTION_POLICE <-> outer port SIGNALER_S2/rp_OPTION_POLICE
    delegate GID.rp_OPTION_ALL_WARNING_CHOC <-> outer port SIGNALER_S2/rp_OPTION_ALL_WARNING_CHOC
    delegate GID.rp_ETAT_CONDA_OUV_AR <-> outer port SIGNALER_S2/rp_ETAT_CONDA_OUV_AR
    delegate GID.rp_CHOC_FEUX_DET <-> outer port SIGNALER_S2/rp_CHOC_FEUX_DET
    delegate GID.rp_INFO_CHOC_PIETON <-> outer port SIGNALER_S2/rp_INFO_CHOC_PIETON
    delegate GID.rp_VOLONTE_CONDUCTEUR <-> outer port SIGNALER_S2/rp_VOLONTE_CONDUCTEUR
    delegate GID.rp_DMD_WARNING_FORTE_DECEL <-> outer port SIGNALER_S2/rp_DMD_WARNING_FORTE_DECEL
    delegate GID.rp_OPTION_ALL_WARNING_FORTE_DECEL <-> outer port SIGNALER_S2/rp_OPTION_ALL_WARNING_FORTE_DECEL
    delegate GID.rp_FONCTION_SFU_DANS_UCFREIN <-> outer port SIGNALER_S2/rp_FONCTION_SFU_DANS_UCFREIN
    delegate GID.rp_VITESSE_LONGITUDINALE <-> outer port SIGNALER_S2/rp_VITESSE_LONGITUDINALE
    delegate GID.rp_DMD_LOCAL_TELECMD <-> outer port SIGNALER_S2/rp_DMD_LOCAL_TELECMD
    delegate GID.rp_ETAT_CONDA <-> outer port SIGNALER_S2/rp_ETAT_CONDA
    delegate GID.rp_TYPE_CONDA <-> outer port SIGNALER_S2/rp_TYPE_CONDA
    delegate GID.rp_ETAT_COMMODO_CLIGNO <-> outer port SIGNALER_S2/rp_ETAT_COMMODO_CLIGNO
    delegate GID.rp_MODE_CONFIG_VHL <-> outer port SIGNALER_S2/rp_MODE_CONFIG_VHL
    connect GESD.pp_DEFAUT_CLIGNO_D -> GID.rp_DEFAUT_CLIGNO_D
    connect GESD.pp_DEFAUT_CLIGNO_G -> GID.rp_DEFAUT_CLIGNO_G
  internal behavior ib_GID_S2: component=GID_S2
    timing event evt_GID_S2: start-on-event=GID_S2, period=0.1
    runnable GID_S2
      5 x data read access:
        dra_DMD_ALL_CLIGNO_G: data-element=rp_DMD_ALL_CLIGNO_G.DMD_ALL_CLIGNO_G
        dra_FREQ_CLIGN: data-element=rp_FREQ_CLIGN.FREQ_CLIGN
        dra_RC_CLIGN: data-element=rp_RC_CLIGN.RC_CLIGN
        dra_DMD_ALL_CLIGNO_D: data-element=rp_DMD_ALL_CLIGNO_D.DMD_ALL_CLIGNO_D
        dra_DMD_CLIGNOTANT_SON: data-element=rp_DMD_CLIGNOTANT_SON.DMD_CLIGNOTANT_SON
      14 x data write access:
        dwa_PILOTAGE_CLIGNO_AVG: data-element=pp_PILOTAGE_CLIGNO_AVG.PILOTAGE_CLIGNO_AVG
        dwa_CMD_CLIGNO_ARG: data-element=pp_CMD_CLIGNO_ARG.CMD_CLIGNO_ARG
        dwa_P_TEM_SIGN_FX_CLIGNO_G: data-element=pp_P_TEM_SIGN_FX_CLIGNO_G.P_TEM_SIGN_FX_CLIGNO_G
        dwa_PILOTAGE_CLIGNO_AVD: data-element=pp_PILOTAGE_CLIGNO_AVD.PILOTAGE_CLIGNO_AVD
        dwa_CMD_CLIGNO_ARD: data-element=pp_CMD_CLIGNO_ARD.CMD_CLIGNO_ARD
        dwa_P_TEM_SIGN_FX_CLIGNO_D: data-element=pp_P_TEM_SIGN_FX_CLIGNO_D.P_TEM_SIGN_FX_CLIGNO_D
        dwa_P_SON_SIGN_FX_CLIGNO_CLIC: data-element=pp_P_SON_SIGN_FX_CLIGNO_CLIC.P_SON_SIGN_FX_CLIGNO_CLIC
        dwa_P_SON_SIGN_FX_CLIGNO_CLAC: data-element=pp_P_SON_SIGN_FX_CLIGNO_CLAC.P_SON_SIGN_FX_CLIGNO_CLAC
        dwa_P_SON_SIGN_FX_CLIGNO_CLIC__2: data-element=pp_P_SON_SIGN_FX_CLIGNO_CLIC_REL.P_SON_SIGN_FX_CLIGNO_CLIC_REL
        dwa_P_SON_SIGN_FX_CLIGNO_CLAC__2: data-element=pp_P_SON_SIGN_FX_CLIGNO_CLAC_REL.P_SON_SIGN_FX_CLIGNO_CLAC_REL
        dwa_P_SON_SIGN_FX_CLIGNO_CLIC__4: data-element=pp_P_SON_SIGN_FX_CLIGNO_CLIC_R.P_SON_SIGN_FX_CLIGNO_CLIC_R
        dwa_P_SON_SIGN_FX_CLIGNO_CLAC__4: data-element=pp_P_SON_SIGN_FX_CLIGNO_CLAC_R.P_SON_SIGN_FX_CLIGNO_CLAC_R
        dwa_P_SON_SIGN_FX_CLIGNO_CLIC_R: data-element=pp_P_SON_SIGN_FX_CLIGNO_CLIC_R_REL.P_SON_SIGN_FX_CLIGNO_CLIC_R_REL
        dwa_P_SON_SIGN_FX_CLIGNO_CLAC_R: data-element=pp_P_SON_SIGN_FX_CLIGNO_CLAC_R_REL.P_SON_SIGN_FX_CLIGNO_CLAC_R_REL
  19 x sender receiver interface:
    sri_DMD_ALL_CLIGNO_G
      data DMD_ALL_CLIGNO_G: type=AR_SIGNALER_SWC/Boolean
    sri_FREQ_CLIGN
      data FREQ_CLIGN: type=AR_SIGNALER_SWC/UInt16
    sri_RC_CLIGN
      data RC_CLIGN: type=AR_SIGNALER_SWC/UInt16
    sri_DMD_ALL_CLIGNO_D
      data DMD_ALL_CLIGNO_D: type=AR_SIGNALER_SWC/Boolean
    sri_DMD_CLIGNOTANT_SON
      data DMD_CLIGNOTANT_SON: type=AR_SIGNALER_SWC/Boolean
    sri_PILOTAGE_CLIGNO_AVG
      data PILOTAGE_CLIGNO_AVG: type=AR_SIGNALER_SWC/Boolean
    sri_CMD_CLIGNO_ARG
      data CMD_CLIGNO_ARG: type=AR_SIGNALER_SWC/Boolean
    sri_P_TEM_SIGN_FX_CLIGNO_G
      data P_TEM_SIGN_FX_CLIGNO_G: type=AR_SIGNALER_SWC/Boolean
    sri_PILOTAGE_CLIGNO_AVD
      data PILOTAGE_CLIGNO_AVD: type=AR_SIGNALER_SWC/Boolean
    sri_CMD_CLIGNO_ARD
      data CMD_CLIGNO_ARD: type=AR_SIGNALER_SWC/Boolean
    sri_P_TEM_SIGN_FX_CLIGNO_D
      data P_TEM_SIGN_FX_CLIGNO_D: type=AR_SIGNALER_SWC/Boolean
    sri_P_SON_SIGN_FX_CLIGNO_CLIC
      data P_SON_SIGN_FX_CLIGNO_CLIC: type=AR_SIGNALER_SWC/Boolean
    sri_P_SON_SIGN_FX_CLIGNO_CLAC
      data P_SON_SIGN_FX_CLIGNO_CLAC: type=AR_SIGNALER_SWC/Boolean
    sri_P_SON_SIGN_FX_CLIGNO_CLIC_REL
      data P_SON_SIGN_FX_CLIGNO_CLIC_REL: type=AR_SIGNALER_SWC/Boolean
    sri_P_SON_SIGN_FX_CLIGNO_CLAC_REL
      data P_SON_SIGN_FX_CLIGNO_CLAC_REL: type=AR_SIGNALER_SWC/Boolean
    sri_P_SON_SIGN_FX_CLIGNO_CLIC_R
      data P_SON_SIGN_FX_CLIGNO_CLIC_R: type=AR_SIGNALER_SWC/Boolean
    sri_P_SON_SIGN_FX_CLIGNO_CLAC_R
      data P_SON_SIGN_FX_CLIGNO_CLAC_R: type=AR_SIGNALER_SWC/Boolean
    sri_P_SON_SIGN_FX_CLIGNO_CLIC_R_REL
      data P_SON_SIGN_FX_CLIGNO_CLIC_R_REL: type=AR_SIGNALER_SWC/Boolean
    sri_P_SON_SIGN_FX_CLIGNO_CLAC_R_REL
      data P_SON_SIGN_FX_CLIGNO_CLAC_R_REL: type=AR_SIGNALER_SWC/Boolean
  swc implementation implem_GID_S2: programming-language=C, behavior=ib_GID_S2
    code-descriptors:
      code implem_GID_S2: type=SRC
        xfile GID_S2.c: url=Src_C/GID_S2.c
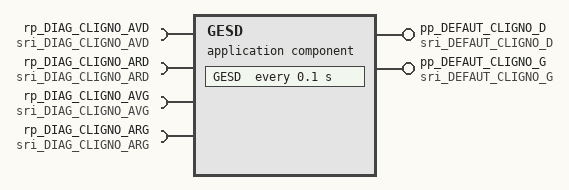
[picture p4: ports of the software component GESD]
  application software component type GESD
    4 x require port:
      rp_DIAG_CLIGNO_AVD: unqueued-receiver-com-spec{data-element=DIAG_CLIGNO_AVD, handle-invalid=KEEP, init-value=cst_UInt8_init/uint8_init, resync-time=0.0}, required-interface=sri_DIAG_CLIGNO_AVD
      rp_DIAG_CLIGNO_ARD: unqueued-receiver-com-spec{data-element=DIAG_CLIGNO_ARD, handle-invalid=KEEP, init-value=cst_UInt8_init/uint8_init, resync-time=0.0}, required-interface=sri_DIAG_CLIGNO_ARD
      rp_DIAG_CLIGNO_AVG: unqueued-receiver-com-spec{data-element=DIAG_CLIGNO_AVG, handle-invalid=KEEP, init-value=cst_UInt8_init/uint8_init, resync-time=0.0}, required-interface=sri_DIAG_CLIGNO_AVG
      rp_DIAG_CLIGNO_ARG: unqueued-receiver-com-spec{data-element=DIAG_CLIGNO_ARG, handle-invalid=KEEP, init-value=cst_UInt8_init/uint8_init, resync-time=0.0}, required-interface=sri_DIAG_CLIGNO_ARG
    provide port pp_DEFAUT_CLIGNO_D: unqueued-sender-com-spec{data-element=DEFAUT_CLIGNO_D, init-value=cst_Boolean_init/boolean_init}, provided-interface=sri_DEFAUT_CLIGNO_D
    provide port pp_DEFAUT_CLIGNO_G: unqueued-sender-com-spec{data-element=DEFAUT_CLIGNO_G, init-value=cst_Boolean_init/boolean_init}, provided-interface=sri_DEFAUT_CLIGNO_G
  internal behavior ib_GESD: component=GESD
    timing event evt_GESD: start-on-event=GESD, period=0.1
    runnable GESD
      4 x data read access:
        dra_DIAG_CLIGNO_AVD: data-element=rp_DIAG_CLIGNO_AVD.DIAG_CLIGNO_AVD
        dra_DIAG_CLIGNO_ARD: data-element=rp_DIAG_CLIGNO_ARD.DIAG_CLIGNO_ARD
        dra_DIAG_CLIGNO_AVG: data-element=rp_DIAG_CLIGNO_AVG.DIAG_CLIGNO_AVG
        dra_DIAG_CLIGNO_ARG: data-element=rp_DIAG_CLIGNO_ARG.DIAG_CLIGNO_ARG
      data write access dwa_DEFAUT_CLIGNO_D: data-element=pp_DEFAUT_CLIGNO_D.DEFAUT_CLIGNO_D
      data write access dwa_DEFAUT_CLIGNO_G: data-element=pp_DEFAUT_CLIGNO_G.DEFAUT_CLIGNO_G
  6 x sender receiver interface:
    sri_DIAG_CLIGNO_AVD
      data DIAG_CLIGNO_AVD: type=AR_SIGNALER_SWC/UInt8
    sri_DIAG_CLIGNO_ARD
      data DIAG_CLIGNO_ARD: type=AR_SIGNALER_SWC/UInt8
    sri_DIAG_CLIGNO_AVG
      data DIAG_CLIGNO_AVG: type=AR_SIGNALER_SWC/UInt8
    sri_DIAG_CLIGNO_ARG
      data DIAG_CLIGNO_ARG: type=AR_SIGNALER_SWC/UInt8
    sri_DEFAUT_CLIGNO_D
      data DEFAUT_CLIGNO_D: type=AR_SIGNALER_SWC/Boolean
    sri_DEFAUT_CLIGNO_G
      data DEFAUT_CLIGNO_G: type=AR_SIGNALER_SWC/Boolean
  swc implementation implem_GESD: programming-language=C, behavior=ib_GESD
    code-descriptors:
      code implem_GESD: type=SRC
        xfile GESD.c: url=Src_C/GESD.c
  sender receiver interface sri_P_LED_SIGN_PUSH_FEU_DET
    data P_LED_SIGN_PUSH_FEU_DET: type=AR_SIGNALER_SWC/Boolean
  sender receiver interface sri_APPUI_PEDALE_FREIN
    data APPUI_PEDALE_FREIN: type=AR_SIGNALER_SWC/Boolean
  sender receiver interface sri_DMD_FEUX_DETRESSE
    data DMD_FEUX_DETRESSE: type=AR_SIGNALER_SWC/Boolean
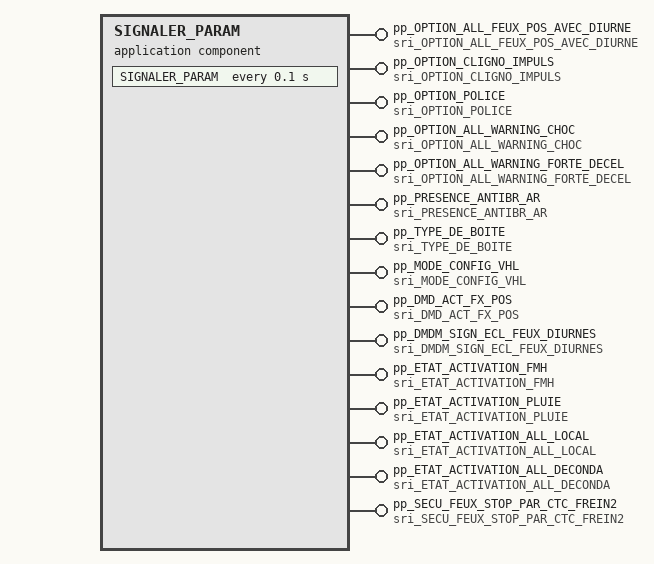
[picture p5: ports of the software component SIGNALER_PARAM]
  application software component type SIGNALER_PARAM
    15 x provide port:
      pp_OPTION_ALL_FEUX_POS_AVEC_DIURNE: unqueued-sender-com-spec{data-element=OPTION_ALL_FEUX_POS_AVEC_DIURNE, init-value=cst_Boolean_init/boolean_init}, provided-interface=sri_OPTION_ALL_FEUX_POS_AVEC_DIURNE
      pp_OPTION_CLIGNO_IMPULS: unqueued-sender-com-spec{data-element=OPTION_CLIGNO_IMPULS, init-value=cst_Boolean_init/boolean_init}, provided-interface=sri_OPTION_CLIGNO_IMPULS
      pp_OPTION_POLICE: unqueued-sender-com-spec{data-element=OPTION_POLICE, init-value=cst_Boolean_init/boolean_init}, provided-interface=sri_OPTION_POLICE
      pp_OPTION_ALL_WARNING_CHOC: unqueued-sender-com-spec{data-element=OPTION_ALL_WARNING_CHOC, init-value=cst_Boolean_init/boolean_init}, provided-interface=sri_OPTION_ALL_WARNING_CHOC
      pp_OPTION_ALL_WARNING_FORTE_DECEL: unqueued-sender-com-spec{data-element=OPTION_ALL_WARNING_FORTE_DECEL, init-value=cst_Boolean_init/boolean_init}, provided-interface=sri_OPTION_ALL_WARNING_FORTE_DECEL
      pp_PRESENCE_ANTIBR_AR: unqueued-sender-com-spec{data-element=PRESENCE_ANTIBR_AR, init-value=cst_Boolean_init/boolean_init}, provided-interface=sri_PRESENCE_ANTIBR_AR
      pp_TYPE_DE_BOITE: unqueued-sender-com-spec{data-element=TYPE_DE_BOITE, init-value=cst_UInt8_init/uint8_init}, provided-interface=sri_TYPE_DE_BOITE
      pp_MODE_CONFIG_VHL: unqueued-sender-com-spec{data-element=MODE_CONFIG_VHL, init-value=cst_UInt8_init/uint8_init}, provided-interface=sri_MODE_CONFIG_VHL
      pp_DMD_ACT_FX_POS: unqueued-sender-com-spec{data-element=DMD_ACT_FX_POS, init-value=cst_Boolean_init/boolean_init}, provided-interface=sri_DMD_ACT_FX_POS
      pp_DMDM_SIGN_ECL_FEUX_DIURNES: unqueued-sender-com-spec{data-element=DMDM_SIGN_ECL_FEUX_DIURNES, init-value=cst_Boolean_init/boolean_init}, provided-interface=sri_DMDM_SIGN_ECL_FEUX_DIURNES
      pp_ETAT_ACTIVATION_FMH: unqueued-sender-com-spec{data-element=ETAT_ACTIVATION_FMH, init-value=cst_Boolean_init/boolean_init}, provided-interface=sri_ETAT_ACTIVATION_FMH
      pp_ETAT_ACTIVATION_PLUIE: unqueued-sender-com-spec{data-element=ETAT_ACTIVATION_PLUIE, init-value=cst_Boolean_init/boolean_init}, provided-interface=sri_ETAT_ACTIVATION_PLUIE
      pp_ETAT_ACTIVATION_ALL_LOCAL: unqueued-sender-com-spec{data-element=ETAT_ACTIVATION_ALL_LOCAL, init-value=cst_Boolean_init/boolean_init}, provided-interface=sri_ETAT_ACTIVATION_ALL_LOCAL
      pp_ETAT_ACTIVATION_ALL_DECONDA: unqueued-sender-com-spec{data-element=ETAT_ACTIVATION_ALL_DECONDA, init-value=cst_Boolean_init/boolean_init}, provided-interface=sri_ETAT_ACTIVATION_ALL_DECONDA
      pp_SECU_FEUX_STOP_PAR_CTC_FREIN2: unqueued-sender-com-spec{data-element=SECU_FEUX_STOP_PAR_CTC_FREIN2, init-value=cst_Boolean_init/boolean_init}, provided-interface=sri_SECU_FEUX_STOP_PAR_CTC_FREIN2
  internal behavior ib_SIGNALER_PARAM: component=SIGNALER_PARAM
    timing event evt_SIGNALER_PARAM: start-on-event=SIGNALER_PARAM, period=0.1
    runnable SIGNALER_PARAM
      15 x data write access:
        dwa_OPTION_ALL_FEUX_POS_AVEC_DI: data-element=pp_OPTION_ALL_FEUX_POS_AVEC_DIURNE.OPTION_ALL_FEUX_POS_AVEC_DIURNE
        dwa_OPTION_CLIGNO_IMPULS: data-element=pp_OPTION_CLIGNO_IMPULS.OPTION_CLIGNO_IMPULS
        dwa_OPTION_POLICE: data-element=pp_OPTION_POLICE.OPTION_POLICE
        dwa_OPTION_ALL_WARNING_CHOC: data-element=pp_OPTION_ALL_WARNING_CHOC.OPTION_ALL_WARNING_CHOC
        dwa_OPTION_ALL_WARNING_FORTE_DE: data-element=pp_OPTION_ALL_WARNING_FORTE_DECEL.OPTION_ALL_WARNING_FORTE_DECEL
        dwa_PRESENCE_ANTIBR_AR: data-element=pp_PRESENCE_ANTIBR_AR.PRESENCE_ANTIBR_AR
        dwa_TYPE_DE_BOITE: data-element=pp_TYPE_DE_BOITE.TYPE_DE_BOITE
        dwa_MODE_CONFIG_VHL: data-element=pp_MODE_CONFIG_VHL.MODE_CONFIG_VHL
        dwa_DMD_ACT_FX_POS: data-element=pp_DMD_ACT_FX_POS.DMD_ACT_FX_POS
        dwa_DMDM_SIGN_ECL_FEUX_DIURNES: data-element=pp_DMDM_SIGN_ECL_FEUX_DIURNES.DMDM_SIGN_ECL_FEUX_DIURNES
        dwa_ETAT_ACTIVATION_FMH: data-element=pp_ETAT_ACTIVATION_FMH.ETAT_ACTIVATION_FMH
        dwa_ETAT_ACTIVATION_PLUIE: data-element=pp_ETAT_ACTIVATION_PLUIE.ETAT_ACTIVATION_PLUIE
        dwa_ETAT_ACTIVATION_ALL_LOCAL: data-element=pp_ETAT_ACTIVATION_ALL_LOCAL.ETAT_ACTIVATION_ALL_LOCAL
        dwa_ETAT_ACTIVATION_ALL_DECONDA: data-element=pp_ETAT_ACTIVATION_ALL_DECONDA.ETAT_ACTIVATION_ALL_DECONDA
        dwa_SECU_FEUX_STOP_PAR_CTC_FREI: data-element=pp_SECU_FEUX_STOP_PAR_CTC_FREIN2.SECU_FEUX_STOP_PAR_CTC_FREIN2
  12 x sender receiver interface:
    sri_OPTION_CLIGNO_IMPULS
      data OPTION_CLIGNO_IMPULS: type=AR_SIGNALER_SWC/Boolean
    sri_OPTION_POLICE
      data OPTION_POLICE: type=AR_SIGNALER_SWC/Boolean
    sri_OPTION_ALL_WARNING_CHOC
      data OPTION_ALL_WARNING_CHOC: type=AR_SIGNALER_SWC/Boolean
    sri_OPTION_ALL_WARNING_FORTE_DECEL
      data OPTION_ALL_WARNING_FORTE_DECEL: type=AR_SIGNALER_SWC/Boolean
    sri_PRESENCE_ANTIBR_AR
      data PRESENCE_ANTIBR_AR: type=AR_SIGNALER_SWC/Boolean
    sri_TYPE_DE_BOITE
      data TYPE_DE_BOITE: type=AR_SIGNALER_SWC/UInt8
    sri_MODE_CONFIG_VHL
      data MODE_CONFIG_VHL: type=AR_SIGNALER_SWC/UInt8
    sri_ETAT_ACTIVATION_FMH
      data ETAT_ACTIVATION_FMH: type=AR_SIGNALER_SWC/Boolean
    sri_ETAT_ACTIVATION_PLUIE
      data ETAT_ACTIVATION_PLUIE: type=AR_SIGNALER_SWC/Boolean
    sri_ETAT_ACTIVATION_ALL_LOCAL
      data ETAT_ACTIVATION_ALL_LOCAL: type=AR_SIGNALER_SWC/Boolean
    sri_ETAT_ACTIVATION_ALL_DECONDA
      data ETAT_ACTIVATION_ALL_DECONDA: type=AR_SIGNALER_SWC/Boolean
    sri_SECU_FEUX_STOP_PAR_CTC_FREIN2
      data SECU_FEUX_STOP_PAR_CTC_FREIN2: type=AR_SIGNALER_SWC/Boolean
  swc implementation implem_SIGNALER_PARAM: programming-language=C, behavior=ib_SIGNALER_PARAM
    code-descriptors:
      code implem_SIGNALER_PARAM: type=SRC
        xfile SIGNALER_PARAM.c: url=Src_C/SIGNALER_PARAM.c
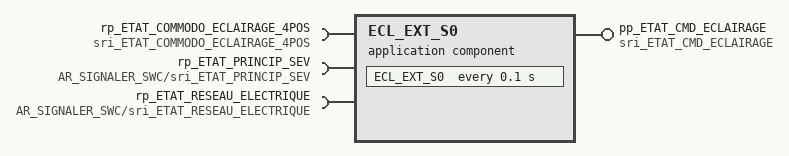
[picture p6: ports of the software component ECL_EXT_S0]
  application software component type ECL_EXT_S0
    require port rp_ETAT_COMMODO_ECLAIRAGE_4POS: unqueued-receiver-com-spec{data-element=ETAT_COMMODO_ECLAIRAGE_4POS, handle-invalid=KEEP, init-value=cst_UInt8_init/uint8_init, resync-time=0.0}, required-interface=sri_ETAT_COMMODO_ECLAIRAGE_4POS
    require port rp_ETAT_PRINCIP_SEV: unqueued-receiver-com-spec{data-element=sri_ETAT_PRINCIP_SEV/ETAT_PRINCIP_SEV, handle-invalid=KEEP, init-value=cst_UInt8_init/uint8_init, resync-time=0.0}, required-interface=AR_SIGNALER_SWC/sri_ETAT_PRINCIP_SEV
    require port rp_ETAT_RESEAU_ELECTRIQUE: unqueued-receiver-com-spec{data-element=sri_ETAT_RESEAU_ELECTRIQUE/ETAT_RESEAU_ELECTRIQUE, handle-invalid=KEEP, init-value=cst_UInt8_init/uint8_init, resync-time=0.0}, required-interface=AR_SIGNALER_SWC/sri_ETAT_RESEAU_ELECTRIQUE
    provide port pp_ETAT_CMD_ECLAIRAGE: unqueued-sender-com-spec{data-element=ETAT_CMD_ECLAIRAGE, init-value=cst_UInt8_init/uint8_init}, provided-interface=sri_ETAT_CMD_ECLAIRAGE
  internal behavior ib_ECL_EXT_S0: component=ECL_EXT_S0
    timing event evt_ECL_EXT_S0: start-on-event=ECL_EXT_S0, period=0.1
    runnable ECL_EXT_S0
      data read access dra_ETAT_COMMODO_ECLAIRAGE_4POS: data-element=rp_ETAT_COMMODO_ECLAIRAGE_4POS.ETAT_COMMODO_ECLAIRAGE_4POS
      data read access dra_ETAT_PRINCIP_SEV: data-element=rp_ETAT_PRINCIP_SEV.ETAT_PRINCIP_SEV
      data read access dra_ETAT_RESEAU_ELECTRIQUE: data-element=rp_ETAT_RESEAU_ELECTRIQUE.ETAT_RESEAU_ELECTRIQUE
      data write access dwa_ETAT_CMD_ECLAIRAGE: data-element=pp_ETAT_CMD_ECLAIRAGE.ETAT_CMD_ECLAIRAGE
  sender receiver interface sri_ETAT_COMMODO_ECLAIRAGE_4POS
    data ETAT_COMMODO_ECLAIRAGE_4POS: type=AR_SIGNALER_SWC/UInt8
  swc implementation implem_ECL_EXT_S0: programming-language=C, behavior=ib_ECL_EXT_S0
    code-descriptors:
      code implem_ECL_EXT_S0: type=SRC
        xfile ECL_EXT_S0.c: url=Src_C/ECL_EXT_S0.c
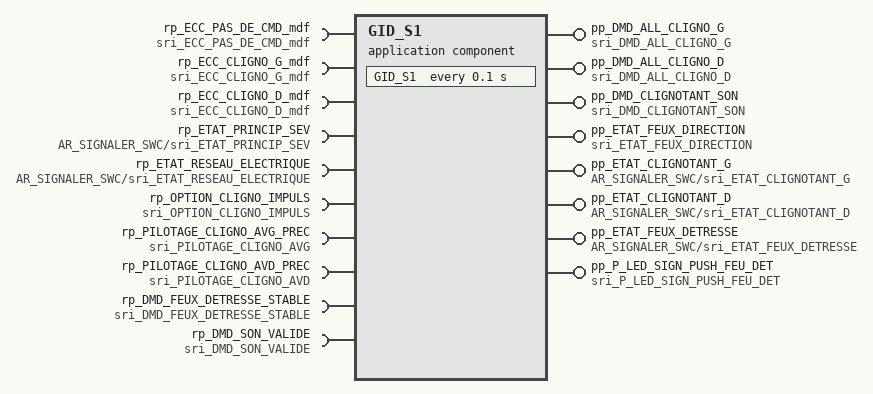
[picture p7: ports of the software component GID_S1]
  application software component type GID_S1
    10 x require port:
      rp_ECC_PAS_DE_CMD_mdf: unqueued-receiver-com-spec{data-element=ECC_PAS_DE_CMD_mdf, handle-invalid=KEEP, init-value=cst_Boolean_init/boolean_init, resync-time=0.0}, required-interface=sri_ECC_PAS_DE_CMD_mdf
      rp_ECC_CLIGNO_G_mdf: unqueued-receiver-com-spec{data-element=ECC_CLIGNO_G_mdf, handle-invalid=KEEP, init-value=cst_Boolean_init/boolean_init, resync-time=0.0}, required-interface=sri_ECC_CLIGNO_G_mdf
      rp_ECC_CLIGNO_D_mdf: unqueued-receiver-com-spec{data-element=ECC_CLIGNO_D_mdf, handle-invalid=KEEP, init-value=cst_Boolean_init/boolean_init, resync-time=0.0}, required-interface=sri_ECC_CLIGNO_D_mdf
      rp_ETAT_PRINCIP_SEV: unqueued-receiver-com-spec{data-element=sri_ETAT_PRINCIP_SEV/ETAT_PRINCIP_SEV, handle-invalid=KEEP, init-value=cst_UInt8_init/uint8_init, resync-time=0.0}, required-interface=AR_SIGNALER_SWC/sri_ETAT_PRINCIP_SEV
      rp_ETAT_RESEAU_ELECTRIQUE: unqueued-receiver-com-spec{data-element=sri_ETAT_RESEAU_ELECTRIQUE/ETAT_RESEAU_ELECTRIQUE, handle-invalid=KEEP, init-value=cst_UInt8_init/uint8_init, resync-time=0.0}, required-interface=AR_SIGNALER_SWC/sri_ETAT_RESEAU_ELECTRIQUE
      rp_OPTION_CLIGNO_IMPULS: unqueued-receiver-com-spec{data-element=OPTION_CLIGNO_IMPULS, handle-invalid=KEEP, init-value=cst_Boolean_init/boolean_init, resync-time=0.0}, required-interface=sri_OPTION_CLIGNO_IMPULS
      rp_PILOTAGE_CLIGNO_AVG_PREC: unqueued-receiver-com-spec{data-element=PILOTAGE_CLIGNO_AVG, handle-invalid=KEEP, init-value=cst_Boolean_init/boolean_init, resync-time=0.0}, required-interface=sri_PILOTAGE_CLIGNO_AVG
      rp_PILOTAGE_CLIGNO_AVD_PREC: unqueued-receiver-com-spec{data-element=PILOTAGE_CLIGNO_AVD, handle-invalid=KEEP, init-value=cst_Boolean_init/boolean_init, resync-time=0.0}, required-interface=sri_PILOTAGE_CLIGNO_AVD
      rp_DMD_FEUX_DETRESSE_STABLE: unqueued-receiver-com-spec{data-element=DMD_FEUX_DETRESSE_STABLE, handle-invalid=KEEP, init-value=cst_Boolean_init/boolean_init, resync-time=0.0}, required-interface=sri_DMD_FEUX_DETRESSE_STABLE
      rp_DMD_SON_VALIDE: unqueued-receiver-com-spec{data-element=DMD_SON_VALIDE, handle-invalid=KEEP, init-value=cst_Boolean_init/boolean_init, resync-time=0.0}, required-interface=sri_DMD_SON_VALIDE
    8 x provide port:
      pp_DMD_ALL_CLIGNO_G: unqueued-sender-com-spec{data-element=DMD_ALL_CLIGNO_G, init-value=cst_Boolean_init/boolean_init}, provided-interface=sri_DMD_ALL_CLIGNO_G
      pp_DMD_ALL_CLIGNO_D: unqueued-sender-com-spec{data-element=DMD_ALL_CLIGNO_D, init-value=cst_Boolean_init/boolean_init}, provided-interface=sri_DMD_ALL_CLIGNO_D
      pp_DMD_CLIGNOTANT_SON: unqueued-sender-com-spec{data-element=DMD_CLIGNOTANT_SON, init-value=cst_Boolean_init/boolean_init}, provided-interface=sri_DMD_CLIGNOTANT_SON
      pp_ETAT_FEUX_DIRECTION: unqueued-sender-com-spec{data-element=ETAT_FEUX_DIRECTION, init-value=cst_UInt8_init/uint8_init}, provided-interface=sri_ETAT_FEUX_DIRECTION
      pp_ETAT_CLIGNOTANT_G: unqueued-sender-com-spec{data-element=sri_ETAT_CLIGNOTANT_G/ETAT_CLIGNOTANT_G, init-value=cst_Boolean_init/boolean_init}, provided-interface=AR_SIGNALER_SWC/sri_ETAT_CLIGNOTANT_G
      pp_ETAT_CLIGNOTANT_D: unqueued-sender-com-spec{data-element=sri_ETAT_CLIGNOTANT_D/ETAT_CLIGNOTANT_D, init-value=cst_Boolean_init/boolean_init}, provided-interface=AR_SIGNALER_SWC/sri_ETAT_CLIGNOTANT_D
      pp_ETAT_FEUX_DETRESSE: unqueued-sender-com-spec{data-element=sri_ETAT_FEUX_DETRESSE/ETAT_FEUX_DETRESSE, init-value=cst_Boolean_init/boolean_init}, provided-interface=AR_SIGNALER_SWC/sri_ETAT_FEUX_DETRESSE
      pp_P_LED_SIGN_PUSH_FEU_DET: unqueued-sender-com-spec{data-element=P_LED_SIGN_PUSH_FEU_DET, init-value=cst_Boolean_init/boolean_init}, provided-interface=sri_P_LED_SIGN_PUSH_FEU_DET
  internal behavior ib_GID_S1: component=GID_S1
    timing event evt_GID_S1: start-on-event=GID_S1, period=0.1
    runnable GID_S1
      10 x data read access:
        dra_ECC_PAS_DE_CMD_mdf: data-element=rp_ECC_PAS_DE_CMD_mdf.ECC_PAS_DE_CMD_mdf
        dra_ECC_CLIGNO_G_mdf: data-element=rp_ECC_CLIGNO_G_mdf.ECC_CLIGNO_G_mdf
        dra_ECC_CLIGNO_D_mdf: data-element=rp_ECC_CLIGNO_D_mdf.ECC_CLIGNO_D_mdf
        dra_ETAT_PRINCIP_SEV: data-element=rp_ETAT_PRINCIP_SEV.ETAT_PRINCIP_SEV
        dra_ETAT_RESEAU_ELECTRIQUE: data-element=rp_ETAT_RESEAU_ELECTRIQUE.ETAT_RESEAU_ELECTRIQUE
        dra_OPTION_CLIGNO_IMPULS: data-element=rp_OPTION_CLIGNO_IMPULS.OPTION_CLIGNO_IMPULS
        dra_PILOTAGE_CLIGNO_AVG: data-element=rp_PILOTAGE_CLIGNO_AVG_PREC.PILOTAGE_CLIGNO_AVG
        dra_PILOTAGE_CLIGNO_AVD: data-element=rp_PILOTAGE_CLIGNO_AVD_PREC.PILOTAGE_CLIGNO_AVD
        dra_DMD_FEUX_DETRESSE_STABLE: data-element=rp_DMD_FEUX_DETRESSE_STABLE.DMD_FEUX_DETRESSE_STABLE
        dra_DMD_SON_VALIDE: data-element=rp_DMD_SON_VALIDE.DMD_SON_VALIDE
      8 x data write access:
        dwa_DMD_ALL_CLIGNO_G: data-element=pp_DMD_ALL_CLIGNO_G.DMD_ALL_CLIGNO_G
        dwa_DMD_ALL_CLIGNO_D: data-element=pp_DMD_ALL_CLIGNO_D.DMD_ALL_CLIGNO_D
        dwa_DMD_CLIGNOTANT_SON: data-element=pp_DMD_CLIGNOTANT_SON.DMD_CLIGNOTANT_SON
        dwa_ETAT_FEUX_DIRECTION: data-element=pp_ETAT_FEUX_DIRECTION.ETAT_FEUX_DIRECTION
        dwa_ETAT_CLIGNOTANT_G: data-element=pp_ETAT_CLIGNOTANT_G.ETAT_CLIGNOTANT_G
        dwa_ETAT_CLIGNOTANT_D: data-element=pp_ETAT_CLIGNOTANT_D.ETAT_CLIGNOTANT_D
        dwa_ETAT_FEUX_DETRESSE: data-element=pp_ETAT_FEUX_DETRESSE.ETAT_FEUX_DETRESSE
        dwa_P_LED_SIGN_PUSH_FEU_DET: data-element=pp_P_LED_SIGN_PUSH_FEU_DET.P_LED_SIGN_PUSH_FEU_DET
  9 x sender receiver interface:
    sri_ECC_PAS_DE_CMD_mdf
      data ECC_PAS_DE_CMD_mdf: type=AR_SIGNALER_SWC/Boolean
    sri_ECC_CLIGNO_G_mdf
      data ECC_CLIGNO_G_mdf: type=AR_SIGNALER_SWC/Boolean
    sri_ECC_CLIGNO_D_mdf
      data ECC_CLIGNO_D_mdf: type=AR_SIGNALER_SWC/Boolean
    sri_DMD_FEUX_DETRESSE_STABLE
      data DMD_FEUX_DETRESSE_STABLE: type=AR_SIGNALER_SWC/Boolean
    sri_DMD_SON_VALIDE
      data DMD_SON_VALIDE: type=AR_SIGNALER_SWC/Boolean
    sri_ETAT_FEUX_DIRECTION
      data ETAT_FEUX_DIRECTION: type=AR_SIGNALER_SWC/UInt8
    sri_ETAT_CLIGNOTANT_G
      data ETAT_CLIGNOTANT_G: type=AR_SIGNALER_SWC/Boolean
    sri_ETAT_CLIGNOTANT_D
      data ETAT_CLIGNOTANT_D: type=AR_SIGNALER_SWC/Boolean
    sri_ETAT_FEUX_DETRESSE
      data ETAT_FEUX_DETRESSE: type=AR_SIGNALER_SWC/Boolean
  swc implementation implem_GID_S1: programming-language=C, behavior=ib_GID_S1
    code-descriptors:
      code implem_GID_S1: type=SRC
        xfile GID_S1.c: url=Src_C/GID_S1.c
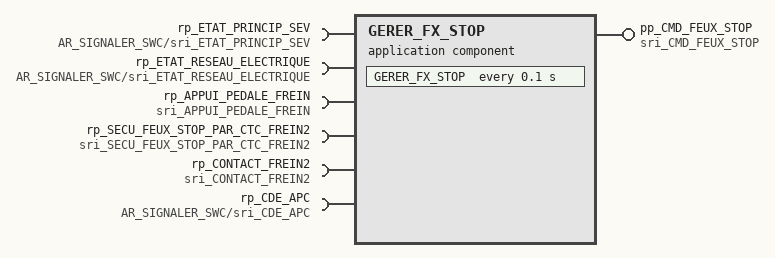
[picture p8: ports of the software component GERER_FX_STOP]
  application software component type GERER_FX_STOP
    6 x require port:
      rp_ETAT_PRINCIP_SEV: unqueued-receiver-com-spec{data-element=sri_ETAT_PRINCIP_SEV/ETAT_PRINCIP_SEV, handle-invalid=KEEP, init-value=cst_UInt8_init/uint8_init, resync-time=0.0}, required-interface=AR_SIGNALER_SWC/sri_ETAT_PRINCIP_SEV
      rp_ETAT_RESEAU_ELECTRIQUE: unqueued-receiver-com-spec{data-element=sri_ETAT_RESEAU_ELECTRIQUE/ETAT_RESEAU_ELECTRIQUE, handle-invalid=KEEP, init-value=cst_UInt8_init/uint8_init, resync-time=0.0}, required-interface=AR_SIGNALER_SWC/sri_ETAT_RESEAU_ELECTRIQUE
      rp_APPUI_PEDALE_FREIN: unqueued-receiver-com-spec{data-element=APPUI_PEDALE_FREIN, handle-invalid=KEEP, init-value=cst_Boolean_init/boolean_init, resync-time=0.0}, required-interface=sri_APPUI_PEDALE_FREIN
      rp_SECU_FEUX_STOP_PAR_CTC_FREIN2: unqueued-receiver-com-spec{data-element=SECU_FEUX_STOP_PAR_CTC_FREIN2, handle-invalid=KEEP, init-value=cst_Boolean_init/boolean_init, resync-time=0.0}, required-interface=sri_SECU_FEUX_STOP_PAR_CTC_FREIN2
      rp_CONTACT_FREIN2: unqueued-receiver-com-spec{data-element=CONTACT_FREIN2, handle-invalid=KEEP, init-value=cst_Boolean_init/boolean_init, resync-time=0.0}, required-interface=sri_CONTACT_FREIN2
      rp_CDE_APC: unqueued-receiver-com-spec{data-element=sri_CDE_APC/CDE_APC, handle-invalid=KEEP, init-value=cst_Boolean_init/boolean_init, resync-time=0.0}, required-interface=AR_SIGNALER_SWC/sri_CDE_APC
    provide port pp_CMD_FEUX_STOP: unqueued-sender-com-spec{data-element=CMD_FEUX_STOP, init-value=cst_Boolean_init/boolean_init}, provided-interface=sri_CMD_FEUX_STOP
  internal behavior ib_GERER_FX_STOP: component=GERER_FX_STOP
    timing event evt_GERER_FX_STOP: start-on-event=GERER_FX_STOP, period=0.1
    runnable GERER_FX_STOP
      6 x data read access:
        dra_ETAT_PRINCIP_SEV: data-element=rp_ETAT_PRINCIP_SEV.ETAT_PRINCIP_SEV
        dra_ETAT_RESEAU_ELECTRIQUE: data-element=rp_ETAT_RESEAU_ELECTRIQUE.ETAT_RESEAU_ELECTRIQUE
        dra_APPUI_PEDALE_FREIN: data-element=rp_APPUI_PEDALE_FREIN.APPUI_PEDALE_FREIN
        dra_SECU_FEUX_STOP_PAR_CTC_FREI: data-element=rp_SECU_FEUX_STOP_PAR_CTC_FREIN2.SECU_FEUX_STOP_PAR_CTC_FREIN2
        dra_CONTACT_FREIN2: data-element=rp_CONTACT_FREIN2.CONTACT_FREIN2
        dra_CDE_APC: data-element=rp_CDE_APC.CDE_APC
      data write access dwa_CMD_FEUX_STOP: data-element=pp_CMD_FEUX_STOP.CMD_FEUX_STOP
  sender receiver interface sri_CONTACT_FREIN2
    data CONTACT_FREIN2: type=AR_SIGNALER_SWC/Boolean
  sender receiver interface sri_CDE_APC
    data CDE_APC: type=AR_SIGNALER_SWC/Boolean
  sender receiver interface sri_CMD_FEUX_STOP
    data CMD_FEUX_STOP: type=AR_SIGNALER_SWC/Boolean
  swc implementation implem_GERER_FX_STOP: programming-language=C, behavior=ib_GERER_FX_STOP
    code-descriptors:
      code implem_GERER_FX_STOP: type=SRC
        xfile GERER_FX_STOP.c: url=Src_C/GERER_FX_STOP.c
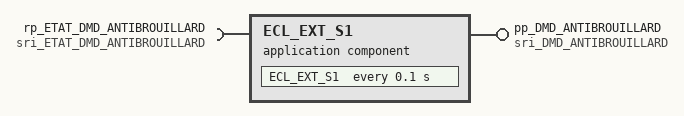
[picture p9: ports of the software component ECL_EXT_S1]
  application software component type ECL_EXT_S1
    require port rp_ETAT_DMD_ANTIBROUILLARD: unqueued-receiver-com-spec{data-element=ETAT_DMD_ANTIBROUILLARD, handle-invalid=KEEP, init-value=cst_UInt8_init/uint8_init, resync-time=0.0}, required-interface=sri_ETAT_DMD_ANTIBROUILLARD
    provide port pp_DMD_ANTIBROUILLARD: unqueued-sender-com-spec{data-element=DMD_ANTIBROUILLARD, init-value=cst_UInt8_init/uint8_init}, provided-interface=sri_DMD_ANTIBROUILLARD
  internal behavior ib_ECL_EXT_S1: component=ECL_EXT_S1
    timing event evt_ECL_EXT_S1: start-on-event=ECL_EXT_S1, period=0.1
    runnable ECL_EXT_S1
      data read access dra_ETAT_DMD_ANTIBROUILLARD: data-element=rp_ETAT_DMD_ANTIBROUILLARD.ETAT_DMD_ANTIBROUILLARD
      data write access dwa_DMD_ANTIBROUILLARD: data-element=pp_DMD_ANTIBROUILLARD.DMD_ANTIBROUILLARD
  sender receiver interface sri_ETAT_DMD_ANTIBROUILLARD
    data ETAT_DMD_ANTIBROUILLARD: type=AR_SIGNALER_SWC/UInt8
  sender receiver interface sri_DMD_ANTIBROUILLARD
    data DMD_ANTIBROUILLARD: type=AR_SIGNALER_SWC/UInt8
  swc implementation implem_ECL_EXT_S1: programming-language=C, behavior=ib_ECL_EXT_S1
    code-descriptors:
      code implem_ECL_EXT_S1: type=SRC
        xfile ECL_EXT_S1.c: url=Src_C/ECL_EXT_S1.c
  application software component type GERER_FX_MA
    4 x require port:
      rp_ETAT_PRINCIP_SEV: unqueued-receiver-com-spec{data-element=sri_ETAT_PRINCIP_SEV/ETAT_PRINCIP_SEV, handle-invalid=KEEP, init-value=cst_UInt8_init/uint8_init, resync-time=0.0}, required-interface=AR_SIGNALER_SWC/sri_ETAT_PRINCIP_SEV
      rp_ETAT_RESEAU_ELECTRIQUE: unqueued-receiver-com-spec{data-element=sri_ETAT_RESEAU_ELECTRIQUE/ETAT_RESEAU_ELECTRIQUE, handle-invalid=KEEP, init-value=cst_UInt8_init/uint8_init, resync-time=0.0}, required-interface=AR_SIGNALER_SWC/sri_ETAT_RESEAU_ELECTRIQUE
      rp_TYPE_DE_BOITE: unqueued-receiver-com-spec{data-element=TYPE_DE_BOITE, handle-invalid=KEEP, init-value=cst_UInt8_init/uint8_init, resync-time=0.0}, required-interface=sri_TYPE_DE_BOITE
      rp_ETAT_MA: unqueued-receiver-com-spec{data-element=ETAT_MA, handle-invalid=KEEP, init-value=cst_Boolean_init/boolean_init, resync-time=0.0}, required-interface=sri_ETAT_MA
    provide port pp_CMD_FEUX_MAR: unqueued-sender-com-spec{data-element=CMD_FEUX_MAR, init-value=cst_Boolean_init/boolean_init}, provided-interface=sri_CMD_FEUX_MAR
  internal behavior ib_GERER_FX_MA: component=GERER_FX_MA
    timing event evt_GERER_FX_MA: start-on-event=GERER_FX_MA, period=0.1
    runnable GERER_FX_MA
      4 x data read access:
        dra_ETAT_PRINCIP_SEV: data-element=rp_ETAT_PRINCIP_SEV.ETAT_PRINCIP_SEV
        dra_ETAT_RESEAU_ELECTRIQUE: data-element=rp_ETAT_RESEAU_ELECTRIQUE.ETAT_RESEAU_ELECTRIQUE
        dra_TYPE_DE_BOITE: data-element=rp_TYPE_DE_BOITE.TYPE_DE_BOITE
        dra_ETAT_MA: data-element=rp_ETAT_MA.ETAT_MA
      data write access dwa_CMD_FEUX_MAR: data-element=pp_CMD_FEUX_MAR.CMD_FEUX_MAR
  sender receiver interface sri_ETAT_MA
    data ETAT_MA: type=AR_SIGNALER_SWC/Boolean
  sender receiver interface sri_CMD_FEUX_MAR
    data CMD_FEUX_MAR: type=AR_SIGNALER_SWC/Boolean
  swc implementation implem_GERER_FX_MA: programming-language=C, behavior=ib_GERER_FX_MA
    code-descriptors:
      code implem_GERER_FX_MA: type=SRC
        xfile GERER_FX_MA.c: url=Src_C/GERER_FX_MA.c
  application software component type GERER_ETAT_JOUR_NUIT
    6 x require port:
      rp_ETAT_FEUX_POSITION: unqueued-receiver-com-spec{data-element=sri_ETAT_FEUX_POSITION/ETAT_FEUX_POSITION, handle-invalid=KEEP, init-value=cst_Boolean_init/boolean_init, resync-time=0.0}, required-interface=AR_SIGNALER_SWC/sri_ETAT_FEUX_POSITION
      rp_ETAT_FEUX_DIURNES: unqueued-receiver-com-spec{data-element=sri_ETAT_FEUX_DIURNES/ETAT_FEUX_DIURNES, handle-invalid=KEEP, init-value=cst_Boolean_init/boolean_init, resync-time=0.0}, required-interface=AR_SIGNALER_SWC/sri_ETAT_FEUX_DIURNES
      rp_ETAT_ACTIVATION_FMH: unqueued-receiver-com-spec{data-element=ETAT_ACTIVATION_FMH, handle-invalid=KEEP, init-value=cst_Boolean_init/boolean_init, resync-time=0.0}, required-interface=sri_ETAT_ACTIVATION_FMH
      rp_ETAT_ACTIVATION_PLUIE: unqueued-receiver-com-spec{data-element=ETAT_ACTIVATION_PLUIE, handle-invalid=KEEP, init-value=cst_Boolean_init/boolean_init, resync-time=0.0}, required-interface=sri_ETAT_ACTIVATION_PLUIE
      rp_ETAT_ACTIVATION_ALL_LOCAL: unqueued-receiver-com-spec{data-element=ETAT_ACTIVATION_ALL_LOCAL, handle-invalid=KEEP, init-value=cst_Boolean_init/boolean_init, resync-time=0.0}, required-interface=sri_ETAT_ACTIVATION_ALL_LOCAL
      rp_ETAT_ACTIVATION_ALL_DECONDA: unqueued-receiver-com-spec{data-element=ETAT_ACTIVATION_ALL_DECONDA, handle-invalid=KEEP, init-value=cst_Boolean_init/boolean_init, resync-time=0.0}, required-interface=sri_ETAT_ACTIVATION_ALL_DECONDA
    provide port pp_ETAT_JOUR_NUIT: unqueued-sender-com-spec{data-element=ETAT_JOUR_NUIT, init-value=cst_Boolean_init/boolean_init}, provided-interface=sri_ETAT_JOUR_NUIT
  internal behavior ib_GERER_ETAT_JOUR_NUIT: component=GERER_ETAT_JOUR_NUIT
    timing event evt_GERER_ETAT_JOUR_NUIT: start-on-event=GERER_ETAT_JOUR_NUIT, period=0.1
    runnable GERER_ETAT_JOUR_NUIT
      6 x data read access:
        dra_ETAT_FEUX_POSITION: data-element=rp_ETAT_FEUX_POSITION.ETAT_FEUX_POSITION
        dra_ETAT_FEUX_DIURNES: data-element=rp_ETAT_FEUX_DIURNES.ETAT_FEUX_DIURNES
        dra_ETAT_ACTIVATION_FMH: data-element=rp_ETAT_ACTIVATION_FMH.ETAT_ACTIVATION_FMH
        dra_ETAT_ACTIVATION_PLUIE: data-element=rp_ETAT_ACTIVATION_PLUIE.ETAT_ACTIVATION_PLUIE
        dra_ETAT_ACTIVATION_ALL_LOCAL: data-element=rp_ETAT_ACTIVATION_ALL_LOCAL.ETAT_ACTIVATION_ALL_LOCAL
        dra_ETAT_ACTIVATION_ALL_DECONDA: data-element=rp_ETAT_ACTIVATION_ALL_DECONDA.ETAT_ACTIVATION_ALL_DECONDA
      data write access dwa_ETAT_JOUR_NUIT: data-element=pp_ETAT_JOUR_NUIT.ETAT_JOUR_NUIT
  sender receiver interface sri_ETAT_JOUR_NUIT
    data ETAT_JOUR_NUIT: type=AR_SIGNALER_SWC/Boolean
  swc implementation implem_GERER_ETAT_JOUR_NUIT: programming-language=C, behavior=ib_GERER_ETAT_JOUR_NUIT
    code-descriptors:
      code implem_GERER_ETAT_JOUR_NUIT: type=SRC
        xfile GERER_ETAT_JOUR_NUIT.c: url=Src_C/GERER_ETAT_JOUR_NUIT.c
  application software component type GID_S0
    21 x require port:
      rp_ETAT_CONDA: unqueued-receiver-com-spec{data-element=sri_ETAT_CONDA/ETAT_CONDA, handle-invalid=KEEP, init-value=cst_UInt8_init/uint8_init, resync-time=0.0}, required-interface=AR_SIGNALER_SWC/sri_ETAT_CONDA
      rp_TYPE_CONDA: unqueued-receiver-com-spec{data-element=sri_TYPE_CONDA/TYPE_CONDA, handle-invalid=KEEP, init-value=cst_UInt8_init/uint8_init, resync-time=0.0}, required-interface=AR_SIGNALER_SWC/sri_TYPE_CONDA
      rp_ETAT_FEUX_DIRECTION_PREC: unqueued-receiver-com-spec{data-element=ETAT_FEUX_DIRECTION, handle-invalid=KEEP, init-value=cst_UInt8_init/uint8_init, resync-time=0.0}, required-interface=sri_ETAT_FEUX_DIRECTION
      rp_ETAT_PRINCIP_SEV: unqueued-receiver-com-spec{data-element=sri_ETAT_PRINCIP_SEV/ETAT_PRINCIP_SEV, handle-invalid=KEEP, init-value=cst_UInt8_init/uint8_init, resync-time=0.0}, required-interface=AR_SIGNALER_SWC/sri_ETAT_PRINCIP_SEV
      rp_ETAT_COMMODO_CLIGNO: unqueued-receiver-com-spec{data-element=ETAT_COMMODO_CLIGNO, handle-invalid=KEEP, init-value=cst_UInt8_init/uint8_init, resync-time=0.0}, required-interface=sri_ETAT_COMMODO_CLIGNO
      rp_ETAT_RESEAU_ELECTRIQUE: unqueued-receiver-com-spec{data-element=sri_ETAT_RESEAU_ELECTRIQUE/ETAT_RESEAU_ELECTRIQUE, handle-invalid=KEEP, init-value=cst_UInt8_init/uint8_init, resync-time=0.0}, required-interface=AR_SIGNALER_SWC/sri_ETAT_RESEAU_ELECTRIQUE
      rp_MODE_CONFIG_VHL: unqueued-receiver-com-spec{data-element=MODE_CONFIG_VHL, handle-invalid=KEEP, init-value=cst_UInt8_init/uint8_init, resync-time=0.0}, required-interface=sri_MODE_CONFIG_VHL
      rp_DMD_FEUX_DETRESSE: unqueued-receiver-com-spec{data-element=DMD_FEUX_DETRESSE, handle-invalid=KEEP, init-value=cst_Boolean_init/boolean_init, resync-time=0.0}, required-interface=sri_DMD_FEUX_DETRESSE
      rp_OPTION_ALL_WARNING_CHOC: unqueued-receiver-com-spec{data-element=OPTION_ALL_WARNING_CHOC, handle-invalid=KEEP, init-value=cst_Boolean_init/boolean_init, resync-time=0.0}, required-interface=sri_OPTION_ALL_WARNING_CHOC
      rp_CHOC_FEUX_DET: unqueued-receiver-com-spec{data-element=CHOC_FEUX_DET, handle-invalid=KEEP, init-value=cst_Boolean_init/boolean_init, resync-time=0.0}, required-interface=sri_CHOC_FEUX_DET
      rp_INFO_CHOC_PIETON: unqueued-receiver-com-spec{data-element=INFO_CHOC_PIETON, handle-invalid=KEEP, init-value=cst_Boolean_init/boolean_init, resync-time=0.0}, required-interface=sri_INFO_CHOC_PIETON
      rp_VOLONTE_CONDUCTEUR: unqueued-receiver-com-spec{data-element=VOLONTE_CONDUCTEUR, handle-invalid=KEEP, init-value=cst_UInt8_init/uint8_init, resync-time=0.0}, required-interface=sri_VOLONTE_CONDUCTEUR
      rp_DMD_WARNING_FORTE_DECEL: unqueued-receiver-com-spec{data-element=DMD_WARNING_FORTE_DECEL, handle-invalid=KEEP, init-value=cst_Boolean_init/boolean_init, resync-time=0.0}, required-interface=sri_DMD_WARNING_FORTE_DECEL
      rp_OPTION_ALL_WARNING_FORTE_DECEL: unqueued-receiver-com-spec{data-element=OPTION_ALL_WARNING_FORTE_DECEL, handle-invalid=KEEP, init-value=cst_Boolean_init/boolean_init, resync-time=0.0}, required-interface=sri_OPTION_ALL_WARNING_FORTE_DECEL
      rp_FONCTION_SFU_DANS_UCFREIN: unqueued-receiver-com-spec{data-element=sri_FONCTION_SFU_DANS_UCFREIN/FNCT_SFU_UC_FREIN, handle-invalid=KEEP, init-value=cst_Boolean_init/boolean_init, resync-time=0.0}, required-interface=sri_FONCTION_SFU_DANS_UCFREIN
      rp_VITESSE_LONGITUDINALE: unqueued-receiver-com-spec{data-element=sri_VITESSE_LONGITUDINALE/VITESSE_LONGITUDINALE, handle-invalid=KEEP, init-value=cst_UInt16_init/uint16_init, resync-time=0.0}, required-interface=AR_SIGNALER_SWC/sri_VITESSE_LONGITUDINALE
      rp_OPTION_POLICE: unqueued-receiver-com-spec{data-element=OPTION_POLICE, handle-invalid=KEEP, init-value=cst_Boolean_init/boolean_init, resync-time=0.0}, required-interface=sri_OPTION_POLICE
      rp_ETAT_CONDA_OUV_AR: unqueued-receiver-com-spec{data-element=ETAT_CONDA_OUV_AR, handle-invalid=KEEP, init-value=cst_Boolean_init/boolean_init, resync-time=0.0}, required-interface=sri_ETAT_CONDA_OUV_AR
      rp_DMD_LOCAL_TELECMD: unqueued-receiver-com-spec{data-element=sri_DMD_LOCAL_TELECMD/DMD_LOCAL_TELECMD, handle-invalid=KEEP, init-value=cst_Boolean_init/boolean_init, resync-time=0.0}, required-interface=AR_SIGNALER_SWC/sri_DMD_LOCAL_TELECMD
      rp_DEFAUT_CLIGNO_D: unqueued-receiver-com-spec{data-element=DEFAUT_CLIGNO_D, handle-invalid=KEEP, init-value=cst_Boolean_init/boolean_init, resync-time=0.0}, required-interface=sri_DEFAUT_CLIGNO_D
      rp_DEFAUT_CLIGNO_G: unqueued-receiver-com-spec{data-element=DEFAUT_CLIGNO_G, handle-invalid=KEEP, init-value=cst_Boolean_init/boolean_init, resync-time=0.0}, required-interface=sri_DEFAUT_CLIGNO_G
    7 x provide port:
      pp_DMD_FEUX_DETRESSE_STABLE: unqueued-sender-com-spec{data-element=DMD_FEUX_DETRESSE_STABLE, init-value=cst_Boolean_init/boolean_init}, provided-interface=sri_DMD_FEUX_DETRESSE_STABLE
      pp_FREQ_CLIGN: unqueued-sender-com-spec{data-element=FREQ_CLIGN, init-value=cst_UInt16_init/uint16_init}, provided-interface=sri_FREQ_CLIGN
      pp_RC_CLIGN: unqueued-sender-com-spec{data-element=RC_CLIGN, init-value=cst_UInt16_init/uint16_init}, provided-interface=sri_RC_CLIGN
      pp_DMD_SON_VALIDE: unqueued-sender-com-spec{data-element=DMD_SON_VALIDE, init-value=cst_Boolean_init/boolean_init}, provided-interface=sri_DMD_SON_VALIDE
      pp_ECC_CLIGNO_G_mdf: unqueued-sender-com-spec{data-element=ECC_CLIGNO_G_mdf, init-value=cst_Boolean_init/boolean_init}, provided-interface=sri_ECC_CLIGNO_G_mdf
      pp_ECC_CLIGNO_D_mdf: unqueued-sender-com-spec{data-element=ECC_CLIGNO_D_mdf, init-value=cst_Boolean_init/boolean_init}, provided-interface=sri_ECC_CLIGNO_D_mdf
      pp_ECC_PAS_DE_CMD_mdf: unqueued-sender-com-spec{data-element=ECC_PAS_DE_CMD_mdf, init-value=cst_Boolean_init/boolean_init}, provided-interface=sri_ECC_PAS_DE_CMD_mdf
  internal behavior ib_GID_S0: component=GID_S0
    timing event evt_GID_S0: start-on-event=GID_S0, period=0.1
    runnable GID_S0
      21 x data read access:
        dra_ETAT_CONDA: data-element=rp_ETAT_CONDA.ETAT_CONDA
        dra_TYPE_CONDA: data-element=rp_TYPE_CONDA.TYPE_CONDA
        dra_ETAT_FEUX_DIRECTION: data-element=rp_ETAT_FEUX_DIRECTION_PREC.ETAT_FEUX_DIRECTION
        dra_ETAT_PRINCIP_SEV: data-element=rp_ETAT_PRINCIP_SEV.ETAT_PRINCIP_SEV
        dra_ETAT_COMMODO_CLIGNO: data-element=rp_ETAT_COMMODO_CLIGNO.ETAT_COMMODO_CLIGNO
        dra_ETAT_RESEAU_ELECTRIQUE: data-element=rp_ETAT_RESEAU_ELECTRIQUE.ETAT_RESEAU_ELECTRIQUE
        dra_MODE_CONFIG_VHL: data-element=rp_MODE_CONFIG_VHL.MODE_CONFIG_VHL
        dra_DMD_FEUX_DETRESSE: data-element=rp_DMD_FEUX_DETRESSE.DMD_FEUX_DETRESSE
        dra_OPTION_ALL_WARNING_CHOC: data-element=rp_OPTION_ALL_WARNING_CHOC.OPTION_ALL_WARNING_CHOC
        dra_CHOC_FEUX_DET: data-element=rp_CHOC_FEUX_DET.CHOC_FEUX_DET
        dra_INFO_CHOC_PIETON: data-element=rp_INFO_CHOC_PIETON.INFO_CHOC_PIETON
        dra_VOLONTE_CONDUCTEUR: data-element=rp_VOLONTE_CONDUCTEUR.VOLONTE_CONDUCTEUR
        dra_DMD_WARNING_FORTE_DECEL: data-element=rp_DMD_WARNING_FORTE_DECEL.DMD_WARNING_FORTE_DECEL
        dra_OPTION_ALL_WARNING_FORTE_DE: data-element=rp_OPTION_ALL_WARNING_FORTE_DECEL.OPTION_ALL_WARNING_FORTE_DECEL
        dra_FNCT_SFU_UC_FREIN: data-element=rp_FONCTION_SFU_DANS_UCFREIN.FNCT_SFU_UC_FREIN
        dra_VITESSE_LONGITUDINALE: data-element=rp_VITESSE_LONGITUDINALE.VITESSE_LONGITUDINALE
        dra_OPTION_POLICE: data-element=rp_OPTION_POLICE.OPTION_POLICE
        dra_ETAT_CONDA_OUV_AR: data-element=rp_ETAT_CONDA_OUV_AR.ETAT_CONDA_OUV_AR
        dra_DMD_LOCAL_TELECMD: data-element=rp_DMD_LOCAL_TELECMD.DMD_LOCAL_TELECMD
        dra_DEFAUT_CLIGNO_D: data-element=rp_DEFAUT_CLIGNO_D.DEFAUT_CLIGNO_D
        dra_DEFAUT_CLIGNO_G: data-element=rp_DEFAUT_CLIGNO_G.DEFAUT_CLIGNO_G
      7 x data write access:
        dwa_DMD_FEUX_DETRESSE_STABLE: data-element=pp_DMD_FEUX_DETRESSE_STABLE.DMD_FEUX_DETRESSE_STABLE
        dwa_FREQ_CLIGN: data-element=pp_FREQ_CLIGN.FREQ_CLIGN
        dwa_RC_CLIGN: data-element=pp_RC_CLIGN.RC_CLIGN
        dwa_DMD_SON_VALIDE: data-element=pp_DMD_SON_VALIDE.DMD_SON_VALIDE
        dwa_ECC_CLIGNO_G_mdf: data-element=pp_ECC_CLIGNO_G_mdf.ECC_CLIGNO_G_mdf
        dwa_ECC_CLIGNO_D_mdf: data-element=pp_ECC_CLIGNO_D_mdf.ECC_CLIGNO_D_mdf
        dwa_ECC_PAS_DE_CMD_mdf: data-element=pp_ECC_PAS_DE_CMD_mdf.ECC_PAS_DE_CMD_mdf
  10 x sender receiver interface:
    sri_ETAT_CONDA
      data ETAT_CONDA: type=AR_SIGNALER_SWC/UInt8
    sri_TYPE_CONDA
      data TYPE_CONDA: type=AR_SIGNALER_SWC/UInt8
    sri_ETAT_COMMODO_CLIGNO
      data ETAT_COMMODO_CLIGNO: type=AR_SIGNALER_SWC/UInt8
    sri_CHOC_FEUX_DET
      data CHOC_FEUX_DET: type=AR_SIGNALER_SWC/Boolean
    sri_INFO_CHOC_PIETON
      data INFO_CHOC_PIETON: type=AR_SIGNALER_SWC/Boolean
    sri_VOLONTE_CONDUCTEUR
      data VOLONTE_CONDUCTEUR: type=AR_SIGNALER_SWC/UInt8
    sri_DMD_WARNING_FORTE_DECEL
      data DMD_WARNING_FORTE_DECEL: type=AR_SIGNALER_SWC/Boolean
    sri_FONCTION_SFU_DANS_UCFREIN
      data FNCT_SFU_UC_FREIN: type=AR_SIGNALER_SWC/Boolean
    sri_ETAT_CONDA_OUV_AR
      data ETAT_CONDA_OUV_AR: type=AR_SIGNALER_SWC/Boolean
    sri_DMD_LOCAL_TELECMD
      data DMD_LOCAL_TELECMD: type=AR_SIGNALER_SWC/Boolean
  swc implementation implem_GID_S0: programming-language=C, behavior=ib_GID_S0
    code-descriptors:
      code implem_GID_S0: type=SRC
        xfile GID_S0.c: url=Src_C/GID_S0.c
  application software component type GERER_FX_ABAR
    9 x require port:
      rp_ETAT_PRINCIP_SEV: unqueued-receiver-com-spec{data-element=sri_ETAT_PRINCIP_SEV/ETAT_PRINCIP_SEV, handle-invalid=KEEP, init-value=cst_UInt8_init/uint8_init, resync-time=0.0}, required-interface=AR_SIGNALER_SWC/sri_ETAT_PRINCIP_SEV
      rp_ETAT_RESEAU_ELECTRIQUE: unqueued-receiver-com-spec{data-element=sri_ETAT_RESEAU_ELECTRIQUE/ETAT_RESEAU_ELECTRIQUE, handle-invalid=KEEP, init-value=cst_UInt8_init/uint8_init, resync-time=0.0}, required-interface=AR_SIGNALER_SWC/sri_ETAT_RESEAU_ELECTRIQUE
      rp_DMD_ANTIBROUILLARD: unqueued-receiver-com-spec{data-element=DMD_ANTIBROUILLARD, handle-invalid=KEEP, init-value=cst_UInt8_init/uint8_init, resync-time=0.0}, required-interface=sri_DMD_ANTIBROUILLARD
      rp_ETAT_FEUX_DIURNES: unqueued-receiver-com-spec{data-element=sri_ETAT_FEUX_DIURNES/ETAT_FEUX_DIURNES, handle-invalid=KEEP, init-value=cst_Boolean_init/boolean_init, resync-time=0.0}, required-interface=AR_SIGNALER_SWC/sri_ETAT_FEUX_DIURNES
      rp_ETAT_FEUX_POSITION: unqueued-receiver-com-spec{data-element=sri_ETAT_FEUX_POSITION/ETAT_FEUX_POSITION, handle-invalid=KEEP, init-value=cst_Boolean_init/boolean_init, resync-time=0.0}, required-interface=AR_SIGNALER_SWC/sri_ETAT_FEUX_POSITION
      rp_ETAT_FEUX_CROISEMENT: unqueued-receiver-com-spec{data-element=ETAT_FEUX_CROISEMENT, handle-invalid=KEEP, init-value=cst_Boolean_init/boolean_init, resync-time=0.0}, required-interface=sri_ETAT_FEUX_CROISEMENT
      rp_ETAT_FEUX_ROUTE: unqueued-receiver-com-spec{data-element=ETAT_FEUX_ROUTE, handle-invalid=KEEP, init-value=cst_Boolean_init/boolean_init, resync-time=0.0}, required-interface=sri_ETAT_FEUX_ROUTE
      rp_ETAT_ANTIBR_AV: unqueued-receiver-com-spec{data-element=ETAT_ANTIBR_AV, handle-invalid=KEEP, init-value=cst_Boolean_init/boolean_init, resync-time=0.0}, required-interface=sri_ETAT_ANTIBR_AV
      rp_PRESENCE_ANTIBR_AR: unqueued-receiver-com-spec{data-element=PRESENCE_ANTIBR_AR, handle-invalid=KEEP, init-value=cst_Boolean_init/boolean_init, resync-time=0.0}, required-interface=sri_PRESENCE_ANTIBR_AR
    provide port pp_CMD_ANTIBR_AR: unqueued-sender-com-spec{data-element=CMD_ANTIBR_AR, init-value=cst_Boolean_init/boolean_init}, provided-interface=sri_CMD_ANTIBR_AR
    provide port pp_ETAT_ANTIBR_AR: unqueued-sender-com-spec{data-element=ETAT_ANTIBR_AR, init-value=cst_Boolean_init/boolean_init}, provided-interface=sri_ETAT_ANTIBR_AR
    provide port pp_P_TEM_SIGN_FX_ABAR: unqueued-sender-com-spec{data-element=P_TEM_SIGN_FX_ABAR, init-value=cst_Boolean_init/boolean_init}, provided-interface=sri_P_TEM_SIGN_FX_ABAR
  internal behavior ib_GERER_FX_ABAR: component=GERER_FX_ABAR
    timing event evt_GERER_FX_ABAR: start-on-event=GERER_FX_ABAR, period=0.1
    runnable GERER_FX_ABAR
      9 x data read access:
        dra_ETAT_PRINCIP_SEV: data-element=rp_ETAT_PRINCIP_SEV.ETAT_PRINCIP_SEV
        dra_ETAT_RESEAU_ELECTRIQUE: data-element=rp_ETAT_RESEAU_ELECTRIQUE.ETAT_RESEAU_ELECTRIQUE
        dra_DMD_ANTIBROUILLARD: data-element=rp_DMD_ANTIBROUILLARD.DMD_ANTIBROUILLARD
        dra_ETAT_FEUX_DIURNES: data-element=rp_ETAT_FEUX_DIURNES.ETAT_FEUX_DIURNES
        dra_ETAT_FEUX_POSITION: data-element=rp_ETAT_FEUX_POSITION.ETAT_FEUX_POSITION
        dra_ETAT_FEUX_CROISEMENT: data-element=rp_ETAT_FEUX_CROISEMENT.ETAT_FEUX_CROISEMENT
        dra_ETAT_FEUX_ROUTE: data-element=rp_ETAT_FEUX_ROUTE.ETAT_FEUX_ROUTE
        dra_ETAT_ANTIBR_AV: data-element=rp_ETAT_ANTIBR_AV.ETAT_ANTIBR_AV
        dra_PRESENCE_ANTIBR_AR: data-element=rp_PRESENCE_ANTIBR_AR.PRESENCE_ANTIBR_AR
      data write access dwa_CMD_ANTIBR_AR: data-element=pp_CMD_ANTIBR_AR.CMD_ANTIBR_AR
      data write access dwa_ETAT_ANTIBR_AR: data-element=pp_ETAT_ANTIBR_AR.ETAT_ANTIBR_AR
      data write access dwa_P_TEM_SIGN_FX_ABAR: data-element=pp_P_TEM_SIGN_FX_ABAR.P_TEM_SIGN_FX_ABAR
  4 x sender receiver interface:
    sri_ETAT_FEUX_CROISEMENT
      data ETAT_FEUX_CROISEMENT: type=AR_SIGNALER_SWC/Boolean
    sri_ETAT_FEUX_ROUTE
      data ETAT_FEUX_ROUTE: type=AR_SIGNALER_SWC/Boolean
    sri_CMD_ANTIBR_AR
      data CMD_ANTIBR_AR: type=AR_SIGNALER_SWC/Boolean
    sri_P_TEM_SIGN_FX_ABAR
      data P_TEM_SIGN_FX_ABAR: type=AR_SIGNALER_SWC/Boolean
  swc implementation implem_GERER_FX_ABAR: programming-language=C, behavior=ib_GERER_FX_ABAR
    code-descriptors:
      code implem_GERER_FX_ABAR: type=SRC
        xfile GERER_FX_ABAR.c: url=Src_C/GERER_FX_ABAR.c
  sender receiver interface sri_FNCT_SFU_UC_FREIN
    data FNCT_SFU_UC_FREIN: type=AR_SIGNALER_SWC/Boolean
